VERSION ""

NS_ :

BS_:

BU_: ESR
VAL_TABLE_ VOLVO_SHORT_TRACK_PLANT 1 "Gent" 0 "Torslanda" ;
VAL_TABLE_ Grating_Lobe 1 "Detected" 0 "Not_Detected" ;
VAL_TABLE_ GroupingChanged 1 "GroupingChanged" 0 "GroupingUnchanged" ;
VAL_TABLE_ Oncoming 1 "Oncoming" 0 "NotOncoming" ;
VAL_TABLE_ UPDATED 1 "Updated" 0 "Not_Updated" ;
VAL_TABLE_ FOUND_TARGET 1 "Found" 0 "Not_Found" ;
VAL_TABLE_ FACTORY_ALIGN_STATUS 5 "FAIL_VAR_TOO_LARGE" 4 "FAIL_DEV_TOO_LARGE" 3 "FAIL_NO_TARGET" 2 "SUCCESS" 1 "BUSY" 0 "OFF" ;
VAL_TABLE_ RECOMMEND 1 "Recommend" 0 "Not_Recommend" ;
VAL_TABLE_ SA_TYPE 1 "VOLVO_SHORT_TRACK" 0 "AUTO_OR_DEALER" ;
VAL_TABLE_ ENABLE 1 "Enabled" 0 "Disabled" ;
VAL_TABLE_ CONVERGED 1 "Converged" 0 "Not_Converged" ;
VAL_TABLE_ WHEEL_SLIP 3 "Invalid_3" 2 "Traction_Slip_Control" 1 "Brake_Slip_Control" 0 "No_Control" ;
VAL_TABLE_ TURN_SIGNAL_STATUS 3 "Invalid_3" 2 "Right" 1 "Left" 0 "Off" ;
VAL_TABLE_ DISABLE 1 "Disabled" 0 "Enabled" ;
VAL_TABLE_ SYSTEM_POWER_MODE 7 "7invalid" 6 "TEST" 5 "HOST_SHUTDOWN" 4 "DSP_OFF" 3 "DSP_SHUTDOWN" 2 "RADIATE_ON" 1 "RADIATE_OFF" 0 "DSP_INIT" ;
VAL_TABLE_ Water_Spray_Detected 1 "Spray" 0 "No_Spray" ;
VAL_TABLE_ Bridge 1 "Bridge" 0 "Not_Bridge" ;
VAL_TABLE_ MED_RANGE_MODE 3 "Both_MR_LR_Update" 2 "LR_Update_Only" 1 "MR_Update_Only" 0 "No_MR_LR_Update" ;
VAL_TABLE_ Interface_Version 15 "zInvalid0F" 14 "zInvalid0E" 13 "zInvalid0D" 12 "zInvalid0C" 11 "zInvalid0B" 10 "zInvalid0A" 9 "zInvalid09" 8 "zInvalid08" 7 "zInvalid07" 6 "zInvalid06" 5 "zInvalid05" 4 "zInvalid04" 3 "zInvalid03" 2 "zInvalid02" 1 "ADP_DV1" 0 "TDP" ;
VAL_TABLE_ SIM_STATUS 3 "Coasted" 2 "Updated" 1 "New" 0 "Invalid" ;
VAL_TABLE_ SIM_TRACK_ID 2 "Target_2" 1 "Target_1" 0 "No_Target" ;
VAL_TABLE_ SIM_FUNCTION 7 "All_Stat_RI_FCW_CMbB" 6 "All_Moving_ACC_FCW_CMbB" 5 "CMbB_Stat" 4 "CMbB_Move" 3 "FCW_Stat" 2 "FCW_Move" 1 "RI" 0 "ACC" ;
VAL_TABLE_ UPSIDE_DOWN 1 "Upside_Down" 0 "Right_Side_Up" ;
VAL_TABLE_ MR_LR_MODE 3 "Output MR and LR tracks" 2 "Output only LR-range tracks" 1 "Output only MR-range tracks" 0 "Reserved" ;
VAL_TABLE_ GROUP 3 "Group4" 2 "Group3" 1 "Group2" 0 "Group1" ;
VAL_TABLE_ NODETECT_DETECT 1 "Detect" 0 "No_Detect" ;
VAL_TABLE_ TRACK_STATUS 7 "New_Coasted_Target" 6 "Invalid_Coasted_Target" 5 "Merged_Target" 4 "Coasted_Target" 3 "Updated_Target" 2 "New_Updated_Target" 1 "New_Target" 0 "No_Target" ;
VAL_TABLE_ NOTCROSSING_CROSSING 1 "Crossing" 0 "Not_Crossing" ;
VAL_TABLE_ NOTMOVABLE_MOVABLE 1 "Movable" 0 "Not_Movable" ;
VAL_TABLE_ STATIONARY_MOVING 1 "Moving" 0 "Stationary" ;
VAL_TABLE_ NOTOVERTEMP_OVERTEMP 1 "OverTemp" 0 "Not OverTemp" ;
VAL_TABLE_ NOTBLOCKED_BLOCKED 1 "Blocked" 0 "Not Blocked" ;
VAL_TABLE_ NOTFAIL_FAIL 1 "Failed" 0 "Not Failed" ;
VAL_TABLE_ UNGROUPED_GROUPED 3 "Group_Moving_Stationary" 2 "Group_Stationary_Only" 1 "Group_Moving_Only" 0 "No_Grouping" ;
VAL_TABLE_ FILTERED_RAW 1 "Raw" 0 "Filtered" ;
VAL_TABLE_ OFF_ON 1 "On" 0 "Off" ;
VAL_TABLE_ SW_SIGN 1 "Clockwise" 0 "Counterclockwise" ;
VAL_TABLE_ VALIDITY 1 "Valid" 0 "Invalid" ;
VAL_TABLE_ VEHICLE_SPEED_DIRECTION 1 "Reverse" 0 "Forward" ;

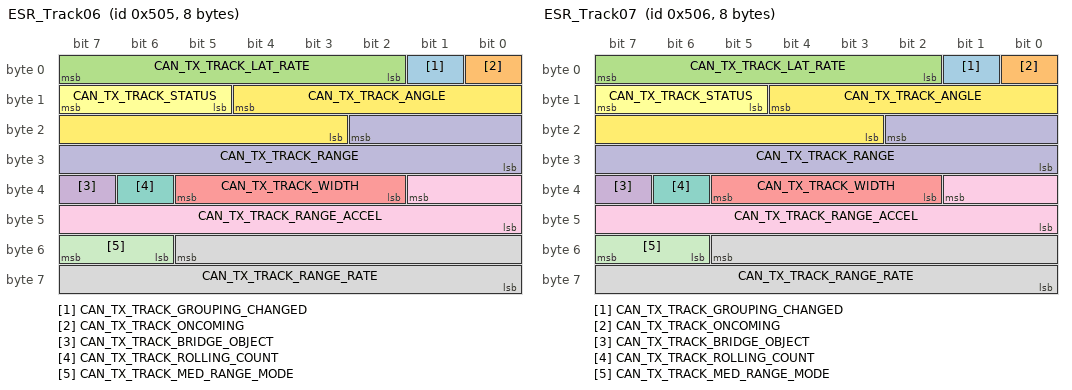
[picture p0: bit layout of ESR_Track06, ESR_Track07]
BO_ 1285 ESR_Track06: 8 Vector__XXX
 SG_ CAN_TX_TRACK_GROUPING_CHANGED : 1|1@0+ (1,0) [0|0] ""  ESR
 SG_ CAN_TX_TRACK_ONCOMING : 0|1@0+ (1,0) [0|0] ""  ESR
 SG_ CAN_TX_TRACK_LAT_RATE : 7|6@0- (0.25,0) [-8|7.75] ""  ESR
 SG_ CAN_TX_TRACK_BRIDGE_OBJECT : 39|1@0+ (1,0) [0|0] ""  ESR
 SG_ CAN_TX_TRACK_WIDTH : 37|4@0+ (0.5,0) [0|7.5] "m"  ESR
 SG_ CAN_TX_TRACK_STATUS : 15|3@0+ (1,0) [0|7] ""  ESR
 SG_ CAN_TX_TRACK_ROLLING_COUNT : 38|1@0+ (1,0) [0|1] ""  ESR
 SG_ CAN_TX_TRACK_RANGE_RATE : 53|14@0- (0.01,0) [-81.92|81.91] "m/s"  ESR
 SG_ CAN_TX_TRACK_RANGE_ACCEL : 33|10@0- (0.05,0) [-25.6|25.55] "m/s/s"  ESR
 SG_ CAN_TX_TRACK_RANGE : 18|11@0+ (0.1,0) [0|204.7] "m"  ESR
 SG_ CAN_TX_TRACK_MED_RANGE_MODE : 55|2@0+ (1,0) [0|3] ""  ESR
 SG_ CAN_TX_TRACK_ANGLE : 12|10@0- (0.1,0) [-51.2|51.1] "deg"  ESR

BO_ 1286 ESR_Track07: 8 Vector__XXX
 SG_ CAN_TX_TRACK_GROUPING_CHANGED : 1|1@0+ (1,0) [0|0] ""  ESR
 SG_ CAN_TX_TRACK_ONCOMING : 0|1@0+ (1,0) [0|0] ""  ESR
 SG_ CAN_TX_TRACK_LAT_RATE : 7|6@0- (0.25,0) [-8|7.75] ""  ESR
 SG_ CAN_TX_TRACK_BRIDGE_OBJECT : 39|1@0+ (1,0) [0|0] ""  ESR
 SG_ CAN_TX_TRACK_WIDTH : 37|4@0+ (0.5,0) [0|7.5] "m"  ESR
 SG_ CAN_TX_TRACK_STATUS : 15|3@0+ (1,0) [0|7] ""  ESR
 SG_ CAN_TX_TRACK_ROLLING_COUNT : 38|1@0+ (1,0) [0|1] ""  ESR
 SG_ CAN_TX_TRACK_RANGE_RATE : 53|14@0- (0.01,0) [-81.92|81.91] "m/s"  ESR
 SG_ CAN_TX_TRACK_RANGE_ACCEL : 33|10@0- (0.05,0) [-25.6|25.55] "m/s/s"  ESR
 SG_ CAN_TX_TRACK_RANGE : 18|11@0+ (0.1,0) [0|204.7] "m"  ESR
 SG_ CAN_TX_TRACK_MED_RANGE_MODE : 55|2@0+ (1,0) [0|3] ""  ESR
 SG_ CAN_TX_TRACK_ANGLE : 12|10@0- (0.1,0) [-51.2|51.1] "deg"  ESR

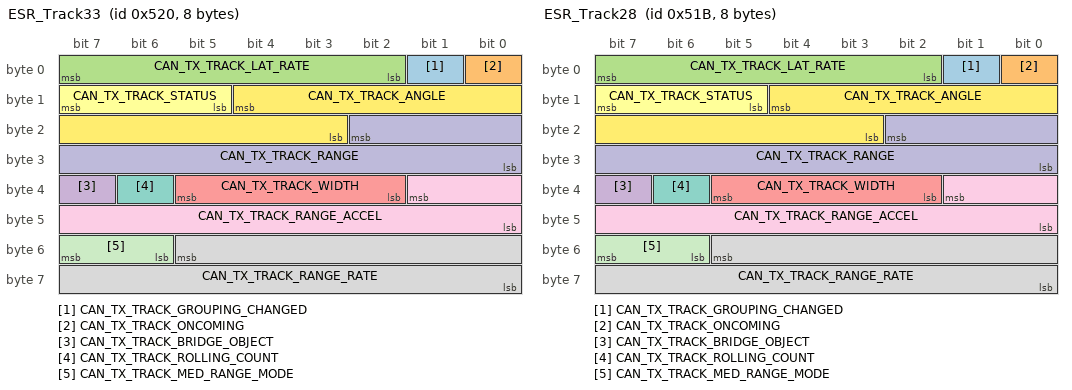
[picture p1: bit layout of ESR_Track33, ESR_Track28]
BO_ 1312 ESR_Track33: 8 Vector__XXX
 SG_ CAN_TX_TRACK_GROUPING_CHANGED : 1|1@0+ (1,0) [0|0] ""  ESR
 SG_ CAN_TX_TRACK_ONCOMING : 0|1@0+ (1,0) [0|0] ""  ESR
 SG_ CAN_TX_TRACK_LAT_RATE : 7|6@0- (0.25,0) [-8|7.75] ""  ESR
 SG_ CAN_TX_TRACK_BRIDGE_OBJECT : 39|1@0+ (1,0) [0|0] ""  ESR
 SG_ CAN_TX_TRACK_WIDTH : 37|4@0+ (0.5,0) [0|7.5] "m"  ESR
 SG_ CAN_TX_TRACK_STATUS : 15|3@0+ (1,0) [0|7] ""  ESR
 SG_ CAN_TX_TRACK_ROLLING_COUNT : 38|1@0+ (1,0) [0|1] ""  ESR
 SG_ CAN_TX_TRACK_RANGE_RATE : 53|14@0- (0.01,0) [-81.92|81.91] "m/s"  ESR
 SG_ CAN_TX_TRACK_RANGE_ACCEL : 33|10@0- (0.05,0) [-25.6|25.55] "m/s/s"  ESR
 SG_ CAN_TX_TRACK_RANGE : 18|11@0+ (0.1,0) [0|204.7] "m"  ESR
 SG_ CAN_TX_TRACK_MED_RANGE_MODE : 55|2@0+ (1,0) [0|3] ""  ESR
 SG_ CAN_TX_TRACK_ANGLE : 12|10@0- (0.1,0) [-51.2|51.1] "deg"  ESR

BO_ 1307 ESR_Track28: 8 Vector__XXX
 SG_ CAN_TX_TRACK_GROUPING_CHANGED : 1|1@0+ (1,0) [0|0] ""  ESR
 SG_ CAN_TX_TRACK_ONCOMING : 0|1@0+ (1,0) [0|0] ""  ESR
 SG_ CAN_TX_TRACK_LAT_RATE : 7|6@0- (0.25,0) [-8|7.75] ""  ESR
 SG_ CAN_TX_TRACK_BRIDGE_OBJECT : 39|1@0+ (1,0) [0|0] ""  ESR
 SG_ CAN_TX_TRACK_WIDTH : 37|4@0+ (0.5,0) [0|7.5] "m"  ESR
 SG_ CAN_TX_TRACK_STATUS : 15|3@0+ (1,0) [0|7] ""  ESR
 SG_ CAN_TX_TRACK_ROLLING_COUNT : 38|1@0+ (1,0) [0|1] ""  ESR
 SG_ CAN_TX_TRACK_RANGE_RATE : 53|14@0- (0.01,0) [-81.92|81.91] "m/s"  ESR
 SG_ CAN_TX_TRACK_RANGE_ACCEL : 33|10@0- (0.05,0) [-25.6|25.55] "m/s/s"  ESR
 SG_ CAN_TX_TRACK_RANGE : 18|11@0+ (0.1,0) [0|204.7] "m"  ESR
 SG_ CAN_TX_TRACK_MED_RANGE_MODE : 55|2@0+ (1,0) [0|3] ""  ESR
 SG_ CAN_TX_TRACK_ANGLE : 12|10@0- (0.1,0) [-51.2|51.1] "deg"  ESR

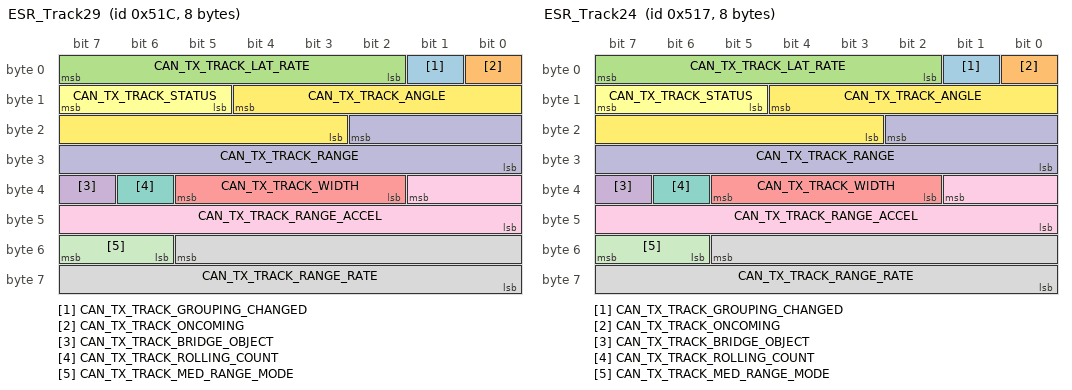
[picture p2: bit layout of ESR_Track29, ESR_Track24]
BO_ 1308 ESR_Track29: 8 Vector__XXX
 SG_ CAN_TX_TRACK_GROUPING_CHANGED : 1|1@0+ (1,0) [0|0] ""  ESR
 SG_ CAN_TX_TRACK_ONCOMING : 0|1@0+ (1,0) [0|0] ""  ESR
 SG_ CAN_TX_TRACK_LAT_RATE : 7|6@0- (0.25,0) [-8|7.75] ""  ESR
 SG_ CAN_TX_TRACK_BRIDGE_OBJECT : 39|1@0+ (1,0) [0|0] ""  ESR
 SG_ CAN_TX_TRACK_WIDTH : 37|4@0+ (0.5,0) [0|7.5] "m"  ESR
 SG_ CAN_TX_TRACK_STATUS : 15|3@0+ (1,0) [0|7] ""  ESR
 SG_ CAN_TX_TRACK_ROLLING_COUNT : 38|1@0+ (1,0) [0|1] ""  ESR
 SG_ CAN_TX_TRACK_RANGE_RATE : 53|14@0- (0.01,0) [-81.92|81.91] "m/s"  ESR
 SG_ CAN_TX_TRACK_RANGE_ACCEL : 33|10@0- (0.05,0) [-25.6|25.55] "m/s/s"  ESR
 SG_ CAN_TX_TRACK_RANGE : 18|11@0+ (0.1,0) [0|204.7] "m"  ESR
 SG_ CAN_TX_TRACK_MED_RANGE_MODE : 55|2@0+ (1,0) [0|3] ""  ESR
 SG_ CAN_TX_TRACK_ANGLE : 12|10@0- (0.1,0) [-51.2|51.1] "deg"  ESR

BO_ 1303 ESR_Track24: 8 Vector__XXX
 SG_ CAN_TX_TRACK_GROUPING_CHANGED : 1|1@0+ (1,0) [0|0] ""  ESR
 SG_ CAN_TX_TRACK_ONCOMING : 0|1@0+ (1,0) [0|0] ""  ESR
 SG_ CAN_TX_TRACK_LAT_RATE : 7|6@0- (0.25,0) [-8|7.75] ""  ESR
 SG_ CAN_TX_TRACK_BRIDGE_OBJECT : 39|1@0+ (1,0) [0|0] ""  ESR
 SG_ CAN_TX_TRACK_WIDTH : 37|4@0+ (0.5,0) [0|7.5] "m"  ESR
 SG_ CAN_TX_TRACK_STATUS : 15|3@0+ (1,0) [0|7] ""  ESR
 SG_ CAN_TX_TRACK_ROLLING_COUNT : 38|1@0+ (1,0) [0|1] ""  ESR
 SG_ CAN_TX_TRACK_RANGE_RATE : 53|14@0- (0.01,0) [-81.92|81.91] "m/s"  ESR
 SG_ CAN_TX_TRACK_RANGE_ACCEL : 33|10@0- (0.05,0) [-25.6|25.55] "m/s/s"  ESR
 SG_ CAN_TX_TRACK_RANGE : 18|11@0+ (0.1,0) [0|204.7] "m"  ESR
 SG_ CAN_TX_TRACK_MED_RANGE_MODE : 55|2@0+ (1,0) [0|3] ""  ESR
 SG_ CAN_TX_TRACK_ANGLE : 12|10@0- (0.1,0) [-51.2|51.1] "deg"  ESR

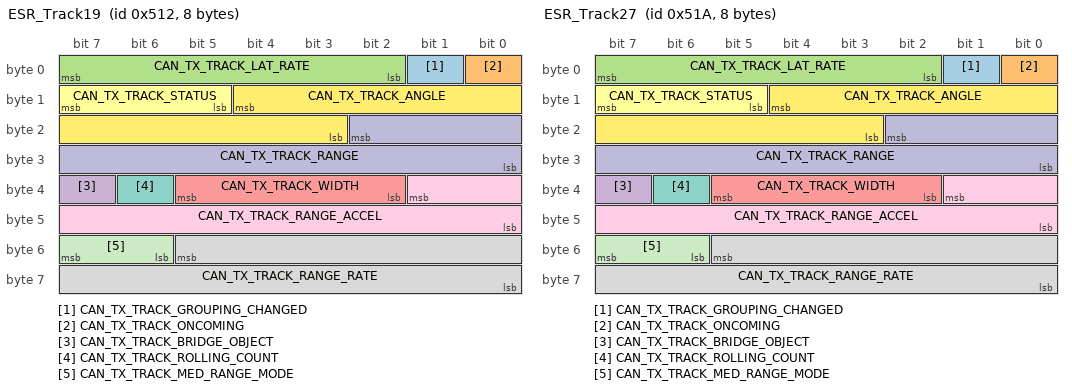
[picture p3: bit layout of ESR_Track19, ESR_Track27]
BO_ 1298 ESR_Track19: 8 Vector__XXX
 SG_ CAN_TX_TRACK_GROUPING_CHANGED : 1|1@0+ (1,0) [0|0] ""  ESR
 SG_ CAN_TX_TRACK_ONCOMING : 0|1@0+ (1,0) [0|0] ""  ESR
 SG_ CAN_TX_TRACK_LAT_RATE : 7|6@0- (0.25,0) [-8|7.75] ""  ESR
 SG_ CAN_TX_TRACK_BRIDGE_OBJECT : 39|1@0+ (1,0) [0|0] ""  ESR
 SG_ CAN_TX_TRACK_WIDTH : 37|4@0+ (0.5,0) [0|7.5] "m"  ESR
 SG_ CAN_TX_TRACK_STATUS : 15|3@0+ (1,0) [0|7] ""  ESR
 SG_ CAN_TX_TRACK_ROLLING_COUNT : 38|1@0+ (1,0) [0|1] ""  ESR
 SG_ CAN_TX_TRACK_RANGE_RATE : 53|14@0- (0.01,0) [-81.92|81.91] "m/s"  ESR
 SG_ CAN_TX_TRACK_RANGE_ACCEL : 33|10@0- (0.05,0) [-25.6|25.55] "m/s/s"  ESR
 SG_ CAN_TX_TRACK_RANGE : 18|11@0+ (0.1,0) [0|204.7] "m"  ESR
 SG_ CAN_TX_TRACK_MED_RANGE_MODE : 55|2@0+ (1,0) [0|3] ""  ESR
 SG_ CAN_TX_TRACK_ANGLE : 12|10@0- (0.1,0) [-51.2|51.1] "deg"  ESR

BO_ 1306 ESR_Track27: 8 Vector__XXX
 SG_ CAN_TX_TRACK_GROUPING_CHANGED : 1|1@0+ (1,0) [0|0] ""  ESR
 SG_ CAN_TX_TRACK_ONCOMING : 0|1@0+ (1,0) [0|0] ""  ESR
 SG_ CAN_TX_TRACK_LAT_RATE : 7|6@0- (0.25,0) [-8|7.75] ""  ESR
 SG_ CAN_TX_TRACK_BRIDGE_OBJECT : 39|1@0+ (1,0) [0|0] ""  ESR
 SG_ CAN_TX_TRACK_WIDTH : 37|4@0+ (0.5,0) [0|7.5] "m"  ESR
 SG_ CAN_TX_TRACK_STATUS : 15|3@0+ (1,0) [0|7] ""  ESR
 SG_ CAN_TX_TRACK_ROLLING_COUNT : 38|1@0+ (1,0) [0|1] ""  ESR
 SG_ CAN_TX_TRACK_RANGE_RATE : 53|14@0- (0.01,0) [-81.92|81.91] "m/s"  ESR
 SG_ CAN_TX_TRACK_RANGE_ACCEL : 33|10@0- (0.05,0) [-25.6|25.55] "m/s/s"  ESR
 SG_ CAN_TX_TRACK_RANGE : 18|11@0+ (0.1,0) [0|204.7] "m"  ESR
 SG_ CAN_TX_TRACK_MED_RANGE_MODE : 55|2@0+ (1,0) [0|3] ""  ESR
 SG_ CAN_TX_TRACK_ANGLE : 12|10@0- (0.1,0) [-51.2|51.1] "deg"  ESR

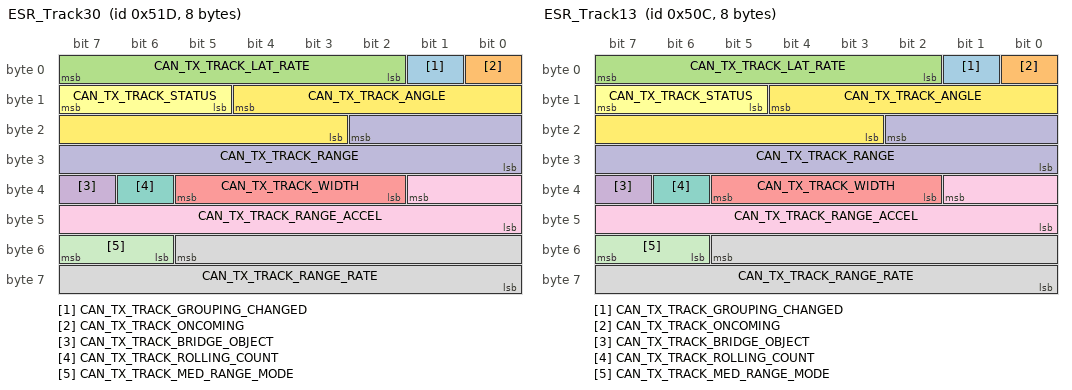
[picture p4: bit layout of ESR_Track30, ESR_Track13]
BO_ 1309 ESR_Track30: 8 Vector__XXX
 SG_ CAN_TX_TRACK_GROUPING_CHANGED : 1|1@0+ (1,0) [0|0] ""  ESR
 SG_ CAN_TX_TRACK_ONCOMING : 0|1@0+ (1,0) [0|0] ""  ESR
 SG_ CAN_TX_TRACK_LAT_RATE : 7|6@0- (0.25,0) [-8|7.75] ""  ESR
 SG_ CAN_TX_TRACK_BRIDGE_OBJECT : 39|1@0+ (1,0) [0|0] ""  ESR
 SG_ CAN_TX_TRACK_WIDTH : 37|4@0+ (0.5,0) [0|7.5] "m"  ESR
 SG_ CAN_TX_TRACK_STATUS : 15|3@0+ (1,0) [0|7] ""  ESR
 SG_ CAN_TX_TRACK_ROLLING_COUNT : 38|1@0+ (1,0) [0|1] ""  ESR
 SG_ CAN_TX_TRACK_RANGE_RATE : 53|14@0- (0.01,0) [-81.92|81.91] "m/s"  ESR
 SG_ CAN_TX_TRACK_RANGE_ACCEL : 33|10@0- (0.05,0) [-25.6|25.55] "m/s/s"  ESR
 SG_ CAN_TX_TRACK_RANGE : 18|11@0+ (0.1,0) [0|204.7] "m"  ESR
 SG_ CAN_TX_TRACK_MED_RANGE_MODE : 55|2@0+ (1,0) [0|3] ""  ESR
 SG_ CAN_TX_TRACK_ANGLE : 12|10@0- (0.1,0) [-51.2|51.1] "deg"  ESR

BO_ 1292 ESR_Track13: 8 Vector__XXX
 SG_ CAN_TX_TRACK_GROUPING_CHANGED : 1|1@0+ (1,0) [0|0] ""  ESR
 SG_ CAN_TX_TRACK_ONCOMING : 0|1@0+ (1,0) [0|0] ""  ESR
 SG_ CAN_TX_TRACK_LAT_RATE : 7|6@0- (0.25,0) [-8|7.75] ""  ESR
 SG_ CAN_TX_TRACK_BRIDGE_OBJECT : 39|1@0+ (1,0) [0|0] ""  ESR
 SG_ CAN_TX_TRACK_WIDTH : 37|4@0+ (0.5,0) [0|7.5] "m"  ESR
 SG_ CAN_TX_TRACK_STATUS : 15|3@0+ (1,0) [0|7] ""  ESR
 SG_ CAN_TX_TRACK_ROLLING_COUNT : 38|1@0+ (1,0) [0|1] ""  ESR
 SG_ CAN_TX_TRACK_RANGE_RATE : 53|14@0- (0.01,0) [-81.92|81.91] "m/s"  ESR
 SG_ CAN_TX_TRACK_RANGE_ACCEL : 33|10@0- (0.05,0) [-25.6|25.55] "m/s/s"  ESR
 SG_ CAN_TX_TRACK_RANGE : 18|11@0+ (0.1,0) [0|204.7] "m"  ESR
 SG_ CAN_TX_TRACK_MED_RANGE_MODE : 55|2@0+ (1,0) [0|3] ""  ESR
 SG_ CAN_TX_TRACK_ANGLE : 12|10@0- (0.1,0) [-51.2|51.1] "deg"  ESR

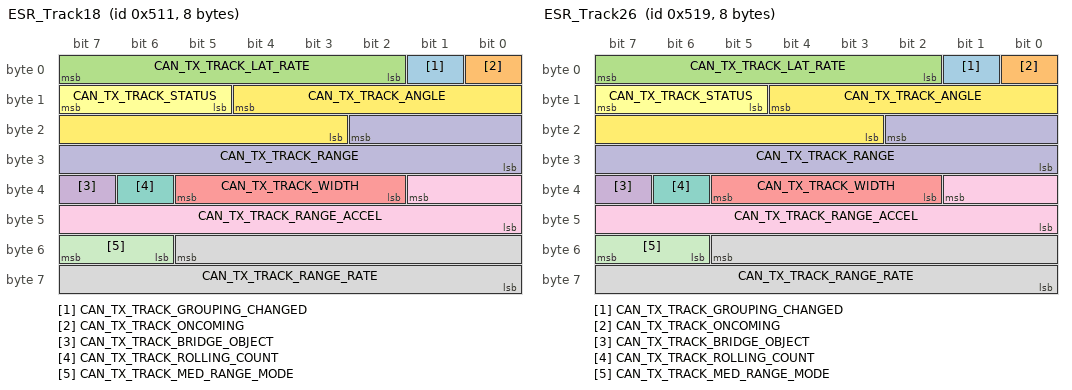
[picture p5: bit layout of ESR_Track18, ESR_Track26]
BO_ 1297 ESR_Track18: 8 Vector__XXX
 SG_ CAN_TX_TRACK_GROUPING_CHANGED : 1|1@0+ (1,0) [0|0] ""  ESR
 SG_ CAN_TX_TRACK_ONCOMING : 0|1@0+ (1,0) [0|0] ""  ESR
 SG_ CAN_TX_TRACK_LAT_RATE : 7|6@0- (0.25,0) [-8|7.75] ""  ESR
 SG_ CAN_TX_TRACK_BRIDGE_OBJECT : 39|1@0+ (1,0) [0|0] ""  ESR
 SG_ CAN_TX_TRACK_WIDTH : 37|4@0+ (0.5,0) [0|7.5] "m"  ESR
 SG_ CAN_TX_TRACK_STATUS : 15|3@0+ (1,0) [0|7] ""  ESR
 SG_ CAN_TX_TRACK_ROLLING_COUNT : 38|1@0+ (1,0) [0|1] ""  ESR
 SG_ CAN_TX_TRACK_RANGE_RATE : 53|14@0- (0.01,0) [-81.92|81.91] "m/s"  ESR
 SG_ CAN_TX_TRACK_RANGE_ACCEL : 33|10@0- (0.05,0) [-25.6|25.55] "m/s/s"  ESR
 SG_ CAN_TX_TRACK_RANGE : 18|11@0+ (0.1,0) [0|204.7] "m"  ESR
 SG_ CAN_TX_TRACK_MED_RANGE_MODE : 55|2@0+ (1,0) [0|3] ""  ESR
 SG_ CAN_TX_TRACK_ANGLE : 12|10@0- (0.1,0) [-51.2|51.1] "deg"  ESR

BO_ 1305 ESR_Track26: 8 Vector__XXX
 SG_ CAN_TX_TRACK_GROUPING_CHANGED : 1|1@0+ (1,0) [0|0] ""  ESR
 SG_ CAN_TX_TRACK_ONCOMING : 0|1@0+ (1,0) [0|0] ""  ESR
 SG_ CAN_TX_TRACK_LAT_RATE : 7|6@0- (0.25,0) [-8|7.75] ""  ESR
 SG_ CAN_TX_TRACK_BRIDGE_OBJECT : 39|1@0+ (1,0) [0|0] ""  ESR
 SG_ CAN_TX_TRACK_WIDTH : 37|4@0+ (0.5,0) [0|7.5] "m"  ESR
 SG_ CAN_TX_TRACK_STATUS : 15|3@0+ (1,0) [0|7] ""  ESR
 SG_ CAN_TX_TRACK_ROLLING_COUNT : 38|1@0+ (1,0) [0|1] ""  ESR
 SG_ CAN_TX_TRACK_RANGE_RATE : 53|14@0- (0.01,0) [-81.92|81.91] "m/s"  ESR
 SG_ CAN_TX_TRACK_RANGE_ACCEL : 33|10@0- (0.05,0) [-25.6|25.55] "m/s/s"  ESR
 SG_ CAN_TX_TRACK_RANGE : 18|11@0+ (0.1,0) [0|204.7] "m"  ESR
 SG_ CAN_TX_TRACK_MED_RANGE_MODE : 55|2@0+ (1,0) [0|3] ""  ESR
 SG_ CAN_TX_TRACK_ANGLE : 12|10@0- (0.1,0) [-51.2|51.1] "deg"  ESR

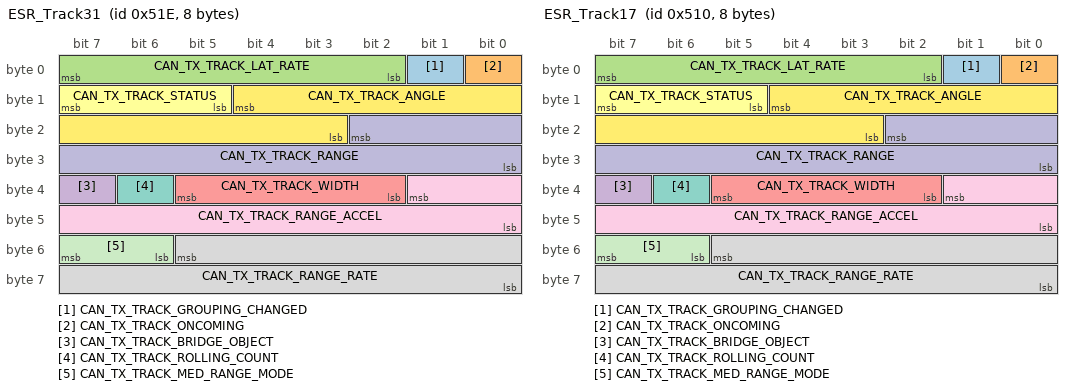
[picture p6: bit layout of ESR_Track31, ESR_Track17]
BO_ 1310 ESR_Track31: 8 Vector__XXX
 SG_ CAN_TX_TRACK_GROUPING_CHANGED : 1|1@0+ (1,0) [0|0] ""  ESR
 SG_ CAN_TX_TRACK_ONCOMING : 0|1@0+ (1,0) [0|0] ""  ESR
 SG_ CAN_TX_TRACK_LAT_RATE : 7|6@0- (0.25,0) [-8|7.75] ""  ESR
 SG_ CAN_TX_TRACK_BRIDGE_OBJECT : 39|1@0+ (1,0) [0|0] ""  ESR
 SG_ CAN_TX_TRACK_WIDTH : 37|4@0+ (0.5,0) [0|7.5] "m"  ESR
 SG_ CAN_TX_TRACK_STATUS : 15|3@0+ (1,0) [0|7] ""  ESR
 SG_ CAN_TX_TRACK_ROLLING_COUNT : 38|1@0+ (1,0) [0|1] ""  ESR
 SG_ CAN_TX_TRACK_RANGE_RATE : 53|14@0- (0.01,0) [-81.92|81.91] "m/s"  ESR
 SG_ CAN_TX_TRACK_RANGE_ACCEL : 33|10@0- (0.05,0) [-25.6|25.55] "m/s/s"  ESR
 SG_ CAN_TX_TRACK_RANGE : 18|11@0+ (0.1,0) [0|204.7] "m"  ESR
 SG_ CAN_TX_TRACK_MED_RANGE_MODE : 55|2@0+ (1,0) [0|3] ""  ESR
 SG_ CAN_TX_TRACK_ANGLE : 12|10@0- (0.1,0) [-51.2|51.1] "deg"  ESR

BO_ 1296 ESR_Track17: 8 Vector__XXX
 SG_ CAN_TX_TRACK_GROUPING_CHANGED : 1|1@0+ (1,0) [0|0] ""  ESR
 SG_ CAN_TX_TRACK_ONCOMING : 0|1@0+ (1,0) [0|0] ""  ESR
 SG_ CAN_TX_TRACK_LAT_RATE : 7|6@0- (0.25,0) [-8|7.75] ""  ESR
 SG_ CAN_TX_TRACK_BRIDGE_OBJECT : 39|1@0+ (1,0) [0|0] ""  ESR
 SG_ CAN_TX_TRACK_WIDTH : 37|4@0+ (0.5,0) [0|7.5] "m"  ESR
 SG_ CAN_TX_TRACK_STATUS : 15|3@0+ (1,0) [0|7] ""  ESR
 SG_ CAN_TX_TRACK_ROLLING_COUNT : 38|1@0+ (1,0) [0|1] ""  ESR
 SG_ CAN_TX_TRACK_RANGE_RATE : 53|14@0- (0.01,0) [-81.92|81.91] "m/s"  ESR
 SG_ CAN_TX_TRACK_RANGE_ACCEL : 33|10@0- (0.05,0) [-25.6|25.55] "m/s/s"  ESR
 SG_ CAN_TX_TRACK_RANGE : 18|11@0+ (0.1,0) [0|204.7] "m"  ESR
 SG_ CAN_TX_TRACK_MED_RANGE_MODE : 55|2@0+ (1,0) [0|3] ""  ESR
 SG_ CAN_TX_TRACK_ANGLE : 12|10@0- (0.1,0) [-51.2|51.1] "deg"  ESR

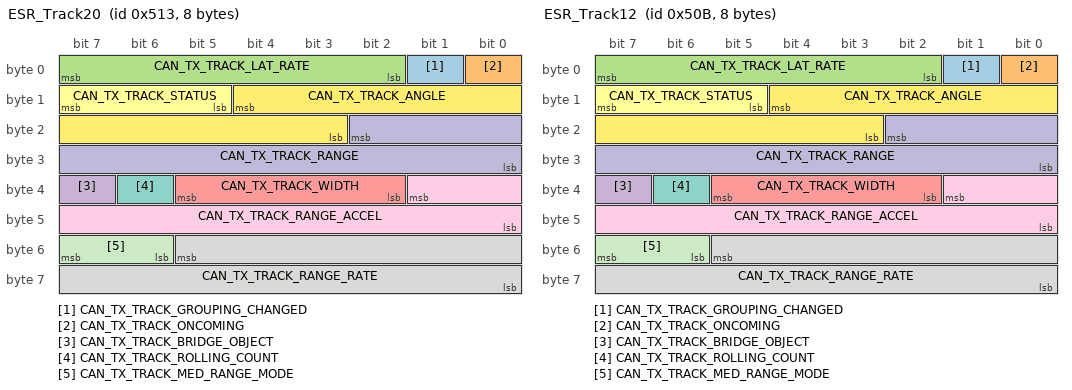
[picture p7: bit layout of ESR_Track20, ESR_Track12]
BO_ 1299 ESR_Track20: 8 Vector__XXX
 SG_ CAN_TX_TRACK_GROUPING_CHANGED : 1|1@0+ (1,0) [0|0] ""  ESR
 SG_ CAN_TX_TRACK_ONCOMING : 0|1@0+ (1,0) [0|0] ""  ESR
 SG_ CAN_TX_TRACK_LAT_RATE : 7|6@0- (0.25,0) [-8|7.75] ""  ESR
 SG_ CAN_TX_TRACK_BRIDGE_OBJECT : 39|1@0+ (1,0) [0|0] ""  ESR
 SG_ CAN_TX_TRACK_WIDTH : 37|4@0+ (0.5,0) [0|7.5] "m"  ESR
 SG_ CAN_TX_TRACK_STATUS : 15|3@0+ (1,0) [0|7] ""  ESR
 SG_ CAN_TX_TRACK_ROLLING_COUNT : 38|1@0+ (1,0) [0|1] ""  ESR
 SG_ CAN_TX_TRACK_RANGE_RATE : 53|14@0- (0.01,0) [-81.92|81.91] "m/s"  ESR
 SG_ CAN_TX_TRACK_RANGE_ACCEL : 33|10@0- (0.05,0) [-25.6|25.55] "m/s/s"  ESR
 SG_ CAN_TX_TRACK_RANGE : 18|11@0+ (0.1,0) [0|204.7] "m"  ESR
 SG_ CAN_TX_TRACK_MED_RANGE_MODE : 55|2@0+ (1,0) [0|3] ""  ESR
 SG_ CAN_TX_TRACK_ANGLE : 12|10@0- (0.1,0) [-51.2|51.1] "deg"  ESR

BO_ 1291 ESR_Track12: 8 Vector__XXX
 SG_ CAN_TX_TRACK_GROUPING_CHANGED : 1|1@0+ (1,0) [0|0] ""  ESR
 SG_ CAN_TX_TRACK_ONCOMING : 0|1@0+ (1,0) [0|0] ""  ESR
 SG_ CAN_TX_TRACK_LAT_RATE : 7|6@0- (0.25,0) [-8|7.75] ""  ESR
 SG_ CAN_TX_TRACK_BRIDGE_OBJECT : 39|1@0+ (1,0) [0|0] ""  ESR
 SG_ CAN_TX_TRACK_WIDTH : 37|4@0+ (0.5,0) [0|7.5] "m"  ESR
 SG_ CAN_TX_TRACK_STATUS : 15|3@0+ (1,0) [0|7] ""  ESR
 SG_ CAN_TX_TRACK_ROLLING_COUNT : 38|1@0+ (1,0) [0|1] ""  ESR
 SG_ CAN_TX_TRACK_RANGE_RATE : 53|14@0- (0.01,0) [-81.92|81.91] "m/s"  ESR
 SG_ CAN_TX_TRACK_RANGE_ACCEL : 33|10@0- (0.05,0) [-25.6|25.55] "m/s/s"  ESR
 SG_ CAN_TX_TRACK_RANGE : 18|11@0+ (0.1,0) [0|204.7] "m"  ESR
 SG_ CAN_TX_TRACK_MED_RANGE_MODE : 55|2@0+ (1,0) [0|3] ""  ESR
 SG_ CAN_TX_TRACK_ANGLE : 12|10@0- (0.1,0) [-51.2|51.1] "deg"  ESR

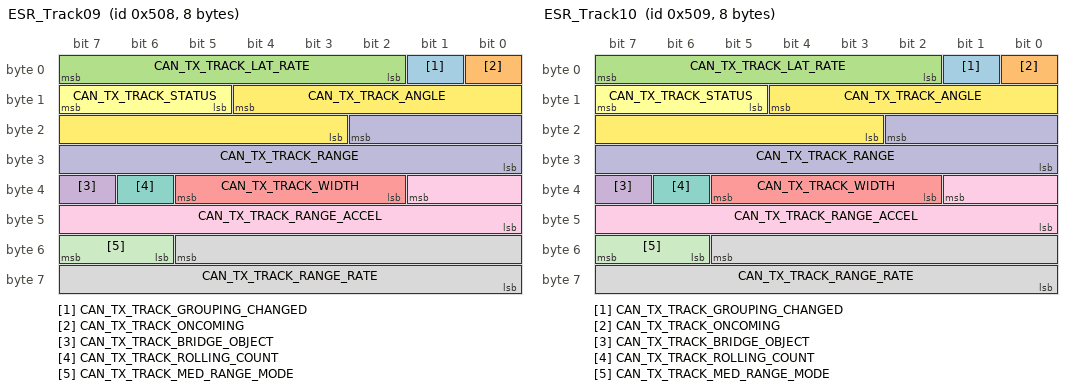
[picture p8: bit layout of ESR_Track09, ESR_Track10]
BO_ 1288 ESR_Track09: 8 Vector__XXX
 SG_ CAN_TX_TRACK_GROUPING_CHANGED : 1|1@0+ (1,0) [0|0] ""  ESR
 SG_ CAN_TX_TRACK_ONCOMING : 0|1@0+ (1,0) [0|0] ""  ESR
 SG_ CAN_TX_TRACK_LAT_RATE : 7|6@0- (0.25,0) [-8|7.75] ""  ESR
 SG_ CAN_TX_TRACK_BRIDGE_OBJECT : 39|1@0+ (1,0) [0|0] ""  ESR
 SG_ CAN_TX_TRACK_WIDTH : 37|4@0+ (0.5,0) [0|7.5] "m"  ESR
 SG_ CAN_TX_TRACK_STATUS : 15|3@0+ (1,0) [0|7] ""  ESR
 SG_ CAN_TX_TRACK_ROLLING_COUNT : 38|1@0+ (1,0) [0|1] ""  ESR
 SG_ CAN_TX_TRACK_RANGE_RATE : 53|14@0- (0.01,0) [-81.92|81.91] "m/s"  ESR
 SG_ CAN_TX_TRACK_RANGE_ACCEL : 33|10@0- (0.05,0) [-25.6|25.55] "m/s/s"  ESR
 SG_ CAN_TX_TRACK_RANGE : 18|11@0+ (0.1,0) [0|204.7] "m"  ESR
 SG_ CAN_TX_TRACK_MED_RANGE_MODE : 55|2@0+ (1,0) [0|3] ""  ESR
 SG_ CAN_TX_TRACK_ANGLE : 12|10@0- (0.1,0) [-51.2|51.1] "deg"  ESR

BO_ 1289 ESR_Track10: 8 Vector__XXX
 SG_ CAN_TX_TRACK_GROUPING_CHANGED : 1|1@0+ (1,0) [0|0] ""  ESR
 SG_ CAN_TX_TRACK_ONCOMING : 0|1@0+ (1,0) [0|0] ""  ESR
 SG_ CAN_TX_TRACK_LAT_RATE : 7|6@0- (0.25,0) [-8|7.75] ""  ESR
 SG_ CAN_TX_TRACK_BRIDGE_OBJECT : 39|1@0+ (1,0) [0|0] ""  ESR
 SG_ CAN_TX_TRACK_WIDTH : 37|4@0+ (0.5,0) [0|7.5] "m"  ESR
 SG_ CAN_TX_TRACK_STATUS : 15|3@0+ (1,0) [0|7] ""  ESR
 SG_ CAN_TX_TRACK_ROLLING_COUNT : 38|1@0+ (1,0) [0|1] ""  ESR
 SG_ CAN_TX_TRACK_RANGE_RATE : 53|14@0- (0.01,0) [-81.92|81.91] "m/s"  ESR
 SG_ CAN_TX_TRACK_RANGE_ACCEL : 33|10@0- (0.05,0) [-25.6|25.55] "m/s/s"  ESR
 SG_ CAN_TX_TRACK_RANGE : 18|11@0+ (0.1,0) [0|204.7] "m"  ESR
 SG_ CAN_TX_TRACK_MED_RANGE_MODE : 55|2@0+ (1,0) [0|3] ""  ESR
 SG_ CAN_TX_TRACK_ANGLE : 12|10@0- (0.1,0) [-51.2|51.1] "deg"  ESR

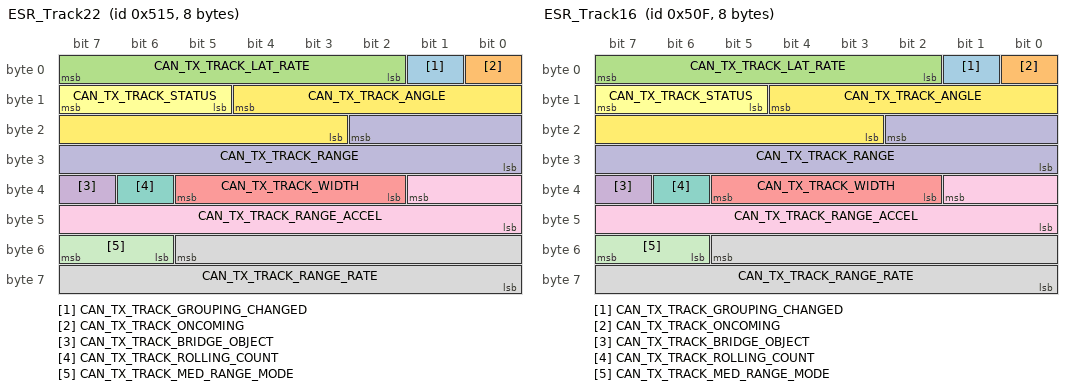
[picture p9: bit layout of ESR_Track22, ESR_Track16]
BO_ 1301 ESR_Track22: 8 Vector__XXX
 SG_ CAN_TX_TRACK_GROUPING_CHANGED : 1|1@0+ (1,0) [0|0] ""  ESR
 SG_ CAN_TX_TRACK_ONCOMING : 0|1@0+ (1,0) [0|0] ""  ESR
 SG_ CAN_TX_TRACK_LAT_RATE : 7|6@0- (0.25,0) [-8|7.75] ""  ESR
 SG_ CAN_TX_TRACK_BRIDGE_OBJECT : 39|1@0+ (1,0) [0|0] ""  ESR
 SG_ CAN_TX_TRACK_WIDTH : 37|4@0+ (0.5,0) [0|7.5] "m"  ESR
 SG_ CAN_TX_TRACK_STATUS : 15|3@0+ (1,0) [0|7] ""  ESR
 SG_ CAN_TX_TRACK_ROLLING_COUNT : 38|1@0+ (1,0) [0|1] ""  ESR
 SG_ CAN_TX_TRACK_RANGE_RATE : 53|14@0- (0.01,0) [-81.92|81.91] "m/s"  ESR
 SG_ CAN_TX_TRACK_RANGE_ACCEL : 33|10@0- (0.05,0) [-25.6|25.55] "m/s/s"  ESR
 SG_ CAN_TX_TRACK_RANGE : 18|11@0+ (0.1,0) [0|204.7] "m"  ESR
 SG_ CAN_TX_TRACK_MED_RANGE_MODE : 55|2@0+ (1,0) [0|3] ""  ESR
 SG_ CAN_TX_TRACK_ANGLE : 12|10@0- (0.1,0) [-51.2|51.1] "deg"  ESR

BO_ 1295 ESR_Track16: 8 Vector__XXX
 SG_ CAN_TX_TRACK_GROUPING_CHANGED : 1|1@0+ (1,0) [0|0] ""  ESR
 SG_ CAN_TX_TRACK_ONCOMING : 0|1@0+ (1,0) [0|0] ""  ESR
 SG_ CAN_TX_TRACK_LAT_RATE : 7|6@0- (0.25,0) [-8|7.75] ""  ESR
 SG_ CAN_TX_TRACK_BRIDGE_OBJECT : 39|1@0+ (1,0) [0|0] ""  ESR
 SG_ CAN_TX_TRACK_WIDTH : 37|4@0+ (0.5,0) [0|7.5] "m"  ESR
 SG_ CAN_TX_TRACK_STATUS : 15|3@0+ (1,0) [0|7] ""  ESR
 SG_ CAN_TX_TRACK_ROLLING_COUNT : 38|1@0+ (1,0) [0|1] ""  ESR
 SG_ CAN_TX_TRACK_RANGE_RATE : 53|14@0- (0.01,0) [-81.92|81.91] "m/s"  ESR
 SG_ CAN_TX_TRACK_RANGE_ACCEL : 33|10@0- (0.05,0) [-25.6|25.55] "m/s/s"  ESR
 SG_ CAN_TX_TRACK_RANGE : 18|11@0+ (0.1,0) [0|204.7] "m"  ESR
 SG_ CAN_TX_TRACK_MED_RANGE_MODE : 55|2@0+ (1,0) [0|3] ""  ESR
 SG_ CAN_TX_TRACK_ANGLE : 12|10@0- (0.1,0) [-51.2|51.1] "deg"  ESR

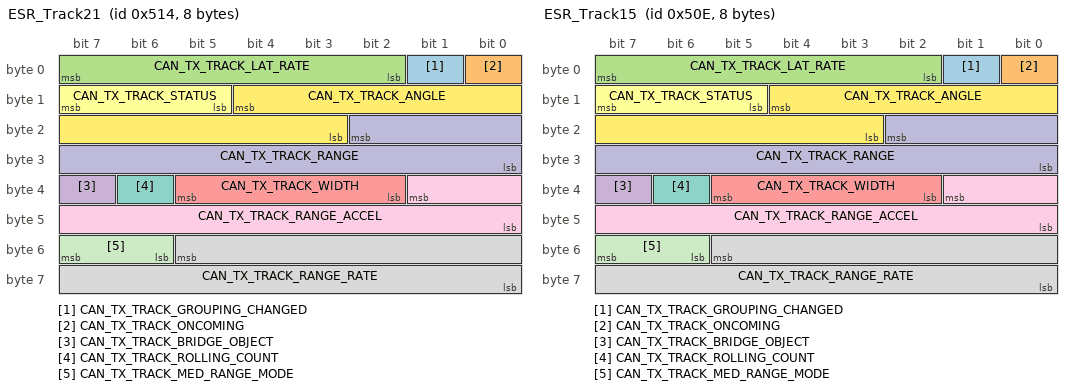
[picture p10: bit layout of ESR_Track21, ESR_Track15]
BO_ 1300 ESR_Track21: 8 Vector__XXX
 SG_ CAN_TX_TRACK_GROUPING_CHANGED : 1|1@0+ (1,0) [0|0] ""  ESR
 SG_ CAN_TX_TRACK_ONCOMING : 0|1@0+ (1,0) [0|0] ""  ESR
 SG_ CAN_TX_TRACK_LAT_RATE : 7|6@0- (0.25,0) [-8|7.75] ""  ESR
 SG_ CAN_TX_TRACK_BRIDGE_OBJECT : 39|1@0+ (1,0) [0|0] ""  ESR
 SG_ CAN_TX_TRACK_WIDTH : 37|4@0+ (0.5,0) [0|7.5] "m"  ESR
 SG_ CAN_TX_TRACK_STATUS : 15|3@0+ (1,0) [0|7] ""  ESR
 SG_ CAN_TX_TRACK_ROLLING_COUNT : 38|1@0+ (1,0) [0|1] ""  ESR
 SG_ CAN_TX_TRACK_RANGE_RATE : 53|14@0- (0.01,0) [-81.92|81.91] "m/s"  ESR
 SG_ CAN_TX_TRACK_RANGE_ACCEL : 33|10@0- (0.05,0) [-25.6|25.55] "m/s/s"  ESR
 SG_ CAN_TX_TRACK_RANGE : 18|11@0+ (0.1,0) [0|204.7] "m"  ESR
 SG_ CAN_TX_TRACK_MED_RANGE_MODE : 55|2@0+ (1,0) [0|3] ""  ESR
 SG_ CAN_TX_TRACK_ANGLE : 12|10@0- (0.1,0) [-51.2|51.1] "deg"  ESR

BO_ 1294 ESR_Track15: 8 Vector__XXX
 SG_ CAN_TX_TRACK_GROUPING_CHANGED : 1|1@0+ (1,0) [0|0] ""  ESR
 SG_ CAN_TX_TRACK_ONCOMING : 0|1@0+ (1,0) [0|0] ""  ESR
 SG_ CAN_TX_TRACK_LAT_RATE : 7|6@0- (0.25,0) [-8|7.75] ""  ESR
 SG_ CAN_TX_TRACK_BRIDGE_OBJECT : 39|1@0+ (1,0) [0|0] ""  ESR
 SG_ CAN_TX_TRACK_WIDTH : 37|4@0+ (0.5,0) [0|7.5] "m"  ESR
 SG_ CAN_TX_TRACK_STATUS : 15|3@0+ (1,0) [0|7] ""  ESR
 SG_ CAN_TX_TRACK_ROLLING_COUNT : 38|1@0+ (1,0) [0|1] ""  ESR
 SG_ CAN_TX_TRACK_RANGE_RATE : 53|14@0- (0.01,0) [-81.92|81.91] "m/s"  ESR
 SG_ CAN_TX_TRACK_RANGE_ACCEL : 33|10@0- (0.05,0) [-25.6|25.55] "m/s/s"  ESR
 SG_ CAN_TX_TRACK_RANGE : 18|11@0+ (0.1,0) [0|204.7] "m"  ESR
 SG_ CAN_TX_TRACK_MED_RANGE_MODE : 55|2@0+ (1,0) [0|3] ""  ESR
 SG_ CAN_TX_TRACK_ANGLE : 12|10@0- (0.1,0) [-51.2|51.1] "deg"  ESR

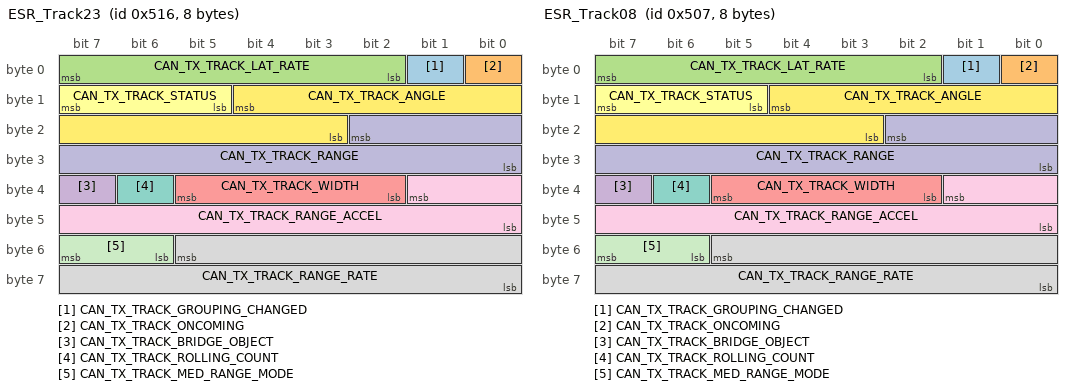
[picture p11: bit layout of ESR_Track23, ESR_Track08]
BO_ 1302 ESR_Track23: 8 Vector__XXX
 SG_ CAN_TX_TRACK_GROUPING_CHANGED : 1|1@0+ (1,0) [0|0] ""  ESR
 SG_ CAN_TX_TRACK_ONCOMING : 0|1@0+ (1,0) [0|0] ""  ESR
 SG_ CAN_TX_TRACK_LAT_RATE : 7|6@0- (0.25,0) [-8|7.75] ""  ESR
 SG_ CAN_TX_TRACK_BRIDGE_OBJECT : 39|1@0+ (1,0) [0|0] ""  ESR
 SG_ CAN_TX_TRACK_WIDTH : 37|4@0+ (0.5,0) [0|7.5] "m"  ESR
 SG_ CAN_TX_TRACK_STATUS : 15|3@0+ (1,0) [0|7] ""  ESR
 SG_ CAN_TX_TRACK_ROLLING_COUNT : 38|1@0+ (1,0) [0|1] ""  ESR
 SG_ CAN_TX_TRACK_RANGE_RATE : 53|14@0- (0.01,0) [-81.92|81.91] "m/s"  ESR
 SG_ CAN_TX_TRACK_RANGE_ACCEL : 33|10@0- (0.05,0) [-25.6|25.55] "m/s/s"  ESR
 SG_ CAN_TX_TRACK_RANGE : 18|11@0+ (0.1,0) [0|204.7] "m"  ESR
 SG_ CAN_TX_TRACK_MED_RANGE_MODE : 55|2@0+ (1,0) [0|3] ""  ESR
 SG_ CAN_TX_TRACK_ANGLE : 12|10@0- (0.1,0) [-51.2|51.1] "deg"  ESR

BO_ 1287 ESR_Track08: 8 Vector__XXX
 SG_ CAN_TX_TRACK_GROUPING_CHANGED : 1|1@0+ (1,0) [0|0] ""  ESR
 SG_ CAN_TX_TRACK_ONCOMING : 0|1@0+ (1,0) [0|0] ""  ESR
 SG_ CAN_TX_TRACK_LAT_RATE : 7|6@0- (0.25,0) [-8|7.75] ""  ESR
 SG_ CAN_TX_TRACK_BRIDGE_OBJECT : 39|1@0+ (1,0) [0|0] ""  ESR
 SG_ CAN_TX_TRACK_WIDTH : 37|4@0+ (0.5,0) [0|7.5] "m"  ESR
 SG_ CAN_TX_TRACK_STATUS : 15|3@0+ (1,0) [0|7] ""  ESR
 SG_ CAN_TX_TRACK_ROLLING_COUNT : 38|1@0+ (1,0) [0|1] ""  ESR
 SG_ CAN_TX_TRACK_RANGE_RATE : 53|14@0- (0.01,0) [-81.92|81.91] "m/s"  ESR
 SG_ CAN_TX_TRACK_RANGE_ACCEL : 33|10@0- (0.05,0) [-25.6|25.55] "m/s/s"  ESR
 SG_ CAN_TX_TRACK_RANGE : 18|11@0+ (0.1,0) [0|204.7] "m"  ESR
 SG_ CAN_TX_TRACK_MED_RANGE_MODE : 55|2@0+ (1,0) [0|3] ""  ESR
 SG_ CAN_TX_TRACK_ANGLE : 12|10@0- (0.1,0) [-51.2|51.1] "deg"  ESR

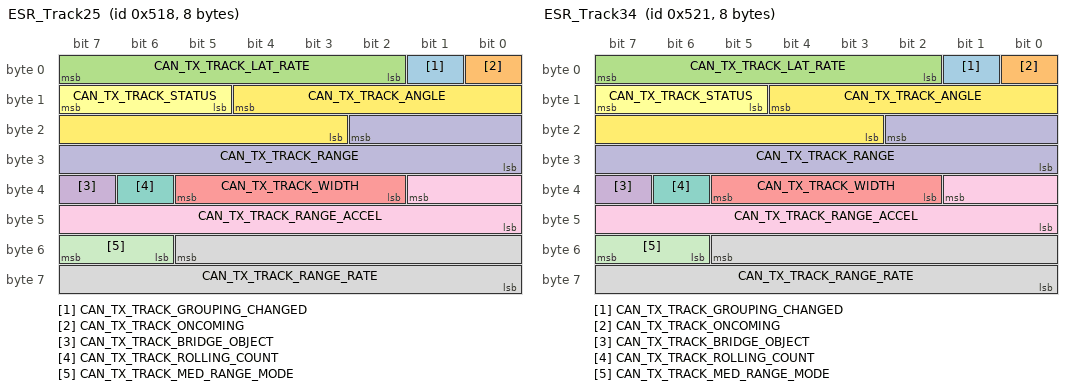
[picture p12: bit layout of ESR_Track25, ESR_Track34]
BO_ 1304 ESR_Track25: 8 Vector__XXX
 SG_ CAN_TX_TRACK_GROUPING_CHANGED : 1|1@0+ (1,0) [0|0] ""  ESR
 SG_ CAN_TX_TRACK_ONCOMING : 0|1@0+ (1,0) [0|0] ""  ESR
 SG_ CAN_TX_TRACK_LAT_RATE : 7|6@0- (0.25,0) [-8|7.75] ""  ESR
 SG_ CAN_TX_TRACK_BRIDGE_OBJECT : 39|1@0+ (1,0) [0|0] ""  ESR
 SG_ CAN_TX_TRACK_WIDTH : 37|4@0+ (0.5,0) [0|7.5] "m"  ESR
 SG_ CAN_TX_TRACK_STATUS : 15|3@0+ (1,0) [0|7] ""  ESR
 SG_ CAN_TX_TRACK_ROLLING_COUNT : 38|1@0+ (1,0) [0|1] ""  ESR
 SG_ CAN_TX_TRACK_RANGE_RATE : 53|14@0- (0.01,0) [-81.92|81.91] "m/s"  ESR
 SG_ CAN_TX_TRACK_RANGE_ACCEL : 33|10@0- (0.05,0) [-25.6|25.55] "m/s/s"  ESR
 SG_ CAN_TX_TRACK_RANGE : 18|11@0+ (0.1,0) [0|204.7] "m"  ESR
 SG_ CAN_TX_TRACK_MED_RANGE_MODE : 55|2@0+ (1,0) [0|3] ""  ESR
 SG_ CAN_TX_TRACK_ANGLE : 12|10@0- (0.1,0) [-51.2|51.1] "deg"  ESR

BO_ 1313 ESR_Track34: 8 Vector__XXX
 SG_ CAN_TX_TRACK_GROUPING_CHANGED : 1|1@0+ (1,0) [0|0] ""  ESR
 SG_ CAN_TX_TRACK_ONCOMING : 0|1@0+ (1,0) [0|0] ""  ESR
 SG_ CAN_TX_TRACK_LAT_RATE : 7|6@0- (0.25,0) [-8|7.75] ""  ESR
 SG_ CAN_TX_TRACK_BRIDGE_OBJECT : 39|1@0+ (1,0) [0|0] ""  ESR
 SG_ CAN_TX_TRACK_WIDTH : 37|4@0+ (0.5,0) [0|7.5] "m"  ESR
 SG_ CAN_TX_TRACK_STATUS : 15|3@0+ (1,0) [0|7] ""  ESR
 SG_ CAN_TX_TRACK_ROLLING_COUNT : 38|1@0+ (1,0) [0|1] ""  ESR
 SG_ CAN_TX_TRACK_RANGE_RATE : 53|14@0- (0.01,0) [-81.92|81.91] "m/s"  ESR
 SG_ CAN_TX_TRACK_RANGE_ACCEL : 33|10@0- (0.05,0) [-25.6|25.55] "m/s/s"  ESR
 SG_ CAN_TX_TRACK_RANGE : 18|11@0+ (0.1,0) [0|204.7] "m"  ESR
 SG_ CAN_TX_TRACK_MED_RANGE_MODE : 55|2@0+ (1,0) [0|3] ""  ESR
 SG_ CAN_TX_TRACK_ANGLE : 12|10@0- (0.1,0) [-51.2|51.1] "deg"  ESR

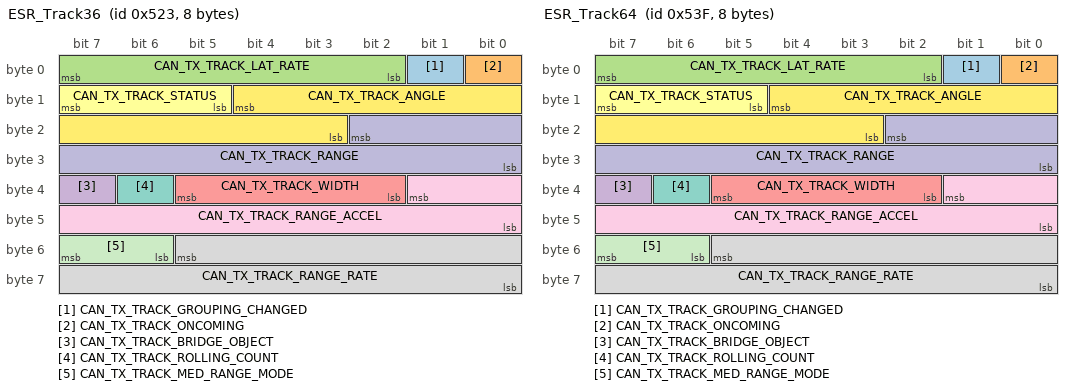
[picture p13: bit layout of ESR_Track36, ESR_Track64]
BO_ 1315 ESR_Track36: 8 Vector__XXX
 SG_ CAN_TX_TRACK_GROUPING_CHANGED : 1|1@0+ (1,0) [0|0] ""  ESR
 SG_ CAN_TX_TRACK_ONCOMING : 0|1@0+ (1,0) [0|0] ""  ESR
 SG_ CAN_TX_TRACK_LAT_RATE : 7|6@0- (0.25,0) [-8|7.75] ""  ESR
 SG_ CAN_TX_TRACK_BRIDGE_OBJECT : 39|1@0+ (1,0) [0|0] ""  ESR
 SG_ CAN_TX_TRACK_WIDTH : 37|4@0+ (0.5,0) [0|7.5] "m"  ESR
 SG_ CAN_TX_TRACK_STATUS : 15|3@0+ (1,0) [0|7] ""  ESR
 SG_ CAN_TX_TRACK_ROLLING_COUNT : 38|1@0+ (1,0) [0|1] ""  ESR
 SG_ CAN_TX_TRACK_RANGE_RATE : 53|14@0- (0.01,0) [-81.92|81.91] "m/s"  ESR
 SG_ CAN_TX_TRACK_RANGE_ACCEL : 33|10@0- (0.05,0) [-25.6|25.55] "m/s/s"  ESR
 SG_ CAN_TX_TRACK_RANGE : 18|11@0+ (0.1,0) [0|204.7] "m"  ESR
 SG_ CAN_TX_TRACK_MED_RANGE_MODE : 55|2@0+ (1,0) [0|3] ""  ESR
 SG_ CAN_TX_TRACK_ANGLE : 12|10@0- (0.1,0) [-51.2|51.1] "deg"  ESR

BO_ 1343 ESR_Track64: 8 Vector__XXX
 SG_ CAN_TX_TRACK_GROUPING_CHANGED : 1|1@0+ (1,0) [0|0] ""  ESR
 SG_ CAN_TX_TRACK_ONCOMING : 0|1@0+ (1,0) [0|0] ""  ESR
 SG_ CAN_TX_TRACK_LAT_RATE : 7|6@0- (0.25,0) [-8|7.75] ""  ESR
 SG_ CAN_TX_TRACK_BRIDGE_OBJECT : 39|1@0+ (1,0) [0|0] ""  ESR
 SG_ CAN_TX_TRACK_WIDTH : 37|4@0+ (0.5,0) [0|7.5] "m"  ESR
 SG_ CAN_TX_TRACK_STATUS : 15|3@0+ (1,0) [0|7] ""  ESR
 SG_ CAN_TX_TRACK_ROLLING_COUNT : 38|1@0+ (1,0) [0|1] ""  ESR
 SG_ CAN_TX_TRACK_RANGE_RATE : 53|14@0- (0.01,0) [-81.92|81.91] "m/s"  ESR
 SG_ CAN_TX_TRACK_RANGE_ACCEL : 33|10@0- (0.05,0) [-25.6|25.55] "m/s/s"  ESR
 SG_ CAN_TX_TRACK_RANGE : 18|11@0+ (0.1,0) [0|204.7] "m"  ESR
 SG_ CAN_TX_TRACK_MED_RANGE_MODE : 55|2@0+ (1,0) [0|3] ""  ESR
 SG_ CAN_TX_TRACK_ANGLE : 12|10@0- (0.1,0) [-51.2|51.1] "deg"  ESR

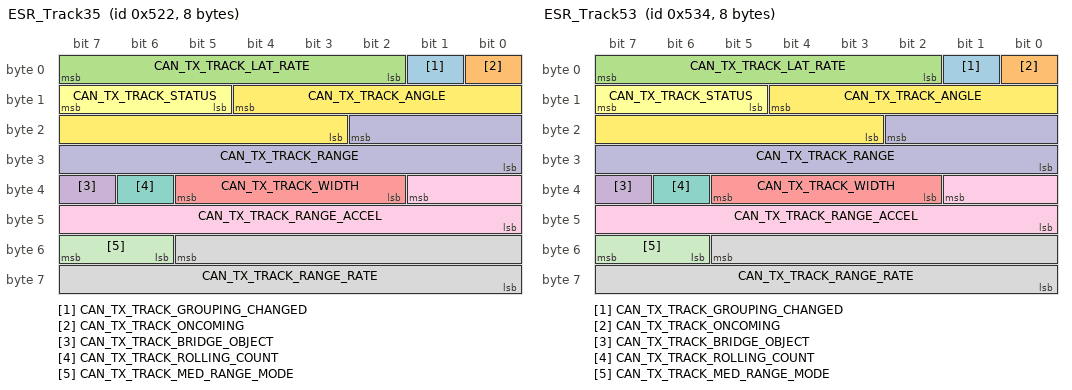
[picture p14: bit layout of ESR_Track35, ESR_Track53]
BO_ 1314 ESR_Track35: 8 Vector__XXX
 SG_ CAN_TX_TRACK_GROUPING_CHANGED : 1|1@0+ (1,0) [0|0] ""  ESR
 SG_ CAN_TX_TRACK_ONCOMING : 0|1@0+ (1,0) [0|0] ""  ESR
 SG_ CAN_TX_TRACK_LAT_RATE : 7|6@0- (0.25,0) [-8|7.75] ""  ESR
 SG_ CAN_TX_TRACK_BRIDGE_OBJECT : 39|1@0+ (1,0) [0|0] ""  ESR
 SG_ CAN_TX_TRACK_WIDTH : 37|4@0+ (0.5,0) [0|7.5] "m"  ESR
 SG_ CAN_TX_TRACK_STATUS : 15|3@0+ (1,0) [0|7] ""  ESR
 SG_ CAN_TX_TRACK_ROLLING_COUNT : 38|1@0+ (1,0) [0|1] ""  ESR
 SG_ CAN_TX_TRACK_RANGE_RATE : 53|14@0- (0.01,0) [-81.92|81.91] "m/s"  ESR
 SG_ CAN_TX_TRACK_RANGE_ACCEL : 33|10@0- (0.05,0) [-25.6|25.55] "m/s/s"  ESR
 SG_ CAN_TX_TRACK_RANGE : 18|11@0+ (0.1,0) [0|204.7] "m"  ESR
 SG_ CAN_TX_TRACK_MED_RANGE_MODE : 55|2@0+ (1,0) [0|3] ""  ESR
 SG_ CAN_TX_TRACK_ANGLE : 12|10@0- (0.1,0) [-51.2|51.1] "deg"  ESR

BO_ 1332 ESR_Track53: 8 Vector__XXX
 SG_ CAN_TX_TRACK_GROUPING_CHANGED : 1|1@0+ (1,0) [0|0] ""  ESR
 SG_ CAN_TX_TRACK_ONCOMING : 0|1@0+ (1,0) [0|0] ""  ESR
 SG_ CAN_TX_TRACK_LAT_RATE : 7|6@0- (0.25,0) [-8|7.75] ""  ESR
 SG_ CAN_TX_TRACK_BRIDGE_OBJECT : 39|1@0+ (1,0) [0|0] ""  ESR
 SG_ CAN_TX_TRACK_WIDTH : 37|4@0+ (0.5,0) [0|7.5] "m"  ESR
 SG_ CAN_TX_TRACK_STATUS : 15|3@0+ (1,0) [0|7] ""  ESR
 SG_ CAN_TX_TRACK_ROLLING_COUNT : 38|1@0+ (1,0) [0|1] ""  ESR
 SG_ CAN_TX_TRACK_RANGE_RATE : 53|14@0- (0.01,0) [-81.92|81.91] "m/s"  ESR
 SG_ CAN_TX_TRACK_RANGE_ACCEL : 33|10@0- (0.05,0) [-25.6|25.55] "m/s/s"  ESR
 SG_ CAN_TX_TRACK_RANGE : 18|11@0+ (0.1,0) [0|204.7] "m"  ESR
 SG_ CAN_TX_TRACK_MED_RANGE_MODE : 55|2@0+ (1,0) [0|3] ""  ESR
 SG_ CAN_TX_TRACK_ANGLE : 12|10@0- (0.1,0) [-51.2|51.1] "deg"  ESR

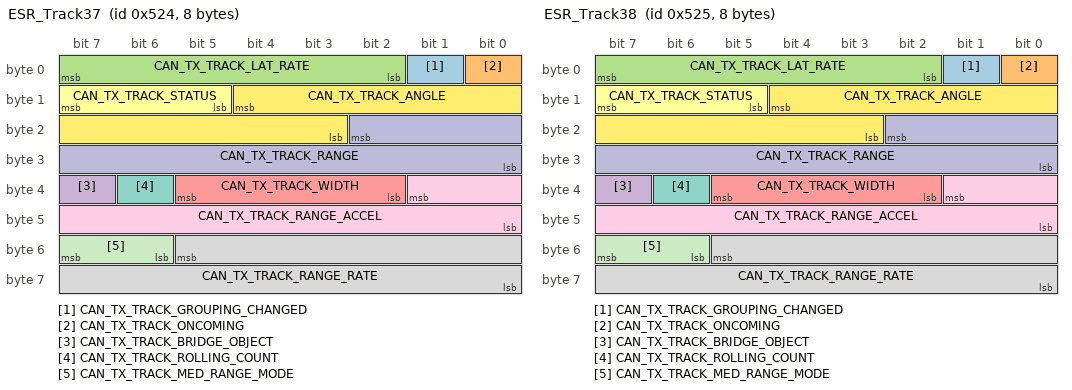
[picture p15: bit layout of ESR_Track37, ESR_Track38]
BO_ 1316 ESR_Track37: 8 Vector__XXX
 SG_ CAN_TX_TRACK_GROUPING_CHANGED : 1|1@0+ (1,0) [0|0] ""  ESR
 SG_ CAN_TX_TRACK_ONCOMING : 0|1@0+ (1,0) [0|0] ""  ESR
 SG_ CAN_TX_TRACK_LAT_RATE : 7|6@0- (0.25,0) [-8|7.75] ""  ESR
 SG_ CAN_TX_TRACK_BRIDGE_OBJECT : 39|1@0+ (1,0) [0|0] ""  ESR
 SG_ CAN_TX_TRACK_WIDTH : 37|4@0+ (0.5,0) [0|7.5] "m"  ESR
 SG_ CAN_TX_TRACK_STATUS : 15|3@0+ (1,0) [0|7] ""  ESR
 SG_ CAN_TX_TRACK_ROLLING_COUNT : 38|1@0+ (1,0) [0|1] ""  ESR
 SG_ CAN_TX_TRACK_RANGE_RATE : 53|14@0- (0.01,0) [-81.92|81.91] "m/s"  ESR
 SG_ CAN_TX_TRACK_RANGE_ACCEL : 33|10@0- (0.05,0) [-25.6|25.55] "m/s/s"  ESR
 SG_ CAN_TX_TRACK_RANGE : 18|11@0+ (0.1,0) [0|204.7] "m"  ESR
 SG_ CAN_TX_TRACK_MED_RANGE_MODE : 55|2@0+ (1,0) [0|3] ""  ESR
 SG_ CAN_TX_TRACK_ANGLE : 12|10@0- (0.1,0) [-51.2|51.1] "deg"  ESR

BO_ 1317 ESR_Track38: 8 Vector__XXX
 SG_ CAN_TX_TRACK_GROUPING_CHANGED : 1|1@0+ (1,0) [0|0] ""  ESR
 SG_ CAN_TX_TRACK_ONCOMING : 0|1@0+ (1,0) [0|0] ""  ESR
 SG_ CAN_TX_TRACK_LAT_RATE : 7|6@0- (0.25,0) [-8|7.75] ""  ESR
 SG_ CAN_TX_TRACK_BRIDGE_OBJECT : 39|1@0+ (1,0) [0|0] ""  ESR
 SG_ CAN_TX_TRACK_WIDTH : 37|4@0+ (0.5,0) [0|7.5] "m"  ESR
 SG_ CAN_TX_TRACK_STATUS : 15|3@0+ (1,0) [0|7] ""  ESR
 SG_ CAN_TX_TRACK_ROLLING_COUNT : 38|1@0+ (1,0) [0|1] ""  ESR
 SG_ CAN_TX_TRACK_RANGE_RATE : 53|14@0- (0.01,0) [-81.92|81.91] "m/s"  ESR
 SG_ CAN_TX_TRACK_RANGE_ACCEL : 33|10@0- (0.05,0) [-25.6|25.55] "m/s/s"  ESR
 SG_ CAN_TX_TRACK_RANGE : 18|11@0+ (0.1,0) [0|204.7] "m"  ESR
 SG_ CAN_TX_TRACK_MED_RANGE_MODE : 55|2@0+ (1,0) [0|3] ""  ESR
 SG_ CAN_TX_TRACK_ANGLE : 12|10@0- (0.1,0) [-51.2|51.1] "deg"  ESR

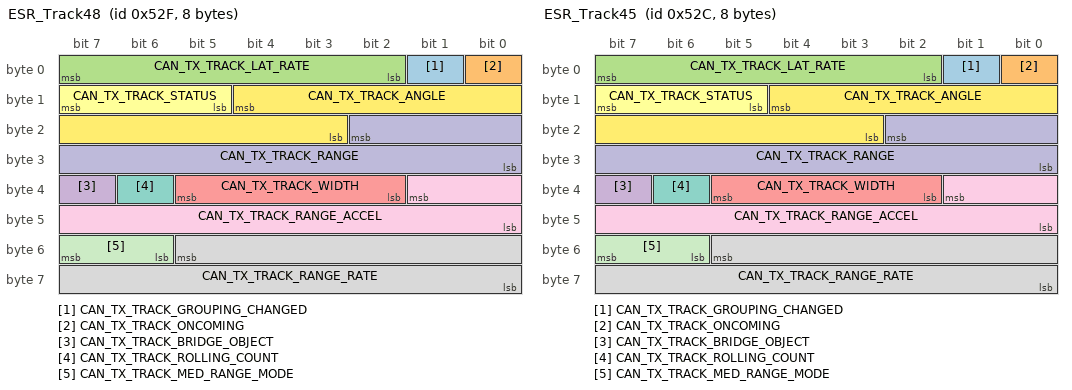
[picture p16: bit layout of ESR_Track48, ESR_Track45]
BO_ 1327 ESR_Track48: 8 Vector__XXX
 SG_ CAN_TX_TRACK_GROUPING_CHANGED : 1|1@0+ (1,0) [0|0] ""  ESR
 SG_ CAN_TX_TRACK_ONCOMING : 0|1@0+ (1,0) [0|0] ""  ESR
 SG_ CAN_TX_TRACK_LAT_RATE : 7|6@0- (0.25,0) [-8|7.75] ""  ESR
 SG_ CAN_TX_TRACK_BRIDGE_OBJECT : 39|1@0+ (1,0) [0|0] ""  ESR
 SG_ CAN_TX_TRACK_WIDTH : 37|4@0+ (0.5,0) [0|7.5] "m"  ESR
 SG_ CAN_TX_TRACK_STATUS : 15|3@0+ (1,0) [0|7] ""  ESR
 SG_ CAN_TX_TRACK_ROLLING_COUNT : 38|1@0+ (1,0) [0|1] ""  ESR
 SG_ CAN_TX_TRACK_RANGE_RATE : 53|14@0- (0.01,0) [-81.92|81.91] "m/s"  ESR
 SG_ CAN_TX_TRACK_RANGE_ACCEL : 33|10@0- (0.05,0) [-25.6|25.55] "m/s/s"  ESR
 SG_ CAN_TX_TRACK_RANGE : 18|11@0+ (0.1,0) [0|204.7] "m"  ESR
 SG_ CAN_TX_TRACK_MED_RANGE_MODE : 55|2@0+ (1,0) [0|3] ""  ESR
 SG_ CAN_TX_TRACK_ANGLE : 12|10@0- (0.1,0) [-51.2|51.1] "deg"  ESR

BO_ 1324 ESR_Track45: 8 Vector__XXX
 SG_ CAN_TX_TRACK_GROUPING_CHANGED : 1|1@0+ (1,0) [0|0] ""  ESR
 SG_ CAN_TX_TRACK_ONCOMING : 0|1@0+ (1,0) [0|0] ""  ESR
 SG_ CAN_TX_TRACK_LAT_RATE : 7|6@0- (0.25,0) [-8|7.75] ""  ESR
 SG_ CAN_TX_TRACK_BRIDGE_OBJECT : 39|1@0+ (1,0) [0|0] ""  ESR
 SG_ CAN_TX_TRACK_WIDTH : 37|4@0+ (0.5,0) [0|7.5] "m"  ESR
 SG_ CAN_TX_TRACK_STATUS : 15|3@0+ (1,0) [0|7] ""  ESR
 SG_ CAN_TX_TRACK_ROLLING_COUNT : 38|1@0+ (1,0) [0|1] ""  ESR
 SG_ CAN_TX_TRACK_RANGE_RATE : 53|14@0- (0.01,0) [-81.92|81.91] "m/s"  ESR
 SG_ CAN_TX_TRACK_RANGE_ACCEL : 33|10@0- (0.05,0) [-25.6|25.55] "m/s/s"  ESR
 SG_ CAN_TX_TRACK_RANGE : 18|11@0+ (0.1,0) [0|204.7] "m"  ESR
 SG_ CAN_TX_TRACK_MED_RANGE_MODE : 55|2@0+ (1,0) [0|3] ""  ESR
 SG_ CAN_TX_TRACK_ANGLE : 12|10@0- (0.1,0) [-51.2|51.1] "deg"  ESR

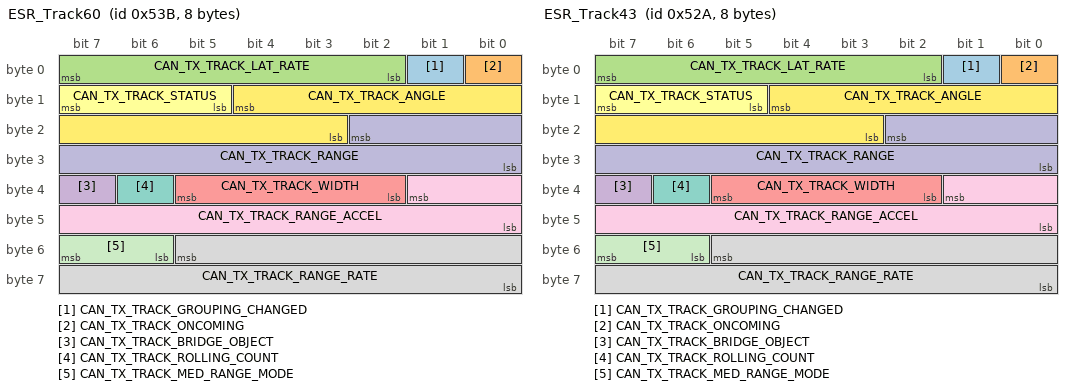
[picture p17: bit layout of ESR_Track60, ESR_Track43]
BO_ 1339 ESR_Track60: 8 Vector__XXX
 SG_ CAN_TX_TRACK_GROUPING_CHANGED : 1|1@0+ (1,0) [0|0] ""  ESR
 SG_ CAN_TX_TRACK_ONCOMING : 0|1@0+ (1,0) [0|0] ""  ESR
 SG_ CAN_TX_TRACK_LAT_RATE : 7|6@0- (0.25,0) [-8|7.75] ""  ESR
 SG_ CAN_TX_TRACK_BRIDGE_OBJECT : 39|1@0+ (1,0) [0|0] ""  ESR
 SG_ CAN_TX_TRACK_WIDTH : 37|4@0+ (0.5,0) [0|7.5] "m"  ESR
 SG_ CAN_TX_TRACK_STATUS : 15|3@0+ (1,0) [0|7] ""  ESR
 SG_ CAN_TX_TRACK_ROLLING_COUNT : 38|1@0+ (1,0) [0|1] ""  ESR
 SG_ CAN_TX_TRACK_RANGE_RATE : 53|14@0- (0.01,0) [-81.92|81.91] "m/s"  ESR
 SG_ CAN_TX_TRACK_RANGE_ACCEL : 33|10@0- (0.05,0) [-25.6|25.55] "m/s/s"  ESR
 SG_ CAN_TX_TRACK_RANGE : 18|11@0+ (0.1,0) [0|204.7] "m"  ESR
 SG_ CAN_TX_TRACK_MED_RANGE_MODE : 55|2@0+ (1,0) [0|3] ""  ESR
 SG_ CAN_TX_TRACK_ANGLE : 12|10@0- (0.1,0) [-51.2|51.1] "deg"  ESR

BO_ 1322 ESR_Track43: 8 Vector__XXX
 SG_ CAN_TX_TRACK_GROUPING_CHANGED : 1|1@0+ (1,0) [0|0] ""  ESR
 SG_ CAN_TX_TRACK_ONCOMING : 0|1@0+ (1,0) [0|0] ""  ESR
 SG_ CAN_TX_TRACK_LAT_RATE : 7|6@0- (0.25,0) [-8|7.75] ""  ESR
 SG_ CAN_TX_TRACK_BRIDGE_OBJECT : 39|1@0+ (1,0) [0|0] ""  ESR
 SG_ CAN_TX_TRACK_WIDTH : 37|4@0+ (0.5,0) [0|7.5] "m"  ESR
 SG_ CAN_TX_TRACK_STATUS : 15|3@0+ (1,0) [0|7] ""  ESR
 SG_ CAN_TX_TRACK_ROLLING_COUNT : 38|1@0+ (1,0) [0|1] ""  ESR
 SG_ CAN_TX_TRACK_RANGE_RATE : 53|14@0- (0.01,0) [-81.92|81.91] "m/s"  ESR
 SG_ CAN_TX_TRACK_RANGE_ACCEL : 33|10@0- (0.05,0) [-25.6|25.55] "m/s/s"  ESR
 SG_ CAN_TX_TRACK_RANGE : 18|11@0+ (0.1,0) [0|204.7] "m"  ESR
 SG_ CAN_TX_TRACK_MED_RANGE_MODE : 55|2@0+ (1,0) [0|3] ""  ESR
 SG_ CAN_TX_TRACK_ANGLE : 12|10@0- (0.1,0) [-51.2|51.1] "deg"  ESR

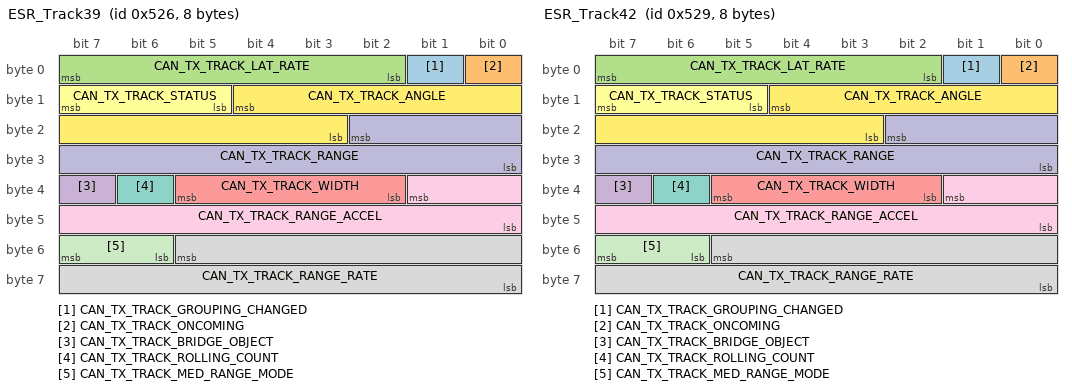
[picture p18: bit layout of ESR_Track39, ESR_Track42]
BO_ 1318 ESR_Track39: 8 Vector__XXX
 SG_ CAN_TX_TRACK_GROUPING_CHANGED : 1|1@0+ (1,0) [0|0] ""  ESR
 SG_ CAN_TX_TRACK_ONCOMING : 0|1@0+ (1,0) [0|0] ""  ESR
 SG_ CAN_TX_TRACK_LAT_RATE : 7|6@0- (0.25,0) [-8|7.75] ""  ESR
 SG_ CAN_TX_TRACK_BRIDGE_OBJECT : 39|1@0+ (1,0) [0|0] ""  ESR
 SG_ CAN_TX_TRACK_WIDTH : 37|4@0+ (0.5,0) [0|7.5] "m"  ESR
 SG_ CAN_TX_TRACK_STATUS : 15|3@0+ (1,0) [0|7] ""  ESR
 SG_ CAN_TX_TRACK_ROLLING_COUNT : 38|1@0+ (1,0) [0|1] ""  ESR
 SG_ CAN_TX_TRACK_RANGE_RATE : 53|14@0- (0.01,0) [-81.92|81.91] "m/s"  ESR
 SG_ CAN_TX_TRACK_RANGE_ACCEL : 33|10@0- (0.05,0) [-25.6|25.55] "m/s/s"  ESR
 SG_ CAN_TX_TRACK_RANGE : 18|11@0+ (0.1,0) [0|204.7] "m"  ESR
 SG_ CAN_TX_TRACK_MED_RANGE_MODE : 55|2@0+ (1,0) [0|3] ""  ESR
 SG_ CAN_TX_TRACK_ANGLE : 12|10@0- (0.1,0) [-51.2|51.1] "deg"  ESR

BO_ 1321 ESR_Track42: 8 Vector__XXX
 SG_ CAN_TX_TRACK_GROUPING_CHANGED : 1|1@0+ (1,0) [0|0] ""  ESR
 SG_ CAN_TX_TRACK_ONCOMING : 0|1@0+ (1,0) [0|0] ""  ESR
 SG_ CAN_TX_TRACK_LAT_RATE : 7|6@0- (0.25,0) [-8|7.75] ""  ESR
 SG_ CAN_TX_TRACK_BRIDGE_OBJECT : 39|1@0+ (1,0) [0|0] ""  ESR
 SG_ CAN_TX_TRACK_WIDTH : 37|4@0+ (0.5,0) [0|7.5] "m"  ESR
 SG_ CAN_TX_TRACK_STATUS : 15|3@0+ (1,0) [0|7] ""  ESR
 SG_ CAN_TX_TRACK_ROLLING_COUNT : 38|1@0+ (1,0) [0|1] ""  ESR
 SG_ CAN_TX_TRACK_RANGE_RATE : 53|14@0- (0.01,0) [-81.92|81.91] "m/s"  ESR
 SG_ CAN_TX_TRACK_RANGE_ACCEL : 33|10@0- (0.05,0) [-25.6|25.55] "m/s/s"  ESR
 SG_ CAN_TX_TRACK_RANGE : 18|11@0+ (0.1,0) [0|204.7] "m"  ESR
 SG_ CAN_TX_TRACK_MED_RANGE_MODE : 55|2@0+ (1,0) [0|3] ""  ESR
 SG_ CAN_TX_TRACK_ANGLE : 12|10@0- (0.1,0) [-51.2|51.1] "deg"  ESR

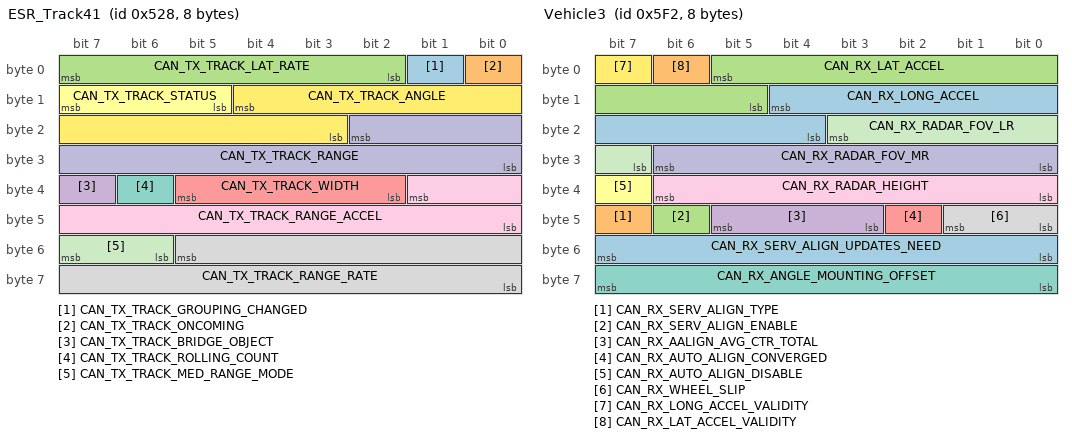
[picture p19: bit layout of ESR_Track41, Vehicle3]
BO_ 1320 ESR_Track41: 8 Vector__XXX
 SG_ CAN_TX_TRACK_GROUPING_CHANGED : 1|1@0+ (1,0) [0|0] ""  ESR
 SG_ CAN_TX_TRACK_ONCOMING : 0|1@0+ (1,0) [0|0] ""  ESR
 SG_ CAN_TX_TRACK_LAT_RATE : 7|6@0- (0.25,0) [-8|7.75] ""  ESR
 SG_ CAN_TX_TRACK_BRIDGE_OBJECT : 39|1@0+ (1,0) [0|0] ""  ESR
 SG_ CAN_TX_TRACK_WIDTH : 37|4@0+ (0.5,0) [0|7.5] "m"  ESR
 SG_ CAN_TX_TRACK_STATUS : 15|3@0+ (1,0) [0|7] ""  ESR
 SG_ CAN_TX_TRACK_ROLLING_COUNT : 38|1@0+ (1,0) [0|1] ""  ESR
 SG_ CAN_TX_TRACK_RANGE_RATE : 53|14@0- (0.01,0) [-81.92|81.91] "m/s"  ESR
 SG_ CAN_TX_TRACK_RANGE_ACCEL : 33|10@0- (0.05,0) [-25.6|25.55] "m/s/s"  ESR
 SG_ CAN_TX_TRACK_RANGE : 18|11@0+ (0.1,0) [0|204.7] "m"  ESR
 SG_ CAN_TX_TRACK_MED_RANGE_MODE : 55|2@0+ (1,0) [0|3] ""  ESR
 SG_ CAN_TX_TRACK_ANGLE : 12|10@0- (0.1,0) [-51.2|51.1] "deg"  ESR

BO_ 1319 ESR_Track40: 8 Vector__XXX
 SG_ CAN_TX_TRACK_GROUPING_CHANGED : 1|1@0+ (1,0) [0|0] ""  ESR
 SG_ CAN_TX_TRACK_ONCOMING : 0|1@0+ (1,0) [0|0] ""  ESR
 SG_ CAN_TX_TRACK_LAT_RATE : 7|6@0- (0.25,0) [-8|7.75] ""  ESR
 SG_ CAN_TX_TRACK_BRIDGE_OBJECT : 39|1@0+ (1,0) [0|0] ""  ESR
 SG_ CAN_TX_TRACK_WIDTH : 37|4@0+ (0.5,0) [0|7.5] "m"  ESR
 SG_ CAN_TX_TRACK_STATUS : 15|3@0+ (1,0) [0|7] ""  ESR
 SG_ CAN_TX_TRACK_ROLLING_COUNT : 38|1@0+ (1,0) [0|1] ""  ESR
 SG_ CAN_TX_TRACK_RANGE_RATE : 53|14@0- (0.01,0) [-81.92|81.91] "m/s"  ESR
 SG_ CAN_TX_TRACK_RANGE_ACCEL : 33|10@0- (0.05,0) [-25.6|25.55] "m/s/s"  ESR
 SG_ CAN_TX_TRACK_RANGE : 18|11@0+ (0.1,0) [0|204.7] "m"  ESR
 SG_ CAN_TX_TRACK_MED_RANGE_MODE : 55|2@0+ (1,0) [0|3] ""  ESR
 SG_ CAN_TX_TRACK_ANGLE : 12|10@0- (0.1,0) [-51.2|51.1] "deg"  ESR

BO_ 1323 ESR_Track44: 8 Vector__XXX
 SG_ CAN_TX_TRACK_GROUPING_CHANGED : 1|1@0+ (1,0) [0|0] ""  ESR
 SG_ CAN_TX_TRACK_ONCOMING : 0|1@0+ (1,0) [0|0] ""  ESR
 SG_ CAN_TX_TRACK_LAT_RATE : 7|6@0- (0.25,0) [-8|7.75] ""  ESR
 SG_ CAN_TX_TRACK_BRIDGE_OBJECT : 39|1@0+ (1,0) [0|0] ""  ESR
 SG_ CAN_TX_TRACK_WIDTH : 37|4@0+ (0.5,0) [0|7.5] "m"  ESR
 SG_ CAN_TX_TRACK_STATUS : 15|3@0+ (1,0) [0|7] ""  ESR
 SG_ CAN_TX_TRACK_ROLLING_COUNT : 38|1@0+ (1,0) [0|1] ""  ESR
 SG_ CAN_TX_TRACK_RANGE_RATE : 53|14@0- (0.01,0) [-81.92|81.91] "m/s"  ESR
 SG_ CAN_TX_TRACK_RANGE_ACCEL : 33|10@0- (0.05,0) [-25.6|25.55] "m/s/s"  ESR
 SG_ CAN_TX_TRACK_RANGE : 18|11@0+ (0.1,0) [0|204.7] "m"  ESR
 SG_ CAN_TX_TRACK_MED_RANGE_MODE : 55|2@0+ (1,0) [0|3] ""  ESR
 SG_ CAN_TX_TRACK_ANGLE : 12|10@0- (0.1,0) [-51.2|51.1] "deg"  ESR

BO_ 1329 ESR_Track50: 8 Vector__XXX
 SG_ CAN_TX_TRACK_GROUPING_CHANGED : 1|1@0+ (1,0) [0|0] ""  ESR
 SG_ CAN_TX_TRACK_ONCOMING : 0|1@0+ (1,0) [0|0] ""  ESR
 SG_ CAN_TX_TRACK_LAT_RATE : 7|6@0- (0.25,0) [-8|7.75] ""  ESR
 SG_ CAN_TX_TRACK_BRIDGE_OBJECT : 39|1@0+ (1,0) [0|0] ""  ESR
 SG_ CAN_TX_TRACK_WIDTH : 37|4@0+ (0.5,0) [0|7.5] "m"  ESR
 SG_ CAN_TX_TRACK_STATUS : 15|3@0+ (1,0) [0|7] ""  ESR
 SG_ CAN_TX_TRACK_ROLLING_COUNT : 38|1@0+ (1,0) [0|1] ""  ESR
 SG_ CAN_TX_TRACK_RANGE_RATE : 53|14@0- (0.01,0) [-81.92|81.91] "m/s"  ESR
 SG_ CAN_TX_TRACK_RANGE_ACCEL : 33|10@0- (0.05,0) [-25.6|25.55] "m/s/s"  ESR
 SG_ CAN_TX_TRACK_RANGE : 18|11@0+ (0.1,0) [0|204.7] "m"  ESR
 SG_ CAN_TX_TRACK_MED_RANGE_MODE : 55|2@0+ (1,0) [0|3] ""  ESR
 SG_ CAN_TX_TRACK_ANGLE : 12|10@0- (0.1,0) [-51.2|51.1] "deg"  ESR

BO_ 1326 ESR_Track47: 8 Vector__XXX
 SG_ CAN_TX_TRACK_GROUPING_CHANGED : 1|1@0+ (1,0) [0|0] ""  ESR
 SG_ CAN_TX_TRACK_ONCOMING : 0|1@0+ (1,0) [0|0] ""  ESR
 SG_ CAN_TX_TRACK_LAT_RATE : 7|6@0- (0.25,0) [-8|7.75] ""  ESR
 SG_ CAN_TX_TRACK_BRIDGE_OBJECT : 39|1@0+ (1,0) [0|0] ""  ESR
 SG_ CAN_TX_TRACK_WIDTH : 37|4@0+ (0.5,0) [0|7.5] "m"  ESR
 SG_ CAN_TX_TRACK_STATUS : 15|3@0+ (1,0) [0|7] ""  ESR
 SG_ CAN_TX_TRACK_ROLLING_COUNT : 38|1@0+ (1,0) [0|1] ""  ESR
 SG_ CAN_TX_TRACK_RANGE_RATE : 53|14@0- (0.01,0) [-81.92|81.91] "m/s"  ESR
 SG_ CAN_TX_TRACK_RANGE_ACCEL : 33|10@0- (0.05,0) [-25.6|25.55] "m/s/s"  ESR
 SG_ CAN_TX_TRACK_RANGE : 18|11@0+ (0.1,0) [0|204.7] "m"  ESR
 SG_ CAN_TX_TRACK_MED_RANGE_MODE : 55|2@0+ (1,0) [0|3] ""  ESR
 SG_ CAN_TX_TRACK_ANGLE : 12|10@0- (0.1,0) [-51.2|51.1] "deg"  ESR

BO_ 1342 ESR_Track63: 8 Vector__XXX
 SG_ CAN_TX_TRACK_GROUPING_CHANGED : 1|1@0+ (1,0) [0|0] ""  ESR
 SG_ CAN_TX_TRACK_ONCOMING : 0|1@0+ (1,0) [0|0] ""  ESR
 SG_ CAN_TX_TRACK_LAT_RATE : 7|6@0- (0.25,0) [-8|7.75] ""  ESR
 SG_ CAN_TX_TRACK_BRIDGE_OBJECT : 39|1@0+ (1,0) [0|0] ""  ESR
 SG_ CAN_TX_TRACK_WIDTH : 37|4@0+ (0.5,0) [0|7.5] "m"  ESR
 SG_ CAN_TX_TRACK_STATUS : 15|3@0+ (1,0) [0|7] ""  ESR
 SG_ CAN_TX_TRACK_ROLLING_COUNT : 38|1@0+ (1,0) [0|1] ""  ESR
 SG_ CAN_TX_TRACK_RANGE_RATE : 53|14@0- (0.01,0) [-81.92|81.91] "m/s"  ESR
 SG_ CAN_TX_TRACK_RANGE_ACCEL : 33|10@0- (0.05,0) [-25.6|25.55] "m/s/s"  ESR
 SG_ CAN_TX_TRACK_RANGE : 18|11@0+ (0.1,0) [0|204.7] "m"  ESR
 SG_ CAN_TX_TRACK_MED_RANGE_MODE : 55|2@0+ (1,0) [0|3] ""  ESR
 SG_ CAN_TX_TRACK_ANGLE : 12|10@0- (0.1,0) [-51.2|51.1] "deg"  ESR

BO_ 1340 ESR_Track61: 8 Vector__XXX
 SG_ CAN_TX_TRACK_GROUPING_CHANGED : 1|1@0+ (1,0) [0|0] ""  ESR
 SG_ CAN_TX_TRACK_ONCOMING : 0|1@0+ (1,0) [0|0] ""  ESR
 SG_ CAN_TX_TRACK_LAT_RATE : 7|6@0- (0.25,0) [-8|7.75] ""  ESR
 SG_ CAN_TX_TRACK_BRIDGE_OBJECT : 39|1@0+ (1,0) [0|0] ""  ESR
 SG_ CAN_TX_TRACK_WIDTH : 37|4@0+ (0.5,0) [0|7.5] "m"  ESR
 SG_ CAN_TX_TRACK_STATUS : 15|3@0+ (1,0) [0|7] ""  ESR
 SG_ CAN_TX_TRACK_ROLLING_COUNT : 38|1@0+ (1,0) [0|1] ""  ESR
 SG_ CAN_TX_TRACK_RANGE_RATE : 53|14@0- (0.01,0) [-81.92|81.91] "m/s"  ESR
 SG_ CAN_TX_TRACK_RANGE_ACCEL : 33|10@0- (0.05,0) [-25.6|25.55] "m/s/s"  ESR
 SG_ CAN_TX_TRACK_RANGE : 18|11@0+ (0.1,0) [0|204.7] "m"  ESR
 SG_ CAN_TX_TRACK_MED_RANGE_MODE : 55|2@0+ (1,0) [0|3] ""  ESR
 SG_ CAN_TX_TRACK_ANGLE : 12|10@0- (0.1,0) [-51.2|51.1] "deg"  ESR

BO_ 1333 ESR_Track54: 8 Vector__XXX
 SG_ CAN_TX_TRACK_GROUPING_CHANGED : 1|1@0+ (1,0) [0|0] ""  ESR
 SG_ CAN_TX_TRACK_ONCOMING : 0|1@0+ (1,0) [0|0] ""  ESR
 SG_ CAN_TX_TRACK_LAT_RATE : 7|6@0- (0.25,0) [-8|7.75] ""  ESR
 SG_ CAN_TX_TRACK_BRIDGE_OBJECT : 39|1@0+ (1,0) [0|0] ""  ESR
 SG_ CAN_TX_TRACK_WIDTH : 37|4@0+ (0.5,0) [0|7.5] "m"  ESR
 SG_ CAN_TX_TRACK_STATUS : 15|3@0+ (1,0) [0|7] ""  ESR
 SG_ CAN_TX_TRACK_ROLLING_COUNT : 38|1@0+ (1,0) [0|1] ""  ESR
 SG_ CAN_TX_TRACK_RANGE_RATE : 53|14@0- (0.01,0) [-81.92|81.91] "m/s"  ESR
 SG_ CAN_TX_TRACK_RANGE_ACCEL : 33|10@0- (0.05,0) [-25.6|25.55] "m/s/s"  ESR
 SG_ CAN_TX_TRACK_RANGE : 18|11@0+ (0.1,0) [0|204.7] "m"  ESR
 SG_ CAN_TX_TRACK_MED_RANGE_MODE : 55|2@0+ (1,0) [0|3] ""  ESR
 SG_ CAN_TX_TRACK_ANGLE : 12|10@0- (0.1,0) [-51.2|51.1] "deg"  ESR

BO_ 1335 ESR_Track56: 8 Vector__XXX
 SG_ CAN_TX_TRACK_GROUPING_CHANGED : 1|1@0+ (1,0) [0|0] ""  ESR
 SG_ CAN_TX_TRACK_ONCOMING : 0|1@0+ (1,0) [0|0] ""  ESR
 SG_ CAN_TX_TRACK_LAT_RATE : 7|6@0- (0.25,0) [-8|7.75] ""  ESR
 SG_ CAN_TX_TRACK_BRIDGE_OBJECT : 39|1@0+ (1,0) [0|0] ""  ESR
 SG_ CAN_TX_TRACK_WIDTH : 37|4@0+ (0.5,0) [0|7.5] "m"  ESR
 SG_ CAN_TX_TRACK_STATUS : 15|3@0+ (1,0) [0|7] ""  ESR
 SG_ CAN_TX_TRACK_ROLLING_COUNT : 38|1@0+ (1,0) [0|1] ""  ESR
 SG_ CAN_TX_TRACK_RANGE_RATE : 53|14@0- (0.01,0) [-81.92|81.91] "m/s"  ESR
 SG_ CAN_TX_TRACK_RANGE_ACCEL : 33|10@0- (0.05,0) [-25.6|25.55] "m/s/s"  ESR
 SG_ CAN_TX_TRACK_RANGE : 18|11@0+ (0.1,0) [0|204.7] "m"  ESR
 SG_ CAN_TX_TRACK_MED_RANGE_MODE : 55|2@0+ (1,0) [0|3] ""  ESR
 SG_ CAN_TX_TRACK_ANGLE : 12|10@0- (0.1,0) [-51.2|51.1] "deg"  ESR

BO_ 1337 ESR_Track58: 8 Vector__XXX
 SG_ CAN_TX_TRACK_GROUPING_CHANGED : 1|1@0+ (1,0) [0|0] ""  ESR
 SG_ CAN_TX_TRACK_ONCOMING : 0|1@0+ (1,0) [0|0] ""  ESR
 SG_ CAN_TX_TRACK_LAT_RATE : 7|6@0- (0.25,0) [-8|7.75] ""  ESR
 SG_ CAN_TX_TRACK_BRIDGE_OBJECT : 39|1@0+ (1,0) [0|0] ""  ESR
 SG_ CAN_TX_TRACK_WIDTH : 37|4@0+ (0.5,0) [0|7.5] "m"  ESR
 SG_ CAN_TX_TRACK_STATUS : 15|3@0+ (1,0) [0|7] ""  ESR
 SG_ CAN_TX_TRACK_ROLLING_COUNT : 38|1@0+ (1,0) [0|1] ""  ESR
 SG_ CAN_TX_TRACK_RANGE_RATE : 53|14@0- (0.01,0) [-81.92|81.91] "m/s"  ESR
 SG_ CAN_TX_TRACK_RANGE_ACCEL : 33|10@0- (0.05,0) [-25.6|25.55] "m/s/s"  ESR
 SG_ CAN_TX_TRACK_RANGE : 18|11@0+ (0.1,0) [0|204.7] "m"  ESR
 SG_ CAN_TX_TRACK_MED_RANGE_MODE : 55|2@0+ (1,0) [0|3] ""  ESR
 SG_ CAN_TX_TRACK_ANGLE : 12|10@0- (0.1,0) [-51.2|51.1] "deg"  ESR

BO_ 1331 ESR_Track52: 8 Vector__XXX
 SG_ CAN_TX_TRACK_GROUPING_CHANGED : 1|1@0+ (1,0) [0|0] ""  ESR
 SG_ CAN_TX_TRACK_ONCOMING : 0|1@0+ (1,0) [0|0] ""  ESR
 SG_ CAN_TX_TRACK_LAT_RATE : 7|6@0- (0.25,0) [-8|7.75] ""  ESR
 SG_ CAN_TX_TRACK_BRIDGE_OBJECT : 39|1@0+ (1,0) [0|0] ""  ESR
 SG_ CAN_TX_TRACK_WIDTH : 37|4@0+ (0.5,0) [0|7.5] "m"  ESR
 SG_ CAN_TX_TRACK_STATUS : 15|3@0+ (1,0) [0|7] ""  ESR
 SG_ CAN_TX_TRACK_ROLLING_COUNT : 38|1@0+ (1,0) [0|1] ""  ESR
 SG_ CAN_TX_TRACK_RANGE_RATE : 53|14@0- (0.01,0) [-81.92|81.91] "m/s"  ESR
 SG_ CAN_TX_TRACK_RANGE_ACCEL : 33|10@0- (0.05,0) [-25.6|25.55] "m/s/s"  ESR
 SG_ CAN_TX_TRACK_RANGE : 18|11@0+ (0.1,0) [0|204.7] "m"  ESR
 SG_ CAN_TX_TRACK_MED_RANGE_MODE : 55|2@0+ (1,0) [0|3] ""  ESR
 SG_ CAN_TX_TRACK_ANGLE : 12|10@0- (0.1,0) [-51.2|51.1] "deg"  ESR

BO_ 1338 ESR_Track59: 8 Vector__XXX
 SG_ CAN_TX_TRACK_GROUPING_CHANGED : 1|1@0+ (1,0) [0|0] ""  ESR
 SG_ CAN_TX_TRACK_ONCOMING : 0|1@0+ (1,0) [0|0] ""  ESR
 SG_ CAN_TX_TRACK_LAT_RATE : 7|6@0- (0.25,0) [-8|7.75] ""  ESR
 SG_ CAN_TX_TRACK_BRIDGE_OBJECT : 39|1@0+ (1,0) [0|0] ""  ESR
 SG_ CAN_TX_TRACK_WIDTH : 37|4@0+ (0.5,0) [0|7.5] "m"  ESR
 SG_ CAN_TX_TRACK_STATUS : 15|3@0+ (1,0) [0|7] ""  ESR
 SG_ CAN_TX_TRACK_ROLLING_COUNT : 38|1@0+ (1,0) [0|1] ""  ESR
 SG_ CAN_TX_TRACK_RANGE_RATE : 53|14@0- (0.01,0) [-81.92|81.91] "m/s"  ESR
 SG_ CAN_TX_TRACK_RANGE_ACCEL : 33|10@0- (0.05,0) [-25.6|25.55] "m/s/s"  ESR
 SG_ CAN_TX_TRACK_RANGE : 18|11@0+ (0.1,0) [0|204.7] "m"  ESR
 SG_ CAN_TX_TRACK_MED_RANGE_MODE : 55|2@0+ (1,0) [0|3] ""  ESR
 SG_ CAN_TX_TRACK_ANGLE : 12|10@0- (0.1,0) [-51.2|51.1] "deg"  ESR

BO_ 1336 ESR_Track57: 8 Vector__XXX
 SG_ CAN_TX_TRACK_GROUPING_CHANGED : 1|1@0+ (1,0) [0|0] ""  ESR
 SG_ CAN_TX_TRACK_ONCOMING : 0|1@0+ (1,0) [0|0] ""  ESR
 SG_ CAN_TX_TRACK_LAT_RATE : 7|6@0- (0.25,0) [-8|7.75] ""  ESR
 SG_ CAN_TX_TRACK_BRIDGE_OBJECT : 39|1@0+ (1,0) [0|0] ""  ESR
 SG_ CAN_TX_TRACK_WIDTH : 37|4@0+ (0.5,0) [0|7.5] "m"  ESR
 SG_ CAN_TX_TRACK_STATUS : 15|3@0+ (1,0) [0|7] ""  ESR
 SG_ CAN_TX_TRACK_ROLLING_COUNT : 38|1@0+ (1,0) [0|1] ""  ESR
 SG_ CAN_TX_TRACK_RANGE_RATE : 53|14@0- (0.01,0) [-81.92|81.91] "m/s"  ESR
 SG_ CAN_TX_TRACK_RANGE_ACCEL : 33|10@0- (0.05,0) [-25.6|25.55] "m/s/s"  ESR
 SG_ CAN_TX_TRACK_RANGE : 18|11@0+ (0.1,0) [0|204.7] "m"  ESR
 SG_ CAN_TX_TRACK_MED_RANGE_MODE : 55|2@0+ (1,0) [0|3] ""  ESR
 SG_ CAN_TX_TRACK_ANGLE : 12|10@0- (0.1,0) [-51.2|51.1] "deg"  ESR

BO_ 1334 ESR_Track55: 8 Vector__XXX
 SG_ CAN_TX_TRACK_GROUPING_CHANGED : 1|1@0+ (1,0) [0|0] ""  ESR
 SG_ CAN_TX_TRACK_ONCOMING : 0|1@0+ (1,0) [0|0] ""  ESR
 SG_ CAN_TX_TRACK_LAT_RATE : 7|6@0- (0.25,0) [-8|7.75] ""  ESR
 SG_ CAN_TX_TRACK_BRIDGE_OBJECT : 39|1@0+ (1,0) [0|0] ""  ESR
 SG_ CAN_TX_TRACK_WIDTH : 37|4@0+ (0.5,0) [0|7.5] "m"  ESR
 SG_ CAN_TX_TRACK_STATUS : 15|3@0+ (1,0) [0|7] ""  ESR
 SG_ CAN_TX_TRACK_ROLLING_COUNT : 38|1@0+ (1,0) [0|1] ""  ESR
 SG_ CAN_TX_TRACK_RANGE_RATE : 53|14@0- (0.01,0) [-81.92|81.91] "m/s"  ESR
 SG_ CAN_TX_TRACK_RANGE_ACCEL : 33|10@0- (0.05,0) [-25.6|25.55] "m/s/s"  ESR
 SG_ CAN_TX_TRACK_RANGE : 18|11@0+ (0.1,0) [0|204.7] "m"  ESR
 SG_ CAN_TX_TRACK_MED_RANGE_MODE : 55|2@0+ (1,0) [0|3] ""  ESR
 SG_ CAN_TX_TRACK_ANGLE : 12|10@0- (0.1,0) [-51.2|51.1] "deg"  ESR

BO_ 1330 ESR_Track51: 8 Vector__XXX
 SG_ CAN_TX_TRACK_GROUPING_CHANGED : 1|1@0+ (1,0) [0|0] ""  ESR
 SG_ CAN_TX_TRACK_ONCOMING : 0|1@0+ (1,0) [0|0] ""  ESR
 SG_ CAN_TX_TRACK_LAT_RATE : 7|6@0- (0.25,0) [-8|7.75] ""  ESR
 SG_ CAN_TX_TRACK_BRIDGE_OBJECT : 39|1@0+ (1,0) [0|0] ""  ESR
 SG_ CAN_TX_TRACK_WIDTH : 37|4@0+ (0.5,0) [0|7.5] "m"  ESR
 SG_ CAN_TX_TRACK_STATUS : 15|3@0+ (1,0) [0|7] ""  ESR
 SG_ CAN_TX_TRACK_ROLLING_COUNT : 38|1@0+ (1,0) [0|1] ""  ESR
 SG_ CAN_TX_TRACK_RANGE_RATE : 53|14@0- (0.01,0) [-81.92|81.91] "m/s"  ESR
 SG_ CAN_TX_TRACK_RANGE_ACCEL : 33|10@0- (0.05,0) [-25.6|25.55] "m/s/s"  ESR
 SG_ CAN_TX_TRACK_RANGE : 18|11@0+ (0.1,0) [0|204.7] "m"  ESR
 SG_ CAN_TX_TRACK_MED_RANGE_MODE : 55|2@0+ (1,0) [0|3] ""  ESR
 SG_ CAN_TX_TRACK_ANGLE : 12|10@0- (0.1,0) [-51.2|51.1] "deg"  ESR

BO_ 1328 ESR_Track49: 8 Vector__XXX
 SG_ CAN_TX_TRACK_GROUPING_CHANGED : 1|1@0+ (1,0) [0|0] ""  ESR
 SG_ CAN_TX_TRACK_ONCOMING : 0|1@0+ (1,0) [0|0] ""  ESR
 SG_ CAN_TX_TRACK_LAT_RATE : 7|6@0- (0.25,0) [-8|7.75] ""  ESR
 SG_ CAN_TX_TRACK_BRIDGE_OBJECT : 39|1@0+ (1,0) [0|0] ""  ESR
 SG_ CAN_TX_TRACK_WIDTH : 37|4@0+ (0.5,0) [0|7.5] "m"  ESR
 SG_ CAN_TX_TRACK_STATUS : 15|3@0+ (1,0) [0|7] ""  ESR
 SG_ CAN_TX_TRACK_ROLLING_COUNT : 38|1@0+ (1,0) [0|1] ""  ESR
 SG_ CAN_TX_TRACK_RANGE_RATE : 53|14@0- (0.01,0) [-81.92|81.91] "m/s"  ESR
 SG_ CAN_TX_TRACK_RANGE_ACCEL : 33|10@0- (0.05,0) [-25.6|25.55] "m/s/s"  ESR
 SG_ CAN_TX_TRACK_RANGE : 18|11@0+ (0.1,0) [0|204.7] "m"  ESR
 SG_ CAN_TX_TRACK_MED_RANGE_MODE : 55|2@0+ (1,0) [0|3] ""  ESR
 SG_ CAN_TX_TRACK_ANGLE : 12|10@0- (0.1,0) [-51.2|51.1] "deg"  ESR

BO_ 1282 ESR_Track03: 8 Vector__XXX
 SG_ CAN_TX_TRACK_GROUPING_CHANGED : 1|1@0+ (1,0) [0|0] ""  ESR
 SG_ CAN_TX_TRACK_ONCOMING : 0|1@0+ (1,0) [0|0] ""  ESR
 SG_ CAN_TX_TRACK_LAT_RATE : 7|6@0- (0.25,0) [-8|7.75] ""  ESR
 SG_ CAN_TX_TRACK_BRIDGE_OBJECT : 39|1@0+ (1,0) [0|0] ""  ESR
 SG_ CAN_TX_TRACK_WIDTH : 37|4@0+ (0.5,0) [0|7.5] "m"  ESR
 SG_ CAN_TX_TRACK_STATUS : 15|3@0+ (1,0) [0|7] ""  ESR
 SG_ CAN_TX_TRACK_ROLLING_COUNT : 38|1@0+ (1,0) [0|1] ""  ESR
 SG_ CAN_TX_TRACK_RANGE_RATE : 53|14@0- (0.01,0) [-81.92|81.91] "m/s"  ESR
 SG_ CAN_TX_TRACK_RANGE_ACCEL : 33|10@0- (0.05,0) [-25.6|25.55] "m/s/s"  ESR
 SG_ CAN_TX_TRACK_RANGE : 18|11@0+ (0.1,0) [0|204.7] "m"  ESR
 SG_ CAN_TX_TRACK_MED_RANGE_MODE : 55|2@0+ (1,0) [0|3] ""  ESR
 SG_ CAN_TX_TRACK_ANGLE : 12|10@0- (0.1,0) [-51.2|51.1] "deg"  ESR

BO_ 1283 ESR_Track04: 8 Vector__XXX
 SG_ CAN_TX_TRACK_GROUPING_CHANGED : 1|1@0+ (1,0) [0|0] ""  ESR
 SG_ CAN_TX_TRACK_ONCOMING : 0|1@0+ (1,0) [0|0] ""  ESR
 SG_ CAN_TX_TRACK_LAT_RATE : 7|6@0- (0.25,0) [-8|7.75] ""  ESR
 SG_ CAN_TX_TRACK_BRIDGE_OBJECT : 39|1@0+ (1,0) [0|0] ""  ESR
 SG_ CAN_TX_TRACK_WIDTH : 37|4@0+ (0.5,0) [0|7.5] "m"  ESR
 SG_ CAN_TX_TRACK_STATUS : 15|3@0+ (1,0) [0|7] ""  ESR
 SG_ CAN_TX_TRACK_ROLLING_COUNT : 38|1@0+ (1,0) [0|1] ""  ESR
 SG_ CAN_TX_TRACK_RANGE_RATE : 53|14@0- (0.01,0) [-81.92|81.91] "m/s"  ESR
 SG_ CAN_TX_TRACK_RANGE_ACCEL : 33|10@0- (0.05,0) [-25.6|25.55] "m/s/s"  ESR
 SG_ CAN_TX_TRACK_RANGE : 18|11@0+ (0.1,0) [0|204.7] "m"  ESR
 SG_ CAN_TX_TRACK_MED_RANGE_MODE : 55|2@0+ (1,0) [0|3] ""  ESR
 SG_ CAN_TX_TRACK_ANGLE : 12|10@0- (0.1,0) [-51.2|51.1] "deg"  ESR

BO_ 1284 ESR_Track05: 8 Vector__XXX
 SG_ CAN_TX_TRACK_GROUPING_CHANGED : 1|1@0+ (1,0) [0|0] ""  ESR
 SG_ CAN_TX_TRACK_ONCOMING : 0|1@0+ (1,0) [0|0] ""  ESR
 SG_ CAN_TX_TRACK_LAT_RATE : 7|6@0- (0.25,0) [-8|7.75] ""  ESR
 SG_ CAN_TX_TRACK_BRIDGE_OBJECT : 39|1@0+ (1,0) [0|0] ""  ESR
 SG_ CAN_TX_TRACK_WIDTH : 37|4@0+ (0.5,0) [0|7.5] "m"  ESR
 SG_ CAN_TX_TRACK_STATUS : 15|3@0+ (1,0) [0|7] ""  ESR
 SG_ CAN_TX_TRACK_ROLLING_COUNT : 38|1@0+ (1,0) [0|1] ""  ESR
 SG_ CAN_TX_TRACK_RANGE_RATE : 53|14@0- (0.01,0) [-81.92|81.91] "m/s"  ESR
 SG_ CAN_TX_TRACK_RANGE_ACCEL : 33|10@0- (0.05,0) [-25.6|25.55] "m/s/s"  ESR
 SG_ CAN_TX_TRACK_RANGE : 18|11@0+ (0.1,0) [0|204.7] "m"  ESR
 SG_ CAN_TX_TRACK_MED_RANGE_MODE : 55|2@0+ (1,0) [0|3] ""  ESR
 SG_ CAN_TX_TRACK_ANGLE : 12|10@0- (0.1,0) [-51.2|51.1] "deg"  ESR

BO_ 1311 ESR_Track32: 8 Vector__XXX
 SG_ CAN_TX_TRACK_GROUPING_CHANGED : 1|1@0+ (1,0) [0|0] ""  ESR
 SG_ CAN_TX_TRACK_ONCOMING : 0|1@0+ (1,0) [0|0] ""  ESR
 SG_ CAN_TX_TRACK_LAT_RATE : 7|6@0- (0.25,0) [-8|7.75] ""  ESR
 SG_ CAN_TX_TRACK_BRIDGE_OBJECT : 39|1@0+ (1,0) [0|0] ""  ESR
 SG_ CAN_TX_TRACK_WIDTH : 37|4@0+ (0.5,0) [0|7.5] "m"  ESR
 SG_ CAN_TX_TRACK_STATUS : 15|3@0+ (1,0) [0|7] ""  ESR
 SG_ CAN_TX_TRACK_ROLLING_COUNT : 38|1@0+ (1,0) [0|1] ""  ESR
 SG_ CAN_TX_TRACK_RANGE_RATE : 53|14@0- (0.01,0) [-81.92|81.91] "m/s"  ESR
 SG_ CAN_TX_TRACK_RANGE_ACCEL : 33|10@0- (0.05,0) [-25.6|25.55] "m/s/s"  ESR
 SG_ CAN_TX_TRACK_RANGE : 18|11@0+ (0.1,0) [0|204.7] "m"  ESR
 SG_ CAN_TX_TRACK_MED_RANGE_MODE : 55|2@0+ (1,0) [0|3] ""  ESR
 SG_ CAN_TX_TRACK_ANGLE : 12|10@0- (0.1,0) [-51.2|51.1] "deg"  ESR

BO_ 1290 ESR_Track11: 8 Vector__XXX
 SG_ CAN_TX_TRACK_GROUPING_CHANGED : 1|1@0+ (1,0) [0|0] ""  ESR
 SG_ CAN_TX_TRACK_ONCOMING : 0|1@0+ (1,0) [0|0] ""  ESR
 SG_ CAN_TX_TRACK_LAT_RATE : 7|6@0- (0.25,0) [-8|7.75] ""  ESR
 SG_ CAN_TX_TRACK_BRIDGE_OBJECT : 39|1@0+ (1,0) [0|0] ""  ESR
 SG_ CAN_TX_TRACK_WIDTH : 37|4@0+ (0.5,0) [0|7.5] "m"  ESR
 SG_ CAN_TX_TRACK_STATUS : 15|3@0+ (1,0) [0|7] ""  ESR
 SG_ CAN_TX_TRACK_ROLLING_COUNT : 38|1@0+ (1,0) [0|1] ""  ESR
 SG_ CAN_TX_TRACK_RANGE_RATE : 53|14@0- (0.01,0) [-81.92|81.91] "m/s"  ESR
 SG_ CAN_TX_TRACK_RANGE_ACCEL : 33|10@0- (0.05,0) [-25.6|25.55] "m/s/s"  ESR
 SG_ CAN_TX_TRACK_RANGE : 18|11@0+ (0.1,0) [0|204.7] "m"  ESR
 SG_ CAN_TX_TRACK_MED_RANGE_MODE : 55|2@0+ (1,0) [0|3] ""  ESR
 SG_ CAN_TX_TRACK_ANGLE : 12|10@0- (0.1,0) [-51.2|51.1] "deg"  ESR

BO_ 1293 ESR_Track14: 8 Vector__XXX
 SG_ CAN_TX_TRACK_GROUPING_CHANGED : 1|1@0+ (1,0) [0|0] ""  ESR
 SG_ CAN_TX_TRACK_ONCOMING : 0|1@0+ (1,0) [0|0] ""  ESR
 SG_ CAN_TX_TRACK_LAT_RATE : 7|6@0- (0.25,0) [-8|7.75] ""  ESR
 SG_ CAN_TX_TRACK_BRIDGE_OBJECT : 39|1@0+ (1,0) [0|0] ""  ESR
 SG_ CAN_TX_TRACK_WIDTH : 37|4@0+ (0.5,0) [0|7.5] "m"  ESR
 SG_ CAN_TX_TRACK_STATUS : 15|3@0+ (1,0) [0|7] ""  ESR
 SG_ CAN_TX_TRACK_ROLLING_COUNT : 38|1@0+ (1,0) [0|1] ""  ESR
 SG_ CAN_TX_TRACK_RANGE_RATE : 53|14@0- (0.01,0) [-81.92|81.91] "m/s"  ESR
 SG_ CAN_TX_TRACK_RANGE_ACCEL : 33|10@0- (0.05,0) [-25.6|25.55] "m/s/s"  ESR
 SG_ CAN_TX_TRACK_RANGE : 18|11@0+ (0.1,0) [0|204.7] "m"  ESR
 SG_ CAN_TX_TRACK_MED_RANGE_MODE : 55|2@0+ (1,0) [0|3] ""  ESR
 SG_ CAN_TX_TRACK_ANGLE : 12|10@0- (0.1,0) [-51.2|51.1] "deg"  ESR

BO_ 1325 ESR_Track46: 8 Vector__XXX
 SG_ CAN_TX_TRACK_GROUPING_CHANGED : 1|1@0+ (1,0) [0|0] ""  ESR
 SG_ CAN_TX_TRACK_ONCOMING : 0|1@0+ (1,0) [0|0] ""  ESR
 SG_ CAN_TX_TRACK_LAT_RATE : 7|6@0- (0.25,0) [-8|7.75] ""  ESR
 SG_ CAN_TX_TRACK_BRIDGE_OBJECT : 39|1@0+ (1,0) [0|0] ""  ESR
 SG_ CAN_TX_TRACK_WIDTH : 37|4@0+ (0.5,0) [0|7.5] "m"  ESR
 SG_ CAN_TX_TRACK_STATUS : 15|3@0+ (1,0) [0|7] ""  ESR
 SG_ CAN_TX_TRACK_ROLLING_COUNT : 38|1@0+ (1,0) [0|1] ""  ESR
 SG_ CAN_TX_TRACK_RANGE_RATE : 53|14@0- (0.01,0) [-81.92|81.91] "m/s"  ESR
 SG_ CAN_TX_TRACK_RANGE_ACCEL : 33|10@0- (0.05,0) [-25.6|25.55] "m/s/s"  ESR
 SG_ CAN_TX_TRACK_RANGE : 18|11@0+ (0.1,0) [0|204.7] "m"  ESR
 SG_ CAN_TX_TRACK_MED_RANGE_MODE : 55|2@0+ (1,0) [0|3] ""  ESR
 SG_ CAN_TX_TRACK_ANGLE : 12|10@0- (0.1,0) [-51.2|51.1] "deg"  ESR

BO_ 1341 ESR_Track62: 8 Vector__XXX
 SG_ CAN_TX_TRACK_GROUPING_CHANGED : 1|1@0+ (1,0) [0|0] ""  ESR
 SG_ CAN_TX_TRACK_ONCOMING : 0|1@0+ (1,0) [0|0] ""  ESR
 SG_ CAN_TX_TRACK_LAT_RATE : 7|6@0- (0.25,0) [-8|7.75] ""  ESR
 SG_ CAN_TX_TRACK_BRIDGE_OBJECT : 39|1@0+ (1,0) [0|0] ""  ESR
 SG_ CAN_TX_TRACK_WIDTH : 37|4@0+ (0.5,0) [0|7.5] "m"  ESR
 SG_ CAN_TX_TRACK_STATUS : 15|3@0+ (1,0) [0|7] ""  ESR
 SG_ CAN_TX_TRACK_ROLLING_COUNT : 38|1@0+ (1,0) [0|1] ""  ESR
 SG_ CAN_TX_TRACK_RANGE_RATE : 53|14@0- (0.01,0) [-81.92|81.91] "m/s"  ESR
 SG_ CAN_TX_TRACK_RANGE_ACCEL : 33|10@0- (0.05,0) [-25.6|25.55] "m/s/s"  ESR
 SG_ CAN_TX_TRACK_RANGE : 18|11@0+ (0.1,0) [0|204.7] "m"  ESR
 SG_ CAN_TX_TRACK_MED_RANGE_MODE : 55|2@0+ (1,0) [0|3] ""  ESR
 SG_ CAN_TX_TRACK_ANGLE : 12|10@0- (0.1,0) [-51.2|51.1] "deg"  ESR

BO_ 1281 ESR_Track02: 8 Vector__XXX
 SG_ CAN_TX_TRACK_GROUPING_CHANGED : 1|1@0+ (1,0) [0|0] ""  ESR
 SG_ CAN_TX_TRACK_ONCOMING : 0|1@0+ (1,0) [0|0] ""  ESR
 SG_ CAN_TX_TRACK_LAT_RATE : 7|6@0- (0.25,0) [-8|7.75] ""  ESR
 SG_ CAN_TX_TRACK_BRIDGE_OBJECT : 39|1@0+ (1,0) [0|0] ""  ESR
 SG_ CAN_TX_TRACK_WIDTH : 37|4@0+ (0.5,0) [0|7.5] "m"  ESR
 SG_ CAN_TX_TRACK_STATUS : 15|3@0+ (1,0) [0|7] ""  ESR
 SG_ CAN_TX_TRACK_ROLLING_COUNT : 38|1@0+ (1,0) [0|1] ""  ESR
 SG_ CAN_TX_TRACK_RANGE_RATE : 53|14@0- (0.01,0) [-81.92|81.91] "m/s"  ESR
 SG_ CAN_TX_TRACK_RANGE_ACCEL : 33|10@0- (0.05,0) [-25.6|25.55] "m/s/s"  ESR
 SG_ CAN_TX_TRACK_RANGE : 18|11@0+ (0.1,0) [0|204.7] "m"  ESR
 SG_ CAN_TX_TRACK_MED_RANGE_MODE : 55|2@0+ (1,0) [0|3] ""  ESR
 SG_ CAN_TX_TRACK_ANGLE : 12|10@0- (0.1,0) [-51.2|51.1] "deg"  ESR

BO_ 1524 Vehicle5: 8 ESR
 SG_ CAN_RX_YAW_RATE_BIAS_SHIFT : 15|1@0+ (1,0) [0|0] "" Vector__XXX
 SG_ CAN_RX_STEERING_GEAR_RATIO : 63|8@0+ (0.125,0) [0|31.875] "" Vector__XXX
 SG_ CAN_RX_WHEELBASE : 55|8@0+ (2,200) [200|710] "cm" Vector__XXX
 SG_ CAN_RX_DISTANCE_REAR_AXLE : 47|8@0+ (2,200) [200|710] "cm" Vector__XXX
 SG_ CAN_RX_CW_BLOCKAGE_THRESHOLD : 39|8@0+ (0.0078125,0) [0|1.9921875] "" Vector__XXX
 SG_ CAN_RX_FUNNEL_OFFSET_RIGHT : 31|8@0- (0.1,0) [-2|10] "m" Vector__XXX
 SG_ CAN_RX_FUNNEL_OFFSET_LEFT : 23|8@0- (0.1,0) [-2|10] "m" Vector__XXX
 SG_ CAN_RX_BEAMWIDTH_VERT : 14|7@0+ (0.0625,0) [0|6] "deg" Vector__XXX
 SG_ CAN_RX_OVERSTEER_UNDERSTEER : 7|8@0- (1,0) [-128|127] "%" Vector__XXX

BO_ 1522 Vehicle3: 8 ESR
 SG_ CAN_RX_SERV_ALIGN_UPDATES_NEED : 55|8@0+ (1,0) [0|0] "" Vector__XXX
 SG_ CAN_RX_SERV_ALIGN_TYPE : 47|1@0+ (1,0) [0|0] "" Vector__XXX
 SG_ CAN_RX_SERV_ALIGN_ENABLE : 46|1@0+ (1,0) [0|0] "" Vector__XXX
 SG_ CAN_RX_AALIGN_AVG_CTR_TOTAL : 45|3@0+ (250,250) [250|2000] "" Vector__XXX
 SG_ CAN_RX_AUTO_ALIGN_CONVERGED : 42|1@0+ (1,0) [0|0] "" Vector__XXX
 SG_ CAN_RX_AUTO_ALIGN_DISABLE : 39|1@0+ (1,0) [0|0] "" Vector__XXX
 SG_ CAN_RX_ANGLE_MOUNTING_OFFSET : 63|8@0- (0.0625,0) [-8|7.9375] "deg" Vector__XXX
 SG_ CAN_RX_WHEEL_SLIP : 41|2@0+ (1,0) [0|0] "" Vector__XXX
 SG_ CAN_RX_RADAR_HEIGHT : 38|7@0+ (1,0) [0|125] "cm" Vector__XXX
 SG_ CAN_RX_RADAR_FOV_MR : 30|7@0+ (1,0) [0|120] "deg" Vector__XXX
 SG_ CAN_RX_RADAR_FOV_LR : 19|5@0+ (1,0) [0|30] "deg" Vector__XXX
 SG_ CAN_RX_LONG_ACCEL_VALIDITY : 7|1@0+ (1,0) [0|0] "" Vector__XXX
 SG_ CAN_RX_LONG_ACCEL : 12|9@0- (0.03125,0) [-8|7.96875] "m/s/s" Vector__XXX
 SG_ CAN_RX_LAT_ACCEL_VALIDITY : 6|1@0+ (1,0) [0|0] "" Vector__XXX
 SG_ CAN_RX_LAT_ACCEL : 5|9@0- (0.03125,0) [-8|7.96875] "" Vector__XXX

BO_ 1280 ESR_Track01: 8 Vector__XXX
 SG_ CAN_TX_TRACK_RANGE_RATE : 53|14@0- (0.01,0) [-81.92|81.91] "m/s"  ESR
 SG_ CAN_TX_TRACK_GROUPING_CHANGED : 1|1@0+ (1,0) [0|0] ""  ESR
 SG_ CAN_TX_TRACK_ONCOMING : 0|1@0+ (1,0) [0|0] ""  ESR
 SG_ CAN_TX_TRACK_LAT_RATE : 7|6@0- (0.25,0) [-8|7.75] ""  ESR
 SG_ CAN_TX_TRACK_BRIDGE_OBJECT : 39|1@0+ (1,0) [0|0] ""  ESR
 SG_ CAN_TX_TRACK_WIDTH : 37|4@0+ (0.5,0) [0|7.5] "m"  ESR
 SG_ CAN_TX_TRACK_STATUS : 15|3@0+ (1,0) [0|7] ""  ESR
 SG_ CAN_TX_TRACK_ROLLING_COUNT : 38|1@0+ (1,0) [0|1] ""  ESR
 SG_ CAN_TX_TRACK_RANGE_ACCEL : 33|10@0- (0.05,0) [-25.6|25.55] "m/s/s"  ESR
 SG_ CAN_TX_TRACK_RANGE : 18|11@0+ (0.1,0) [0|204.7] "m"  ESR
 SG_ CAN_TX_TRACK_MED_RANGE_MODE : 55|2@0+ (1,0) [0|3] ""  ESR
 SG_ CAN_TX_TRACK_ANGLE : 12|10@0- (0.1,0) [-51.2|51.1] "deg"  ESR

BO_ 1265 Vehicle2: 8 ESR
 SG_ CAN_RX_VOLVO_SHORT_TRACK_ROC : 31|4@0- (500,0) [-4000|3500] "m" Vector__XXX
 SG_ CAN_RX_MR_ONLY_TRANSMIT : 25|1@0+ (1,0) [0|0] "" Vector__XXX
 SG_ CAN_RX_LR_ONLY_TRANSMIT : 24|1@0+ (1,0) [0|0] "" Vector__XXX
 SG_ CAN_RX_HIGH_YAW_ANGLE : 21|6@0- (1,0) [-32|31] "deg" Vector__XXX
 SG_ CAN_RX_CLEAR_FAULTS : 22|1@0+ (1,0) [0|0] "" Vector__XXX
 SG_ CAN_RX_USE_ANGLE_MISALIGNMENT : 23|1@0+ (1,0) [0|0] "" Vector__XXX
 SG_ CAN_RX_TURN_SIGNAL_STATUS : 63|2@0+ (1,0) [0|0] "" Vector__XXX
 SG_ CAN_RX_BLOCKAGE_DISABLE : 54|1@0+ (1,0) [0|0] "" Vector__XXX
 SG_ CAN_RX_VEHICLE_SPEED_VALIDITY : 61|1@0+ (1,0) [0|0] "" Vector__XXX
 SG_ CAN_RX_MMR_UPSIDE_DOWN : 60|1@0+ (1,0) [0|1] "" Vector__XXX
 SG_ CAN_RX_WIPER_STATUS : 57|1@0+ (1,0) [0|0] "" Vector__XXX
 SG_ CAN_RX_RAW_DATA_ENABLE : 56|1@0+ (1,0) [0|0] "" Vector__XXX
 SG_ CAN_RX_RADAR_CMD_RADIATE : 55|1@0+ (1,0) [0|0] "" Vector__XXX
 SG_ CAN_RX_GROUPING_MODE : 59|2@0+ (1,0) [0|3] "" Vector__XXX
 SG_ CAN_RX_MAXIMUM_TRACKS : 53|6@0+ (1,1) [1|64] "" Vector__XXX
 SG_ CAN_RX_LATERAL_MOUNTING_OFFSET : 47|8@0- (0.015625,0) [-2|1.984375] "m" Vector__XXX
 SG_ CAN_RX_ANGLE_MISALIGNMENT : 39|8@0- (0.0625,0) [-8|7.9375] "deg" Vector__XXX
 SG_ CAN_RX_SCAN_INDEX_ACK : 7|16@0+ (1,0) [0|65535] "" Vector__XXX

BO_ 1264 Vehicle1: 8 ESR
 SG_ CAN_RX_STEERING_ANGLE_VALIDITY : 47|1@0+ (1,0) [0|0] "" Vector__XXX
 SG_ CAN_RX_STEERING_ANGLE_RATE : 50|11@0+ (1,0) [0|2047] "deg/s" Vector__XXX
 SG_ CAN_RX_STEERING_ANGLE_SIGN : 46|1@0+ (1,0) [0|0] "" Vector__XXX
 SG_ CAN_RX_STEERING_ANGLE_RATE_SIGN : 30|1@0+ (1,0) [0|0] "" Vector__XXX
 SG_ CAN_RX_STEERING_ANGLE : 45|11@0+ (1,0) [0|2047] "deg" Vector__XXX
 SG_ CAN_RX_RADIUS_CURVATURE : 29|14@0- (1,0) [-8192|8191] "m" Vector__XXX
 SG_ CAN_RX_YAW_RATE_VALIDITY : 31|1@0+ (1,0) [0|0] "" Vector__XXX
 SG_ CAN_RX_YAW_RATE : 11|12@0- (0.0625,0) [-128|127.9375] "deg/s" Vector__XXX
 SG_ CAN_RX_VEHICLE_SPEED_DIRECTION : 12|1@0+ (1,0) [0|0] "" Vector__XXX
 SG_ CAN_RX_VEHICLE_SPEED : 7|11@0+ (0.0625,0) [0|127.9375] "m/s" Vector__XXX

CM_ SG_ 1522 CAN_RX_ANGLE_MOUNTING_OFFSET "(+) = clockwise";
CM_ SG_ 1265 CAN_RX_LATERAL_MOUNTING_OFFSET "(+) = to the right from driver's perspective";
CM_ SG_ 1265 CAN_RX_ANGLE_MISALIGNMENT "(+) = clockwise";
BA_DEF_  "BusType" STRING ;
BA_DEF_DEF_  "BusType" "";
BA_ "BusType" "CAN";
VAL_ 1285 CAN_TX_TRACK_GROUPING_CHANGED 1 "GroupingChanged" 0 "GroupingUnchanged" ;
VAL_ 1285 CAN_TX_TRACK_ONCOMING 1 "Oncoming" 0 "NotOncoming" ;
VAL_ 1285 CAN_TX_TRACK_BRIDGE_OBJECT 1 "Bridge" 0 "Not_Bridge" ;
VAL_ 1285 CAN_TX_TRACK_STATUS 7 "New_Coasted_Target" 6 "Invalid_Coasted_Target" 5 "Merged_Target" 4 "Coasted_Target" 3 "Updated_Target" 2 "New_Updated_Target" 1 "New_Target" 0 "No_Target" ;
VAL_ 1285 CAN_TX_TRACK_MED_RANGE_MODE 3 "Both_MR_LR_Update" 2 "LR_Update_Only" 1 "MR_Update_Only" 0 "No_MR_LR_Update" ;
VAL_ 1286 CAN_TX_TRACK_GROUPING_CHANGED 1 "GroupingChanged" 0 "GroupingUnchanged" ;
VAL_ 1286 CAN_TX_TRACK_ONCOMING 1 "Oncoming" 0 "NotOncoming" ;
VAL_ 1286 CAN_TX_TRACK_BRIDGE_OBJECT 1 "Bridge" 0 "Not_Bridge" ;
VAL_ 1286 CAN_TX_TRACK_STATUS 7 "New_Coasted_Target" 6 "Invalid_Coasted_Target" 5 "Merged_Target" 4 "Coasted_Target" 3 "Updated_Target" 2 "New_Updated_Target" 1 "New_Target" 0 "No_Target" ;
VAL_ 1286 CAN_TX_TRACK_MED_RANGE_MODE 3 "Both_MR_LR_Update" 2 "LR_Update_Only" 1 "MR_Update_Only" 0 "No_MR_LR_Update" ;
VAL_ 1312 CAN_TX_TRACK_GROUPING_CHANGED 1 "GroupingChanged" 0 "GroupingUnchanged" ;
VAL_ 1312 CAN_TX_TRACK_ONCOMING 1 "Oncoming" 0 "NotOncoming" ;
VAL_ 1312 CAN_TX_TRACK_BRIDGE_OBJECT 1 "Bridge" 0 "Not_Bridge" ;
VAL_ 1312 CAN_TX_TRACK_STATUS 7 "New_Coasted_Target" 6 "Invalid_Coasted_Target" 5 "Merged_Target" 4 "Coasted_Target" 3 "Updated_Target" 2 "New_Updated_Target" 1 "New_Target" 0 "No_Target" ;
VAL_ 1312 CAN_TX_TRACK_MED_RANGE_MODE 3 "Both_MR_LR_Update" 2 "LR_Update_Only" 1 "MR_Update_Only" 0 "No_MR_LR_Update" ;
VAL_ 1307 CAN_TX_TRACK_GROUPING_CHANGED 1 "GroupingChanged" 0 "GroupingUnchanged" ;
VAL_ 1307 CAN_TX_TRACK_ONCOMING 1 "Oncoming" 0 "NotOncoming" ;
VAL_ 1307 CAN_TX_TRACK_BRIDGE_OBJECT 1 "Bridge" 0 "Not_Bridge" ;
VAL_ 1307 CAN_TX_TRACK_STATUS 7 "New_Coasted_Target" 6 "Invalid_Coasted_Target" 5 "Merged_Target" 4 "Coasted_Target" 3 "Updated_Target" 2 "New_Updated_Target" 1 "New_Target" 0 "No_Target" ;
VAL_ 1307 CAN_TX_TRACK_MED_RANGE_MODE 3 "Both_MR_LR_Update" 2 "LR_Update_Only" 1 "MR_Update_Only" 0 "No_MR_LR_Update" ;
VAL_ 1308 CAN_TX_TRACK_GROUPING_CHANGED 1 "GroupingChanged" 0 "GroupingUnchanged" ;
VAL_ 1308 CAN_TX_TRACK_ONCOMING 1 "Oncoming" 0 "NotOncoming" ;
VAL_ 1308 CAN_TX_TRACK_BRIDGE_OBJECT 1 "Bridge" 0 "Not_Bridge" ;
VAL_ 1308 CAN_TX_TRACK_STATUS 7 "New_Coasted_Target" 6 "Invalid_Coasted_Target" 5 "Merged_Target" 4 "Coasted_Target" 3 "Updated_Target" 2 "New_Updated_Target" 1 "New_Target" 0 "No_Target" ;
VAL_ 1308 CAN_TX_TRACK_MED_RANGE_MODE 3 "Both_MR_LR_Update" 2 "LR_Update_Only" 1 "MR_Update_Only" 0 "No_MR_LR_Update" ;
VAL_ 1303 CAN_TX_TRACK_GROUPING_CHANGED 1 "GroupingChanged" 0 "GroupingUnchanged" ;
VAL_ 1303 CAN_TX_TRACK_ONCOMING 1 "Oncoming" 0 "NotOncoming" ;
VAL_ 1303 CAN_TX_TRACK_BRIDGE_OBJECT 1 "Bridge" 0 "Not_Bridge" ;
VAL_ 1303 CAN_TX_TRACK_STATUS 7 "New_Coasted_Target" 6 "Invalid_Coasted_Target" 5 "Merged_Target" 4 "Coasted_Target" 3 "Updated_Target" 2 "New_Updated_Target" 1 "New_Target" 0 "No_Target" ;
VAL_ 1303 CAN_TX_TRACK_MED_RANGE_MODE 3 "Both_MR_LR_Update" 2 "LR_Update_Only" 1 "MR_Update_Only" 0 "No_MR_LR_Update" ;
VAL_ 1298 CAN_TX_TRACK_GROUPING_CHANGED 1 "GroupingChanged" 0 "GroupingUnchanged" ;
VAL_ 1298 CAN_TX_TRACK_ONCOMING 1 "Oncoming" 0 "NotOncoming" ;
VAL_ 1298 CAN_TX_TRACK_BRIDGE_OBJECT 1 "Bridge" 0 "Not_Bridge" ;
VAL_ 1298 CAN_TX_TRACK_STATUS 7 "New_Coasted_Target" 6 "Invalid_Coasted_Target" 5 "Merged_Target" 4 "Coasted_Target" 3 "Updated_Target" 2 "New_Updated_Target" 1 "New_Target" 0 "No_Target" ;
VAL_ 1298 CAN_TX_TRACK_MED_RANGE_MODE 3 "Both_MR_LR_Update" 2 "LR_Update_Only" 1 "MR_Update_Only" 0 "No_MR_LR_Update" ;
VAL_ 1306 CAN_TX_TRACK_GROUPING_CHANGED 1 "GroupingChanged" 0 "GroupingUnchanged" ;
VAL_ 1306 CAN_TX_TRACK_ONCOMING 1 "Oncoming" 0 "NotOncoming" ;
VAL_ 1306 CAN_TX_TRACK_BRIDGE_OBJECT 1 "Bridge" 0 "Not_Bridge" ;
VAL_ 1306 CAN_TX_TRACK_STATUS 7 "New_Coasted_Target" 6 "Invalid_Coasted_Target" 5 "Merged_Target" 4 "Coasted_Target" 3 "Updated_Target" 2 "New_Updated_Target" 1 "New_Target" 0 "No_Target" ;
VAL_ 1306 CAN_TX_TRACK_MED_RANGE_MODE 3 "Both_MR_LR_Update" 2 "LR_Update_Only" 1 "MR_Update_Only" 0 "No_MR_LR_Update" ;
VAL_ 1309 CAN_TX_TRACK_GROUPING_CHANGED 1 "GroupingChanged" 0 "GroupingUnchanged" ;
VAL_ 1309 CAN_TX_TRACK_ONCOMING 1 "Oncoming" 0 "NotOncoming" ;
VAL_ 1309 CAN_TX_TRACK_BRIDGE_OBJECT 1 "Bridge" 0 "Not_Bridge" ;
VAL_ 1309 CAN_TX_TRACK_STATUS 7 "New_Coasted_Target" 6 "Invalid_Coasted_Target" 5 "Merged_Target" 4 "Coasted_Target" 3 "Updated_Target" 2 "New_Updated_Target" 1 "New_Target" 0 "No_Target" ;
VAL_ 1309 CAN_TX_TRACK_MED_RANGE_MODE 3 "Both_MR_LR_Update" 2 "LR_Update_Only" 1 "MR_Update_Only" 0 "No_MR_LR_Update" ;
VAL_ 1292 CAN_TX_TRACK_GROUPING_CHANGED 1 "GroupingChanged" 0 "GroupingUnchanged" ;
VAL_ 1292 CAN_TX_TRACK_ONCOMING 1 "Oncoming" 0 "NotOncoming" ;
VAL_ 1292 CAN_TX_TRACK_BRIDGE_OBJECT 1 "Bridge" 0 "Not_Bridge" ;
VAL_ 1292 CAN_TX_TRACK_STATUS 7 "New_Coasted_Target" 6 "Invalid_Coasted_Target" 5 "Merged_Target" 4 "Coasted_Target" 3 "Updated_Target" 2 "New_Updated_Target" 1 "New_Target" 0 "No_Target" ;
VAL_ 1292 CAN_TX_TRACK_MED_RANGE_MODE 3 "Both_MR_LR_Update" 2 "LR_Update_Only" 1 "MR_Update_Only" 0 "No_MR_LR_Update" ;
VAL_ 1297 CAN_TX_TRACK_GROUPING_CHANGED 1 "GroupingChanged" 0 "GroupingUnchanged" ;
VAL_ 1297 CAN_TX_TRACK_ONCOMING 1 "Oncoming" 0 "NotOncoming" ;
VAL_ 1297 CAN_TX_TRACK_BRIDGE_OBJECT 1 "Bridge" 0 "Not_Bridge" ;
VAL_ 1297 CAN_TX_TRACK_STATUS 7 "New_Coasted_Target" 6 "Invalid_Coasted_Target" 5 "Merged_Target" 4 "Coasted_Target" 3 "Updated_Target" 2 "New_Updated_Target" 1 "New_Target" 0 "No_Target" ;
VAL_ 1297 CAN_TX_TRACK_MED_RANGE_MODE 3 "Both_MR_LR_Update" 2 "LR_Update_Only" 1 "MR_Update_Only" 0 "No_MR_LR_Update" ;
VAL_ 1305 CAN_TX_TRACK_GROUPING_CHANGED 1 "GroupingChanged" 0 "GroupingUnchanged" ;
VAL_ 1305 CAN_TX_TRACK_ONCOMING 1 "Oncoming" 0 "NotOncoming" ;
VAL_ 1305 CAN_TX_TRACK_BRIDGE_OBJECT 1 "Bridge" 0 "Not_Bridge" ;
VAL_ 1305 CAN_TX_TRACK_STATUS 7 "New_Coasted_Target" 6 "Invalid_Coasted_Target" 5 "Merged_Target" 4 "Coasted_Target" 3 "Updated_Target" 2 "New_Updated_Target" 1 "New_Target" 0 "No_Target" ;
VAL_ 1305 CAN_TX_TRACK_MED_RANGE_MODE 3 "Both_MR_LR_Update" 2 "LR_Update_Only" 1 "MR_Update_Only" 0 "No_MR_LR_Update" ;
VAL_ 1310 CAN_TX_TRACK_GROUPING_CHANGED 1 "GroupingChanged" 0 "GroupingUnchanged" ;
VAL_ 1310 CAN_TX_TRACK_ONCOMING 1 "Oncoming" 0 "NotOncoming" ;
VAL_ 1310 CAN_TX_TRACK_BRIDGE_OBJECT 1 "Bridge" 0 "Not_Bridge" ;
VAL_ 1310 CAN_TX_TRACK_STATUS 7 "New_Coasted_Target" 6 "Invalid_Coasted_Target" 5 "Merged_Target" 4 "Coasted_Target" 3 "Updated_Target" 2 "New_Updated_Target" 1 "New_Target" 0 "No_Target" ;
VAL_ 1310 CAN_TX_TRACK_MED_RANGE_MODE 3 "Both_MR_LR_Update" 2 "LR_Update_Only" 1 "MR_Update_Only" 0 "No_MR_LR_Update" ;
VAL_ 1296 CAN_TX_TRACK_GROUPING_CHANGED 1 "GroupingChanged" 0 "GroupingUnchanged" ;
VAL_ 1296 CAN_TX_TRACK_ONCOMING 1 "Oncoming" 0 "NotOncoming" ;
VAL_ 1296 CAN_TX_TRACK_BRIDGE_OBJECT 1 "Bridge" 0 "Not_Bridge" ;
VAL_ 1296 CAN_TX_TRACK_STATUS 7 "New_Coasted_Target" 6 "Invalid_Coasted_Target" 5 "Merged_Target" 4 "Coasted_Target" 3 "Updated_Target" 2 "New_Updated_Target" 1 "New_Target" 0 "No_Target" ;
VAL_ 1296 CAN_TX_TRACK_MED_RANGE_MODE 3 "Both_MR_LR_Update" 2 "LR_Update_Only" 1 "MR_Update_Only" 0 "No_MR_LR_Update" ;
VAL_ 1299 CAN_TX_TRACK_GROUPING_CHANGED 1 "GroupingChanged" 0 "GroupingUnchanged" ;
VAL_ 1299 CAN_TX_TRACK_ONCOMING 1 "Oncoming" 0 "NotOncoming" ;
VAL_ 1299 CAN_TX_TRACK_BRIDGE_OBJECT 1 "Bridge" 0 "Not_Bridge" ;
VAL_ 1299 CAN_TX_TRACK_STATUS 7 "New_Coasted_Target" 6 "Invalid_Coasted_Target" 5 "Merged_Target" 4 "Coasted_Target" 3 "Updated_Target" 2 "New_Updated_Target" 1 "New_Target" 0 "No_Target" ;
VAL_ 1299 CAN_TX_TRACK_MED_RANGE_MODE 3 "Both_MR_LR_Update" 2 "LR_Update_Only" 1 "MR_Update_Only" 0 "No_MR_LR_Update" ;
VAL_ 1291 CAN_TX_TRACK_GROUPING_CHANGED 1 "GroupingChanged" 0 "GroupingUnchanged" ;
VAL_ 1291 CAN_TX_TRACK_ONCOMING 1 "Oncoming" 0 "NotOncoming" ;
VAL_ 1291 CAN_TX_TRACK_BRIDGE_OBJECT 1 "Bridge" 0 "Not_Bridge" ;
VAL_ 1291 CAN_TX_TRACK_STATUS 7 "New_Coasted_Target" 6 "Invalid_Coasted_Target" 5 "Merged_Target" 4 "Coasted_Target" 3 "Updated_Target" 2 "New_Updated_Target" 1 "New_Target" 0 "No_Target" ;
VAL_ 1291 CAN_TX_TRACK_MED_RANGE_MODE 3 "Both_MR_LR_Update" 2 "LR_Update_Only" 1 "MR_Update_Only" 0 "No_MR_LR_Update" ;
VAL_ 1288 CAN_TX_TRACK_GROUPING_CHANGED 1 "GroupingChanged" 0 "GroupingUnchanged" ;
VAL_ 1288 CAN_TX_TRACK_ONCOMING 1 "Oncoming" 0 "NotOncoming" ;
VAL_ 1288 CAN_TX_TRACK_BRIDGE_OBJECT 1 "Bridge" 0 "Not_Bridge" ;
VAL_ 1288 CAN_TX_TRACK_STATUS 7 "New_Coasted_Target" 6 "Invalid_Coasted_Target" 5 "Merged_Target" 4 "Coasted_Target" 3 "Updated_Target" 2 "New_Updated_Target" 1 "New_Target" 0 "No_Target" ;
VAL_ 1288 CAN_TX_TRACK_MED_RANGE_MODE 3 "Both_MR_LR_Update" 2 "LR_Update_Only" 1 "MR_Update_Only" 0 "No_MR_LR_Update" ;
VAL_ 1289 CAN_TX_TRACK_GROUPING_CHANGED 1 "GroupingChanged" 0 "GroupingUnchanged" ;
VAL_ 1289 CAN_TX_TRACK_ONCOMING 1 "Oncoming" 0 "NotOncoming" ;
VAL_ 1289 CAN_TX_TRACK_BRIDGE_OBJECT 1 "Bridge" 0 "Not_Bridge" ;
VAL_ 1289 CAN_TX_TRACK_STATUS 7 "New_Coasted_Target" 6 "Invalid_Coasted_Target" 5 "Merged_Target" 4 "Coasted_Target" 3 "Updated_Target" 2 "New_Updated_Target" 1 "New_Target" 0 "No_Target" ;
VAL_ 1289 CAN_TX_TRACK_MED_RANGE_MODE 3 "Both_MR_LR_Update" 2 "LR_Update_Only" 1 "MR_Update_Only" 0 "No_MR_LR_Update" ;
VAL_ 1301 CAN_TX_TRACK_GROUPING_CHANGED 1 "GroupingChanged" 0 "GroupingUnchanged" ;
VAL_ 1301 CAN_TX_TRACK_ONCOMING 1 "Oncoming" 0 "NotOncoming" ;
VAL_ 1301 CAN_TX_TRACK_BRIDGE_OBJECT 1 "Bridge" 0 "Not_Bridge" ;
VAL_ 1301 CAN_TX_TRACK_STATUS 7 "New_Coasted_Target" 6 "Invalid_Coasted_Target" 5 "Merged_Target" 4 "Coasted_Target" 3 "Updated_Target" 2 "New_Updated_Target" 1 "New_Target" 0 "No_Target" ;
VAL_ 1301 CAN_TX_TRACK_MED_RANGE_MODE 3 "Both_MR_LR_Update" 2 "LR_Update_Only" 1 "MR_Update_Only" 0 "No_MR_LR_Update" ;
VAL_ 1295 CAN_TX_TRACK_GROUPING_CHANGED 1 "GroupingChanged" 0 "GroupingUnchanged" ;
VAL_ 1295 CAN_TX_TRACK_ONCOMING 1 "Oncoming" 0 "NotOncoming" ;
VAL_ 1295 CAN_TX_TRACK_BRIDGE_OBJECT 1 "Bridge" 0 "Not_Bridge" ;
VAL_ 1295 CAN_TX_TRACK_STATUS 7 "New_Coasted_Target" 6 "Invalid_Coasted_Target" 5 "Merged_Target" 4 "Coasted_Target" 3 "Updated_Target" 2 "New_Updated_Target" 1 "New_Target" 0 "No_Target" ;
VAL_ 1295 CAN_TX_TRACK_MED_RANGE_MODE 3 "Both_MR_LR_Update" 2 "LR_Update_Only" 1 "MR_Update_Only" 0 "No_MR_LR_Update" ;
VAL_ 1300 CAN_TX_TRACK_GROUPING_CHANGED 1 "GroupingChanged" 0 "GroupingUnchanged" ;
VAL_ 1300 CAN_TX_TRACK_ONCOMING 1 "Oncoming" 0 "NotOncoming" ;
VAL_ 1300 CAN_TX_TRACK_BRIDGE_OBJECT 1 "Bridge" 0 "Not_Bridge" ;
VAL_ 1300 CAN_TX_TRACK_STATUS 7 "New_Coasted_Target" 6 "Invalid_Coasted_Target" 5 "Merged_Target" 4 "Coasted_Target" 3 "Updated_Target" 2 "New_Updated_Target" 1 "New_Target" 0 "No_Target" ;
VAL_ 1300 CAN_TX_TRACK_MED_RANGE_MODE 3 "Both_MR_LR_Update" 2 "LR_Update_Only" 1 "MR_Update_Only" 0 "No_MR_LR_Update" ;
VAL_ 1294 CAN_TX_TRACK_GROUPING_CHANGED 1 "GroupingChanged" 0 "GroupingUnchanged" ;
VAL_ 1294 CAN_TX_TRACK_ONCOMING 1 "Oncoming" 0 "NotOncoming" ;
VAL_ 1294 CAN_TX_TRACK_BRIDGE_OBJECT 1 "Bridge" 0 "Not_Bridge" ;
VAL_ 1294 CAN_TX_TRACK_STATUS 7 "New_Coasted_Target" 6 "Invalid_Coasted_Target" 5 "Merged_Target" 4 "Coasted_Target" 3 "Updated_Target" 2 "New_Updated_Target" 1 "New_Target" 0 "No_Target" ;
VAL_ 1294 CAN_TX_TRACK_MED_RANGE_MODE 3 "Both_MR_LR_Update" 2 "LR_Update_Only" 1 "MR_Update_Only" 0 "No_MR_LR_Update" ;
VAL_ 1302 CAN_TX_TRACK_GROUPING_CHANGED 1 "GroupingChanged" 0 "GroupingUnchanged" ;
VAL_ 1302 CAN_TX_TRACK_ONCOMING 1 "Oncoming" 0 "NotOncoming" ;
VAL_ 1302 CAN_TX_TRACK_BRIDGE_OBJECT 1 "Bridge" 0 "Not_Bridge" ;
VAL_ 1302 CAN_TX_TRACK_STATUS 7 "New_Coasted_Target" 6 "Invalid_Coasted_Target" 5 "Merged_Target" 4 "Coasted_Target" 3 "Updated_Target" 2 "New_Updated_Target" 1 "New_Target" 0 "No_Target" ;
VAL_ 1302 CAN_TX_TRACK_MED_RANGE_MODE 3 "Both_MR_LR_Update" 2 "LR_Update_Only" 1 "MR_Update_Only" 0 "No_MR_LR_Update" ;
VAL_ 1287 CAN_TX_TRACK_GROUPING_CHANGED 1 "GroupingChanged" 0 "GroupingUnchanged" ;
VAL_ 1287 CAN_TX_TRACK_ONCOMING 1 "Oncoming" 0 "NotOncoming" ;
VAL_ 1287 CAN_TX_TRACK_BRIDGE_OBJECT 1 "Bridge" 0 "Not_Bridge" ;
VAL_ 1287 CAN_TX_TRACK_STATUS 7 "New_Coasted_Target" 6 "Invalid_Coasted_Target" 5 "Merged_Target" 4 "Coasted_Target" 3 "Updated_Target" 2 "New_Updated_Target" 1 "New_Target" 0 "No_Target" ;
VAL_ 1287 CAN_TX_TRACK_MED_RANGE_MODE 3 "Both_MR_LR_Update" 2 "LR_Update_Only" 1 "MR_Update_Only" 0 "No_MR_LR_Update" ;
VAL_ 1304 CAN_TX_TRACK_GROUPING_CHANGED 1 "GroupingChanged" 0 "GroupingUnchanged" ;
VAL_ 1304 CAN_TX_TRACK_ONCOMING 1 "Oncoming" 0 "NotOncoming" ;
VAL_ 1304 CAN_TX_TRACK_BRIDGE_OBJECT 1 "Bridge" 0 "Not_Bridge" ;
VAL_ 1304 CAN_TX_TRACK_STATUS 7 "New_Coasted_Target" 6 "Invalid_Coasted_Target" 5 "Merged_Target" 4 "Coasted_Target" 3 "Updated_Target" 2 "New_Updated_Target" 1 "New_Target" 0 "No_Target" ;
VAL_ 1304 CAN_TX_TRACK_MED_RANGE_MODE 3 "Both_MR_LR_Update" 2 "LR_Update_Only" 1 "MR_Update_Only" 0 "No_MR_LR_Update" ;
VAL_ 1313 CAN_TX_TRACK_GROUPING_CHANGED 1 "GroupingChanged" 0 "GroupingUnchanged" ;
VAL_ 1313 CAN_TX_TRACK_ONCOMING 1 "Oncoming" 0 "NotOncoming" ;
VAL_ 1313 CAN_TX_TRACK_BRIDGE_OBJECT 1 "Bridge" 0 "Not_Bridge" ;
VAL_ 1313 CAN_TX_TRACK_STATUS 7 "New_Coasted_Target" 6 "Invalid_Coasted_Target" 5 "Merged_Target" 4 "Coasted_Target" 3 "Updated_Target" 2 "New_Updated_Target" 1 "New_Target" 0 "No_Target" ;
VAL_ 1313 CAN_TX_TRACK_MED_RANGE_MODE 3 "Both_MR_LR_Update" 2 "LR_Update_Only" 1 "MR_Update_Only" 0 "No_MR_LR_Update" ;
VAL_ 1315 CAN_TX_TRACK_GROUPING_CHANGED 1 "GroupingChanged" 0 "GroupingUnchanged" ;
VAL_ 1315 CAN_TX_TRACK_ONCOMING 1 "Oncoming" 0 "NotOncoming" ;
VAL_ 1315 CAN_TX_TRACK_BRIDGE_OBJECT 1 "Bridge" 0 "Not_Bridge" ;
VAL_ 1315 CAN_TX_TRACK_STATUS 7 "New_Coasted_Target" 6 "Invalid_Coasted_Target" 5 "Merged_Target" 4 "Coasted_Target" 3 "Updated_Target" 2 "New_Updated_Target" 1 "New_Target" 0 "No_Target" ;
VAL_ 1315 CAN_TX_TRACK_MED_RANGE_MODE 3 "Both_MR_LR_Update" 2 "LR_Update_Only" 1 "MR_Update_Only" 0 "No_MR_LR_Update" ;
VAL_ 1343 CAN_TX_TRACK_GROUPING_CHANGED 1 "GroupingChanged" 0 "GroupingUnchanged" ;
VAL_ 1343 CAN_TX_TRACK_ONCOMING 1 "Oncoming" 0 "NotOncoming" ;
VAL_ 1343 CAN_TX_TRACK_BRIDGE_OBJECT 1 "Bridge" 0 "Not_Bridge" ;
VAL_ 1343 CAN_TX_TRACK_STATUS 7 "New_Coasted_Target" 6 "Invalid_Coasted_Target" 5 "Merged_Target" 4 "Coasted_Target" 3 "Updated_Target" 2 "New_Updated_Target" 1 "New_Target" 0 "No_Target" ;
VAL_ 1343 CAN_TX_TRACK_MED_RANGE_MODE 3 "Both_MR_LR_Update" 2 "LR_Update_Only" 1 "MR_Update_Only" 0 "No_MR_LR_Update" ;
VAL_ 1314 CAN_TX_TRACK_GROUPING_CHANGED 1 "GroupingChanged" 0 "GroupingUnchanged" ;
VAL_ 1314 CAN_TX_TRACK_ONCOMING 1 "Oncoming" 0 "NotOncoming" ;
VAL_ 1314 CAN_TX_TRACK_BRIDGE_OBJECT 1 "Bridge" 0 "Not_Bridge" ;
VAL_ 1314 CAN_TX_TRACK_STATUS 7 "New_Coasted_Target" 6 "Invalid_Coasted_Target" 5 "Merged_Target" 4 "Coasted_Target" 3 "Updated_Target" 2 "New_Updated_Target" 1 "New_Target" 0 "No_Target" ;
VAL_ 1314 CAN_TX_TRACK_MED_RANGE_MODE 3 "Both_MR_LR_Update" 2 "LR_Update_Only" 1 "MR_Update_Only" 0 "No_MR_LR_Update" ;
VAL_ 1332 CAN_TX_TRACK_GROUPING_CHANGED 1 "GroupingChanged" 0 "GroupingUnchanged" ;
VAL_ 1332 CAN_TX_TRACK_ONCOMING 1 "Oncoming" 0 "NotOncoming" ;
VAL_ 1332 CAN_TX_TRACK_BRIDGE_OBJECT 1 "Bridge" 0 "Not_Bridge" ;
VAL_ 1332 CAN_TX_TRACK_STATUS 7 "New_Coasted_Target" 6 "Invalid_Coasted_Target" 5 "Merged_Target" 4 "Coasted_Target" 3 "Updated_Target" 2 "New_Updated_Target" 1 "New_Target" 0 "No_Target" ;
VAL_ 1332 CAN_TX_TRACK_MED_RANGE_MODE 3 "Both_MR_LR_Update" 2 "LR_Update_Only" 1 "MR_Update_Only" 0 "No_MR_LR_Update" ;
VAL_ 1316 CAN_TX_TRACK_GROUPING_CHANGED 1 "GroupingChanged" 0 "GroupingUnchanged" ;
VAL_ 1316 CAN_TX_TRACK_ONCOMING 1 "Oncoming" 0 "NotOncoming" ;
VAL_ 1316 CAN_TX_TRACK_BRIDGE_OBJECT 1 "Bridge" 0 "Not_Bridge" ;
VAL_ 1316 CAN_TX_TRACK_STATUS 7 "New_Coasted_Target" 6 "Invalid_Coasted_Target" 5 "Merged_Target" 4 "Coasted_Target" 3 "Updated_Target" 2 "New_Updated_Target" 1 "New_Target" 0 "No_Target" ;
VAL_ 1316 CAN_TX_TRACK_MED_RANGE_MODE 3 "Both_MR_LR_Update" 2 "LR_Update_Only" 1 "MR_Update_Only" 0 "No_MR_LR_Update" ;
VAL_ 1317 CAN_TX_TRACK_GROUPING_CHANGED 1 "GroupingChanged" 0 "GroupingUnchanged" ;
VAL_ 1317 CAN_TX_TRACK_ONCOMING 1 "Oncoming" 0 "NotOncoming" ;
VAL_ 1317 CAN_TX_TRACK_BRIDGE_OBJECT 1 "Bridge" 0 "Not_Bridge" ;
VAL_ 1317 CAN_TX_TRACK_STATUS 7 "New_Coasted_Target" 6 "Invalid_Coasted_Target" 5 "Merged_Target" 4 "Coasted_Target" 3 "Updated_Target" 2 "New_Updated_Target" 1 "New_Target" 0 "No_Target" ;
VAL_ 1317 CAN_TX_TRACK_MED_RANGE_MODE 3 "Both_MR_LR_Update" 2 "LR_Update_Only" 1 "MR_Update_Only" 0 "No_MR_LR_Update" ;
VAL_ 1327 CAN_TX_TRACK_GROUPING_CHANGED 1 "GroupingChanged" 0 "GroupingUnchanged" ;
VAL_ 1327 CAN_TX_TRACK_ONCOMING 1 "Oncoming" 0 "NotOncoming" ;
VAL_ 1327 CAN_TX_TRACK_BRIDGE_OBJECT 1 "Bridge" 0 "Not_Bridge" ;
VAL_ 1327 CAN_TX_TRACK_STATUS 7 "New_Coasted_Target" 6 "Invalid_Coasted_Target" 5 "Merged_Target" 4 "Coasted_Target" 3 "Updated_Target" 2 "New_Updated_Target" 1 "New_Target" 0 "No_Target" ;
VAL_ 1327 CAN_TX_TRACK_MED_RANGE_MODE 3 "Both_MR_LR_Update" 2 "LR_Update_Only" 1 "MR_Update_Only" 0 "No_MR_LR_Update" ;
VAL_ 1324 CAN_TX_TRACK_GROUPING_CHANGED 1 "GroupingChanged" 0 "GroupingUnchanged" ;
VAL_ 1324 CAN_TX_TRACK_ONCOMING 1 "Oncoming" 0 "NotOncoming" ;
VAL_ 1324 CAN_TX_TRACK_BRIDGE_OBJECT 1 "Bridge" 0 "Not_Bridge" ;
VAL_ 1324 CAN_TX_TRACK_STATUS 7 "New_Coasted_Target" 6 "Invalid_Coasted_Target" 5 "Merged_Target" 4 "Coasted_Target" 3 "Updated_Target" 2 "New_Updated_Target" 1 "New_Target" 0 "No_Target" ;
VAL_ 1324 CAN_TX_TRACK_MED_RANGE_MODE 3 "Both_MR_LR_Update" 2 "LR_Update_Only" 1 "MR_Update_Only" 0 "No_MR_LR_Update" ;
VAL_ 1339 CAN_TX_TRACK_GROUPING_CHANGED 1 "GroupingChanged" 0 "GroupingUnchanged" ;
VAL_ 1339 CAN_TX_TRACK_ONCOMING 1 "Oncoming" 0 "NotOncoming" ;
VAL_ 1339 CAN_TX_TRACK_BRIDGE_OBJECT 1 "Bridge" 0 "Not_Bridge" ;
VAL_ 1339 CAN_TX_TRACK_STATUS 7 "New_Coasted_Target" 6 "Invalid_Coasted_Target" 5 "Merged_Target" 4 "Coasted_Target" 3 "Updated_Target" 2 "New_Updated_Target" 1 "New_Target" 0 "No_Target" ;
VAL_ 1339 CAN_TX_TRACK_MED_RANGE_MODE 3 "Both_MR_LR_Update" 2 "LR_Update_Only" 1 "MR_Update_Only" 0 "No_MR_LR_Update" ;
VAL_ 1322 CAN_TX_TRACK_GROUPING_CHANGED 1 "GroupingChanged" 0 "GroupingUnchanged" ;
VAL_ 1322 CAN_TX_TRACK_ONCOMING 1 "Oncoming" 0 "NotOncoming" ;
VAL_ 1322 CAN_TX_TRACK_BRIDGE_OBJECT 1 "Bridge" 0 "Not_Bridge" ;
VAL_ 1322 CAN_TX_TRACK_STATUS 7 "New_Coasted_Target" 6 "Invalid_Coasted_Target" 5 "Merged_Target" 4 "Coasted_Target" 3 "Updated_Target" 2 "New_Updated_Target" 1 "New_Target" 0 "No_Target" ;
VAL_ 1322 CAN_TX_TRACK_MED_RANGE_MODE 3 "Both_MR_LR_Update" 2 "LR_Update_Only" 1 "MR_Update_Only" 0 "No_MR_LR_Update" ;
VAL_ 1318 CAN_TX_TRACK_GROUPING_CHANGED 1 "GroupingChanged" 0 "GroupingUnchanged" ;
VAL_ 1318 CAN_TX_TRACK_ONCOMING 1 "Oncoming" 0 "NotOncoming" ;
VAL_ 1318 CAN_TX_TRACK_BRIDGE_OBJECT 1 "Bridge" 0 "Not_Bridge" ;
VAL_ 1318 CAN_TX_TRACK_STATUS 7 "New_Coasted_Target" 6 "Invalid_Coasted_Target" 5 "Merged_Target" 4 "Coasted_Target" 3 "Updated_Target" 2 "New_Updated_Target" 1 "New_Target" 0 "No_Target" ;
VAL_ 1318 CAN_TX_TRACK_MED_RANGE_MODE 3 "Both_MR_LR_Update" 2 "LR_Update_Only" 1 "MR_Update_Only" 0 "No_MR_LR_Update" ;
VAL_ 1321 CAN_TX_TRACK_GROUPING_CHANGED 1 "GroupingChanged" 0 "GroupingUnchanged" ;
VAL_ 1321 CAN_TX_TRACK_ONCOMING 1 "Oncoming" 0 "NotOncoming" ;
VAL_ 1321 CAN_TX_TRACK_BRIDGE_OBJECT 1 "Bridge" 0 "Not_Bridge" ;
VAL_ 1321 CAN_TX_TRACK_STATUS 7 "New_Coasted_Target" 6 "Invalid_Coasted_Target" 5 "Merged_Target" 4 "Coasted_Target" 3 "Updated_Target" 2 "New_Updated_Target" 1 "New_Target" 0 "No_Target" ;
VAL_ 1321 CAN_TX_TRACK_MED_RANGE_MODE 3 "Both_MR_LR_Update" 2 "LR_Update_Only" 1 "MR_Update_Only" 0 "No_MR_LR_Update" ;
VAL_ 1320 CAN_TX_TRACK_GROUPING_CHANGED 1 "GroupingChanged" 0 "GroupingUnchanged" ;
VAL_ 1320 CAN_TX_TRACK_ONCOMING 1 "Oncoming" 0 "NotOncoming" ;
VAL_ 1320 CAN_TX_TRACK_BRIDGE_OBJECT 1 "Bridge" 0 "Not_Bridge" ;
VAL_ 1320 CAN_TX_TRACK_STATUS 7 "New_Coasted_Target" 6 "Invalid_Coasted_Target" 5 "Merged_Target" 4 "Coasted_Target" 3 "Updated_Target" 2 "New_Updated_Target" 1 "New_Target" 0 "No_Target" ;
VAL_ 1320 CAN_TX_TRACK_MED_RANGE_MODE 3 "Both_MR_LR_Update" 2 "LR_Update_Only" 1 "MR_Update_Only" 0 "No_MR_LR_Update" ;
VAL_ 1319 CAN_TX_TRACK_GROUPING_CHANGED 1 "GroupingChanged" 0 "GroupingUnchanged" ;
VAL_ 1319 CAN_TX_TRACK_ONCOMING 1 "Oncoming" 0 "NotOncoming" ;
VAL_ 1319 CAN_TX_TRACK_BRIDGE_OBJECT 1 "Bridge" 0 "Not_Bridge" ;
VAL_ 1319 CAN_TX_TRACK_STATUS 7 "New_Coasted_Target" 6 "Invalid_Coasted_Target" 5 "Merged_Target" 4 "Coasted_Target" 3 "Updated_Target" 2 "New_Updated_Target" 1 "New_Target" 0 "No_Target" ;
VAL_ 1319 CAN_TX_TRACK_MED_RANGE_MODE 3 "Both_MR_LR_Update" 2 "LR_Update_Only" 1 "MR_Update_Only" 0 "No_MR_LR_Update" ;
VAL_ 1323 CAN_TX_TRACK_GROUPING_CHANGED 1 "GroupingChanged" 0 "GroupingUnchanged" ;
VAL_ 1323 CAN_TX_TRACK_ONCOMING 1 "Oncoming" 0 "NotOncoming" ;
VAL_ 1323 CAN_TX_TRACK_BRIDGE_OBJECT 1 "Bridge" 0 "Not_Bridge" ;
VAL_ 1323 CAN_TX_TRACK_STATUS 7 "New_Coasted_Target" 6 "Invalid_Coasted_Target" 5 "Merged_Target" 4 "Coasted_Target" 3 "Updated_Target" 2 "New_Updated_Target" 1 "New_Target" 0 "No_Target" ;
VAL_ 1323 CAN_TX_TRACK_MED_RANGE_MODE 3 "Both_MR_LR_Update" 2 "LR_Update_Only" 1 "MR_Update_Only" 0 "No_MR_LR_Update" ;
VAL_ 1329 CAN_TX_TRACK_GROUPING_CHANGED 1 "GroupingChanged" 0 "GroupingUnchanged" ;
VAL_ 1329 CAN_TX_TRACK_ONCOMING 1 "Oncoming" 0 "NotOncoming" ;
VAL_ 1329 CAN_TX_TRACK_BRIDGE_OBJECT 1 "Bridge" 0 "Not_Bridge" ;
VAL_ 1329 CAN_TX_TRACK_STATUS 7 "New_Coasted_Target" 6 "Invalid_Coasted_Target" 5 "Merged_Target" 4 "Coasted_Target" 3 "Updated_Target" 2 "New_Updated_Target" 1 "New_Target" 0 "No_Target" ;
VAL_ 1329 CAN_TX_TRACK_MED_RANGE_MODE 3 "Both_MR_LR_Update" 2 "LR_Update_Only" 1 "MR_Update_Only" 0 "No_MR_LR_Update" ;
VAL_ 1326 CAN_TX_TRACK_GROUPING_CHANGED 1 "GroupingChanged" 0 "GroupingUnchanged" ;
VAL_ 1326 CAN_TX_TRACK_ONCOMING 1 "Oncoming" 0 "NotOncoming" ;
VAL_ 1326 CAN_TX_TRACK_BRIDGE_OBJECT 1 "Bridge" 0 "Not_Bridge" ;
VAL_ 1326 CAN_TX_TRACK_STATUS 7 "New_Coasted_Target" 6 "Invalid_Coasted_Target" 5 "Merged_Target" 4 "Coasted_Target" 3 "Updated_Target" 2 "New_Updated_Target" 1 "New_Target" 0 "No_Target" ;
VAL_ 1326 CAN_TX_TRACK_MED_RANGE_MODE 3 "Both_MR_LR_Update" 2 "LR_Update_Only" 1 "MR_Update_Only" 0 "No_MR_LR_Update" ;
VAL_ 1342 CAN_TX_TRACK_GROUPING_CHANGED 1 "GroupingChanged" 0 "GroupingUnchanged" ;
VAL_ 1342 CAN_TX_TRACK_ONCOMING 1 "Oncoming" 0 "NotOncoming" ;
VAL_ 1342 CAN_TX_TRACK_BRIDGE_OBJECT 1 "Bridge" 0 "Not_Bridge" ;
VAL_ 1342 CAN_TX_TRACK_STATUS 7 "New_Coasted_Target" 6 "Invalid_Coasted_Target" 5 "Merged_Target" 4 "Coasted_Target" 3 "Updated_Target" 2 "New_Updated_Target" 1 "New_Target" 0 "No_Target" ;
VAL_ 1342 CAN_TX_TRACK_MED_RANGE_MODE 3 "Both_MR_LR_Update" 2 "LR_Update_Only" 1 "MR_Update_Only" 0 "No_MR_LR_Update" ;
VAL_ 1340 CAN_TX_TRACK_GROUPING_CHANGED 1 "GroupingChanged" 0 "GroupingUnchanged" ;
VAL_ 1340 CAN_TX_TRACK_ONCOMING 1 "Oncoming" 0 "NotOncoming" ;
VAL_ 1340 CAN_TX_TRACK_BRIDGE_OBJECT 1 "Bridge" 0 "Not_Bridge" ;
VAL_ 1340 CAN_TX_TRACK_STATUS 7 "New_Coasted_Target" 6 "Invalid_Coasted_Target" 5 "Merged_Target" 4 "Coasted_Target" 3 "Updated_Target" 2 "New_Updated_Target" 1 "New_Target" 0 "No_Target" ;
VAL_ 1340 CAN_TX_TRACK_MED_RANGE_MODE 3 "Both_MR_LR_Update" 2 "LR_Update_Only" 1 "MR_Update_Only" 0 "No_MR_LR_Update" ;
VAL_ 1333 CAN_TX_TRACK_GROUPING_CHANGED 1 "GroupingChanged" 0 "GroupingUnchanged" ;
VAL_ 1333 CAN_TX_TRACK_ONCOMING 1 "Oncoming" 0 "NotOncoming" ;
VAL_ 1333 CAN_TX_TRACK_BRIDGE_OBJECT 1 "Bridge" 0 "Not_Bridge" ;
VAL_ 1333 CAN_TX_TRACK_STATUS 7 "New_Coasted_Target" 6 "Invalid_Coasted_Target" 5 "Merged_Target" 4 "Coasted_Target" 3 "Updated_Target" 2 "New_Updated_Target" 1 "New_Target" 0 "No_Target" ;
VAL_ 1333 CAN_TX_TRACK_MED_RANGE_MODE 3 "Both_MR_LR_Update" 2 "LR_Update_Only" 1 "MR_Update_Only" 0 "No_MR_LR_Update" ;
VAL_ 1335 CAN_TX_TRACK_GROUPING_CHANGED 1 "GroupingChanged" 0 "GroupingUnchanged" ;
VAL_ 1335 CAN_TX_TRACK_ONCOMING 1 "Oncoming" 0 "NotOncoming" ;
VAL_ 1335 CAN_TX_TRACK_BRIDGE_OBJECT 1 "Bridge" 0 "Not_Bridge" ;
VAL_ 1335 CAN_TX_TRACK_STATUS 7 "New_Coasted_Target" 6 "Invalid_Coasted_Target" 5 "Merged_Target" 4 "Coasted_Target" 3 "Updated_Target" 2 "New_Updated_Target" 1 "New_Target" 0 "No_Target" ;
VAL_ 1335 CAN_TX_TRACK_MED_RANGE_MODE 3 "Both_MR_LR_Update" 2 "LR_Update_Only" 1 "MR_Update_Only" 0 "No_MR_LR_Update" ;
VAL_ 1337 CAN_TX_TRACK_GROUPING_CHANGED 1 "GroupingChanged" 0 "GroupingUnchanged" ;
VAL_ 1337 CAN_TX_TRACK_ONCOMING 1 "Oncoming" 0 "NotOncoming" ;
VAL_ 1337 CAN_TX_TRACK_BRIDGE_OBJECT 1 "Bridge" 0 "Not_Bridge" ;
VAL_ 1337 CAN_TX_TRACK_STATUS 7 "New_Coasted_Target" 6 "Invalid_Coasted_Target" 5 "Merged_Target" 4 "Coasted_Target" 3 "Updated_Target" 2 "New_Updated_Target" 1 "New_Target" 0 "No_Target" ;
VAL_ 1337 CAN_TX_TRACK_MED_RANGE_MODE 3 "Both_MR_LR_Update" 2 "LR_Update_Only" 1 "MR_Update_Only" 0 "No_MR_LR_Update" ;
VAL_ 1331 CAN_TX_TRACK_GROUPING_CHANGED 1 "GroupingChanged" 0 "GroupingUnchanged" ;
VAL_ 1331 CAN_TX_TRACK_ONCOMING 1 "Oncoming" 0 "NotOncoming" ;
VAL_ 1331 CAN_TX_TRACK_BRIDGE_OBJECT 1 "Bridge" 0 "Not_Bridge" ;
VAL_ 1331 CAN_TX_TRACK_STATUS 7 "New_Coasted_Target" 6 "Invalid_Coasted_Target" 5 "Merged_Target" 4 "Coasted_Target" 3 "Updated_Target" 2 "New_Updated_Target" 1 "New_Target" 0 "No_Target" ;
VAL_ 1331 CAN_TX_TRACK_MED_RANGE_MODE 3 "Both_MR_LR_Update" 2 "LR_Update_Only" 1 "MR_Update_Only" 0 "No_MR_LR_Update" ;
VAL_ 1338 CAN_TX_TRACK_GROUPING_CHANGED 1 "GroupingChanged" 0 "GroupingUnchanged" ;
VAL_ 1338 CAN_TX_TRACK_ONCOMING 1 "Oncoming" 0 "NotOncoming" ;
VAL_ 1338 CAN_TX_TRACK_BRIDGE_OBJECT 1 "Bridge" 0 "Not_Bridge" ;
VAL_ 1338 CAN_TX_TRACK_STATUS 7 "New_Coasted_Target" 6 "Invalid_Coasted_Target" 5 "Merged_Target" 4 "Coasted_Target" 3 "Updated_Target" 2 "New_Updated_Target" 1 "New_Target" 0 "No_Target" ;
VAL_ 1338 CAN_TX_TRACK_MED_RANGE_MODE 3 "Both_MR_LR_Update" 2 "LR_Update_Only" 1 "MR_Update_Only" 0 "No_MR_LR_Update" ;
VAL_ 1336 CAN_TX_TRACK_GROUPING_CHANGED 1 "GroupingChanged" 0 "GroupingUnchanged" ;
VAL_ 1336 CAN_TX_TRACK_ONCOMING 1 "Oncoming" 0 "NotOncoming" ;
VAL_ 1336 CAN_TX_TRACK_BRIDGE_OBJECT 1 "Bridge" 0 "Not_Bridge" ;
VAL_ 1336 CAN_TX_TRACK_STATUS 7 "New_Coasted_Target" 6 "Invalid_Coasted_Target" 5 "Merged_Target" 4 "Coasted_Target" 3 "Updated_Target" 2 "New_Updated_Target" 1 "New_Target" 0 "No_Target" ;
VAL_ 1336 CAN_TX_TRACK_MED_RANGE_MODE 3 "Both_MR_LR_Update" 2 "LR_Update_Only" 1 "MR_Update_Only" 0 "No_MR_LR_Update" ;
VAL_ 1334 CAN_TX_TRACK_GROUPING_CHANGED 1 "GroupingChanged" 0 "GroupingUnchanged" ;
VAL_ 1334 CAN_TX_TRACK_ONCOMING 1 "Oncoming" 0 "NotOncoming" ;
VAL_ 1334 CAN_TX_TRACK_BRIDGE_OBJECT 1 "Bridge" 0 "Not_Bridge" ;
VAL_ 1334 CAN_TX_TRACK_STATUS 7 "New_Coasted_Target" 6 "Invalid_Coasted_Target" 5 "Merged_Target" 4 "Coasted_Target" 3 "Updated_Target" 2 "New_Updated_Target" 1 "New_Target" 0 "No_Target" ;
VAL_ 1334 CAN_TX_TRACK_MED_RANGE_MODE 3 "Both_MR_LR_Update" 2 "LR_Update_Only" 1 "MR_Update_Only" 0 "No_MR_LR_Update" ;
VAL_ 1330 CAN_TX_TRACK_GROUPING_CHANGED 1 "GroupingChanged" 0 "GroupingUnchanged" ;
VAL_ 1330 CAN_TX_TRACK_ONCOMING 1 "Oncoming" 0 "NotOncoming" ;
VAL_ 1330 CAN_TX_TRACK_BRIDGE_OBJECT 1 "Bridge" 0 "Not_Bridge" ;
VAL_ 1330 CAN_TX_TRACK_STATUS 7 "New_Coasted_Target" 6 "Invalid_Coasted_Target" 5 "Merged_Target" 4 "Coasted_Target" 3 "Updated_Target" 2 "New_Updated_Target" 1 "New_Target" 0 "No_Target" ;
VAL_ 1330 CAN_TX_TRACK_MED_RANGE_MODE 3 "Both_MR_LR_Update" 2 "LR_Update_Only" 1 "MR_Update_Only" 0 "No_MR_LR_Update" ;
VAL_ 1328 CAN_TX_TRACK_GROUPING_CHANGED 1 "GroupingChanged" 0 "GroupingUnchanged" ;
VAL_ 1328 CAN_TX_TRACK_ONCOMING 1 "Oncoming" 0 "NotOncoming" ;
VAL_ 1328 CAN_TX_TRACK_BRIDGE_OBJECT 1 "Bridge" 0 "Not_Bridge" ;
VAL_ 1328 CAN_TX_TRACK_STATUS 7 "New_Coasted_Target" 6 "Invalid_Coasted_Target" 5 "Merged_Target" 4 "Coasted_Target" 3 "Updated_Target" 2 "New_Updated_Target" 1 "New_Target" 0 "No_Target" ;
VAL_ 1328 CAN_TX_TRACK_MED_RANGE_MODE 3 "Both_MR_LR_Update" 2 "LR_Update_Only" 1 "MR_Update_Only" 0 "No_MR_LR_Update" ;
VAL_ 1282 CAN_TX_TRACK_GROUPING_CHANGED 1 "GroupingChanged" 0 "GroupingUnchanged" ;
VAL_ 1282 CAN_TX_TRACK_ONCOMING 1 "Oncoming" 0 "NotOncoming" ;
VAL_ 1282 CAN_TX_TRACK_BRIDGE_OBJECT 1 "Bridge" 0 "Not_Bridge" ;
VAL_ 1282 CAN_TX_TRACK_STATUS 7 "New_Coasted_Target" 6 "Invalid_Coasted_Target" 5 "Merged_Target" 4 "Coasted_Target" 3 "Updated_Target" 2 "New_Updated_Target" 1 "New_Target" 0 "No_Target" ;
VAL_ 1282 CAN_TX_TRACK_MED_RANGE_MODE 3 "Both_MR_LR_Update" 2 "LR_Update_Only" 1 "MR_Update_Only" 0 "No_MR_LR_Update" ;
VAL_ 1283 CAN_TX_TRACK_GROUPING_CHANGED 1 "GroupingChanged" 0 "GroupingUnchanged" ;
VAL_ 1283 CAN_TX_TRACK_ONCOMING 1 "Oncoming" 0 "NotOncoming" ;
VAL_ 1283 CAN_TX_TRACK_BRIDGE_OBJECT 1 "Bridge" 0 "Not_Bridge" ;
VAL_ 1283 CAN_TX_TRACK_STATUS 7 "New_Coasted_Target" 6 "Invalid_Coasted_Target" 5 "Merged_Target" 4 "Coasted_Target" 3 "Updated_Target" 2 "New_Updated_Target" 1 "New_Target" 0 "No_Target" ;
VAL_ 1283 CAN_TX_TRACK_MED_RANGE_MODE 3 "Both_MR_LR_Update" 2 "LR_Update_Only" 1 "MR_Update_Only" 0 "No_MR_LR_Update" ;
VAL_ 1284 CAN_TX_TRACK_GROUPING_CHANGED 1 "GroupingChanged" 0 "GroupingUnchanged" ;
VAL_ 1284 CAN_TX_TRACK_ONCOMING 1 "Oncoming" 0 "NotOncoming" ;
VAL_ 1284 CAN_TX_TRACK_BRIDGE_OBJECT 1 "Bridge" 0 "Not_Bridge" ;
VAL_ 1284 CAN_TX_TRACK_STATUS 7 "New_Coasted_Target" 6 "Invalid_Coasted_Target" 5 "Merged_Target" 4 "Coasted_Target" 3 "Updated_Target" 2 "New_Updated_Target" 1 "New_Target" 0 "No_Target" ;
VAL_ 1284 CAN_TX_TRACK_MED_RANGE_MODE 3 "Both_MR_LR_Update" 2 "LR_Update_Only" 1 "MR_Update_Only" 0 "No_MR_LR_Update" ;
VAL_ 1311 CAN_TX_TRACK_GROUPING_CHANGED 1 "GroupingChanged" 0 "GroupingUnchanged" ;
VAL_ 1311 CAN_TX_TRACK_ONCOMING 1 "Oncoming" 0 "NotOncoming" ;
VAL_ 1311 CAN_TX_TRACK_BRIDGE_OBJECT 1 "Bridge" 0 "Not_Bridge" ;
VAL_ 1311 CAN_TX_TRACK_STATUS 7 "New_Coasted_Target" 6 "Invalid_Coasted_Target" 5 "Merged_Target" 4 "Coasted_Target" 3 "Updated_Target" 2 "New_Updated_Target" 1 "New_Target" 0 "No_Target" ;
VAL_ 1311 CAN_TX_TRACK_MED_RANGE_MODE 3 "Both_MR_LR_Update" 2 "LR_Update_Only" 1 "MR_Update_Only" 0 "No_MR_LR_Update" ;
VAL_ 1290 CAN_TX_TRACK_GROUPING_CHANGED 1 "GroupingChanged" 0 "GroupingUnchanged" ;
VAL_ 1290 CAN_TX_TRACK_ONCOMING 1 "Oncoming" 0 "NotOncoming" ;
VAL_ 1290 CAN_TX_TRACK_BRIDGE_OBJECT 1 "Bridge" 0 "Not_Bridge" ;
VAL_ 1290 CAN_TX_TRACK_STATUS 7 "New_Coasted_Target" 6 "Invalid_Coasted_Target" 5 "Merged_Target" 4 "Coasted_Target" 3 "Updated_Target" 2 "New_Updated_Target" 1 "New_Target" 0 "No_Target" ;
VAL_ 1290 CAN_TX_TRACK_MED_RANGE_MODE 3 "Both_MR_LR_Update" 2 "LR_Update_Only" 1 "MR_Update_Only" 0 "No_MR_LR_Update" ;
VAL_ 1293 CAN_TX_TRACK_GROUPING_CHANGED 1 "GroupingChanged" 0 "GroupingUnchanged" ;
VAL_ 1293 CAN_TX_TRACK_ONCOMING 1 "Oncoming" 0 "NotOncoming" ;
VAL_ 1293 CAN_TX_TRACK_BRIDGE_OBJECT 1 "Bridge" 0 "Not_Bridge" ;
VAL_ 1293 CAN_TX_TRACK_STATUS 7 "New_Coasted_Target" 6 "Invalid_Coasted_Target" 5 "Merged_Target" 4 "Coasted_Target" 3 "Updated_Target" 2 "New_Updated_Target" 1 "New_Target" 0 "No_Target" ;
VAL_ 1293 CAN_TX_TRACK_MED_RANGE_MODE 3 "Both_MR_LR_Update" 2 "LR_Update_Only" 1 "MR_Update_Only" 0 "No_MR_LR_Update" ;
VAL_ 1325 CAN_TX_TRACK_GROUPING_CHANGED 1 "GroupingChanged" 0 "GroupingUnchanged" ;
VAL_ 1325 CAN_TX_TRACK_ONCOMING 1 "Oncoming" 0 "NotOncoming" ;
VAL_ 1325 CAN_TX_TRACK_BRIDGE_OBJECT 1 "Bridge" 0 "Not_Bridge" ;
VAL_ 1325 CAN_TX_TRACK_STATUS 7 "New_Coasted_Target" 6 "Invalid_Coasted_Target" 5 "Merged_Target" 4 "Coasted_Target" 3 "Updated_Target" 2 "New_Updated_Target" 1 "New_Target" 0 "No_Target" ;
VAL_ 1325 CAN_TX_TRACK_MED_RANGE_MODE 3 "Both_MR_LR_Update" 2 "LR_Update_Only" 1 "MR_Update_Only" 0 "No_MR_LR_Update" ;
VAL_ 1341 CAN_TX_TRACK_GROUPING_CHANGED 1 "GroupingChanged" 0 "GroupingUnchanged" ;
VAL_ 1341 CAN_TX_TRACK_ONCOMING 1 "Oncoming" 0 "NotOncoming" ;
VAL_ 1341 CAN_TX_TRACK_BRIDGE_OBJECT 1 "Bridge" 0 "Not_Bridge" ;
VAL_ 1341 CAN_TX_TRACK_STATUS 7 "New_Coasted_Target" 6 "Invalid_Coasted_Target" 5 "Merged_Target" 4 "Coasted_Target" 3 "Updated_Target" 2 "New_Updated_Target" 1 "New_Target" 0 "No_Target" ;
VAL_ 1341 CAN_TX_TRACK_MED_RANGE_MODE 3 "Both_MR_LR_Update" 2 "LR_Update_Only" 1 "MR_Update_Only" 0 "No_MR_LR_Update" ;
VAL_ 1281 CAN_TX_TRACK_GROUPING_CHANGED 1 "GroupingChanged" 0 "GroupingUnchanged" ;
VAL_ 1281 CAN_TX_TRACK_ONCOMING 1 "Oncoming" 0 "NotOncoming" ;
VAL_ 1281 CAN_TX_TRACK_BRIDGE_OBJECT 1 "Bridge" 0 "Not_Bridge" ;
VAL_ 1281 CAN_TX_TRACK_STATUS 7 "New_Coasted_Target" 6 "Invalid_Coasted_Target" 5 "Merged_Target" 4 "Coasted_Target" 3 "Updated_Target" 2 "New_Updated_Target" 1 "New_Target" 0 "No_Target" ;
VAL_ 1281 CAN_TX_TRACK_MED_RANGE_MODE 3 "Both_MR_LR_Update" 2 "LR_Update_Only" 1 "MR_Update_Only" 0 "No_MR_LR_Update" ;
VAL_ 1524 CAN_RX_YAW_RATE_BIAS_SHIFT 1 "Detect" 0 "No_Detect" ;
VAL_ 1522 CAN_RX_SERV_ALIGN_TYPE 1 "VOLVO_SHORT_TRACK" 0 "AUTO_OR_DEALER" ;
VAL_ 1522 CAN_RX_SERV_ALIGN_ENABLE 1 "Enabled" 0 "Disabled" ;
VAL_ 1522 CAN_RX_AUTO_ALIGN_CONVERGED 1 "Converged" 0 "Not_Converged" ;
VAL_ 1522 CAN_RX_AUTO_ALIGN_DISABLE 1 "Disabled" 0 "Enabled" ;
VAL_ 1522 CAN_RX_WHEEL_SLIP 3 "Invalid_3" 2 "Traction_Slip_Control" 1 "Brake_Slip_Control" 0 "No_Control" ;
VAL_ 1522 CAN_RX_LONG_ACCEL_VALIDITY 1 "Valid" 0 "Invalid" ;
VAL_ 1522 CAN_RX_LAT_ACCEL_VALIDITY 1 "Valid" 0 "Invalid" ;
VAL_ 1280 CAN_TX_TRACK_GROUPING_CHANGED 1 "GroupingChanged" 0 "GroupingUnchanged" ;
VAL_ 1280 CAN_TX_TRACK_ONCOMING 1 "Oncoming" 0 "NotOncoming" ;
VAL_ 1280 CAN_TX_TRACK_BRIDGE_OBJECT 1 "Bridge" 0 "Not_Bridge" ;
VAL_ 1280 CAN_TX_TRACK_STATUS 7 "New_Coasted_Target" 6 "Invalid_Coasted_Target" 5 "Merged_Target" 4 "Coasted_Target" 3 "Updated_Target" 2 "New_Updated_Target" 1 "New_Target" 0 "No_Target" ;
VAL_ 1280 CAN_TX_TRACK_MED_RANGE_MODE 3 "Both_MR_LR_Update" 2 "LR_Update_Only" 1 "MR_Update_Only" 0 "No_MR_LR_Update" ;
VAL_ 1265 CAN_RX_MR_ONLY_TRANSMIT 1 "On" 0 "Off" ;
VAL_ 1265 CAN_RX_LR_ONLY_TRANSMIT 1 "On" 0 "Off" ;
VAL_ 1265 CAN_RX_CLEAR_FAULTS 1 "On" 0 "Off" ;
VAL_ 1265 CAN_RX_USE_ANGLE_MISALIGNMENT 1 "On" 0 "Off" ;
VAL_ 1265 CAN_RX_TURN_SIGNAL_STATUS 3 "Invalid_3" 2 "Right" 1 "Left" 0 "Off" ;
VAL_ 1265 CAN_RX_BLOCKAGE_DISABLE 1 "Disabled" 0 "Enabled" ;
VAL_ 1265 CAN_RX_VEHICLE_SPEED_VALIDITY 1 "Valid" 0 "Invalid" ;
VAL_ 1265 CAN_RX_MMR_UPSIDE_DOWN 1 "Upside_Down" 0 "Right_Side_Up" ;
VAL_ 1265 CAN_RX_WIPER_STATUS 1 "On" 0 "Off" ;
VAL_ 1265 CAN_RX_RAW_DATA_ENABLE 1 "Raw" 0 "Filtered" ;
VAL_ 1265 CAN_RX_RADAR_CMD_RADIATE 1 "On" 0 "Off" ;
VAL_ 1265 CAN_RX_GROUPING_MODE 3 "Group_Moving_Stationary" 2 "Group_Stationary_Only" 1 "Group_Moving_Only" 0 "No_Grouping" ;
VAL_ 1264 CAN_RX_STEERING_ANGLE_VALIDITY 1 "Valid" 0 "Invalid" ;
VAL_ 1264 CAN_RX_STEERING_ANGLE_SIGN 1 "Clockwise" 0 "Counterclockwise" ;
VAL_ 1264 CAN_RX_STEERING_ANGLE_RATE_SIGN 1 "Clockwise" 0 "Counterclockwise" ;
VAL_ 1264 CAN_RX_YAW_RATE_VALIDITY 1 "Valid" 0 "Invalid" ;
VAL_ 1264 CAN_RX_VEHICLE_SPEED_DIRECTION 1 "Reverse" 0 "Forward" ;
